VERSION "BodyCANhs"

NS_ :

BS_:

BU_: CCM CEM DDM ETC PAM PDM POT PSMD PSMP TRM VCM Y20CCMV526M1 Vector_XXX

BO_ 1456 CcmBodyDevFr01: 8 CCM
 SG_ EndOfLineSigEquipInp : 7|32@0+ (1,0) [0|4294967295] ""  ETC
 SG_ EndOfLineSigEquipInp1 : 39|32@0+ (1,0) [0|4294967295] ""  ETC

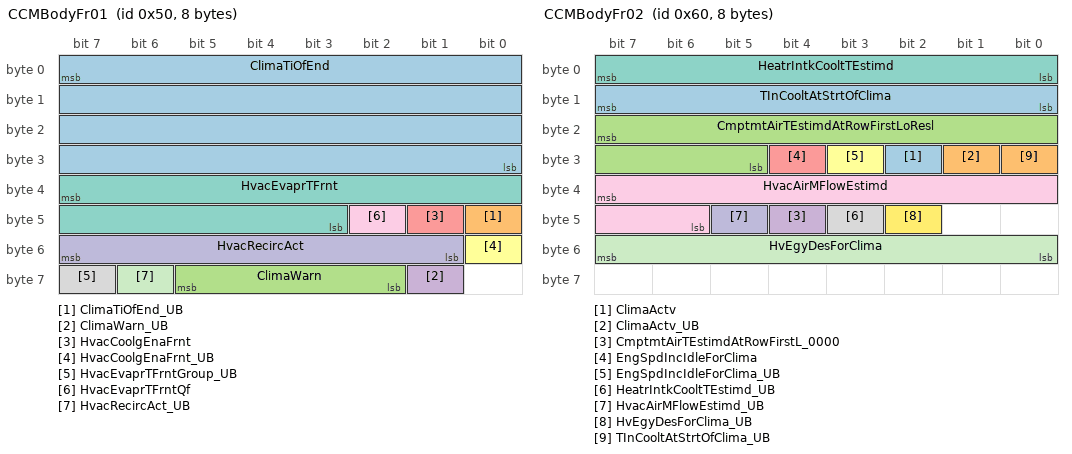
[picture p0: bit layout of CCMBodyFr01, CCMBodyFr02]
BO_ 80 CCMBodyFr01: 8 CCM
 SG_ ClimaTiOfEnd : 7|32@0+ (0.1,0) [0|429496729.5] "s"  CEM
 SG_ ClimaTiOfEnd_UB : 40|1@0+ (1,0) [0|1] ""  CEM
 SG_ ClimaWarn : 61|4@0+ (1,0) [0|15] ""  CEM,VCM
 SG_ ClimaWarn_UB : 57|1@0+ (1,0) [0|1] ""  CEM,VCM
 SG_ HvacCoolgEnaFrnt : 41|1@0+ (1,0) [0|1] ""  CEM
 SG_ HvacCoolgEnaFrnt_UB : 48|1@0+ (1,0) [0|1] ""  CEM
 SG_ HvacEvaprTFrnt : 39|13@0- (0.1,0) [-256|255.9] "degC"  CEM
 SG_ HvacEvaprTFrntGroup_UB : 63|1@0+ (1,0) [0|1] ""  CEM
 SG_ HvacEvaprTFrntQf : 42|1@0+ (1,0) [0|1] ""  CEM
 SG_ HvacRecircAct : 55|7@0+ (1,0) [0|100] "%"  CEM
 SG_ HvacRecircAct_UB : 62|1@0+ (1,0) [0|1] ""  CEM

BO_ 96 CCMBodyFr02: 8 CCM
 SG_ ClimaActv : 26|1@0+ (1,0) [0|1] ""  CEM,VCM
 SG_ ClimaActv_UB : 25|1@0+ (1,0) [0|1] ""  CEM,VCM
 SG_ CmptmtAirTEstimdAtRowFirstLoResl : 23|11@0+ (0.1,-60) [-60|125] "degC"  CEM
 SG_ CmptmtAirTEstimdAtRowFirstL_0000 : 44|1@0+ (1,0) [0|1] ""  CEM
 SG_ EngSpdIncIdleForClima : 28|1@0+ (1,0) [0|1] ""  CEM
 SG_ EngSpdIncIdleForClima_UB : 27|1@0+ (1,0) [0|1] ""  CEM
 SG_ HeatrIntkCooltTEstimd : 7|8@0+ (1,-40) [-40|215] "degC"  CEM
 SG_ HeatrIntkCooltTEstimd_UB : 43|1@0+ (1,0) [0|1] ""  CEM
 SG_ HvacAirMFlowEstimd : 39|10@0+ (1,0) [0|1000] "Kg / h"  CEM
 SG_ HvacAirMFlowEstimd_UB : 45|1@0+ (1,0) [0|1] ""  CEM
 SG_ HvEgyDesForClima : 55|8@0+ (50,0) [0|12750] "Wh"  CEM
 SG_ HvEgyDesForClima_UB : 42|1@0+ (1,0) [0|1] ""  CEM
 SG_ TInCooltAtStrtOfClima : 15|8@0+ (1,-40) [-40|215] "degC"  CEM
 SG_ TInCooltAtStrtOfClima_UB : 24|1@0+ (1,0) [0|1] ""  CEM

BO_ 336 CCMBodyFr03: 8 CCM
 SG_ AmbTEstimd_UB : 11|1@0+ (1,0) [0|1] ""  CEM
 SG_ AmbTEstimdAmbTEstimd : 7|11@0+ (0.1,-70) [-70|134.7] "degC"  CEM
 SG_ AmbTEstimdAmbTEstimdQf : 12|1@0+ (1,0) [0|1] ""  CEM
 SG_ ClimaSts : 31|1@0+ (1,0) [0|1] ""  CEM
 SG_ ClimaSts_UB : 30|1@0+ (1,0) [0|1] ""  CEM
 SG_ DefrstReq_UB : 10|1@0+ (1,0) [0|1] ""  CEM
 SG_ FuHeatrFuCns1 : 23|8@0+ (200,0) [0|51000] "MicroL"  CEM
 SG_ FuHeatrFuCns1_UB : 9|1@0+ (1,0) [0|1] ""  CEM
 SG_ HvHeatgPwrCritDes : 55|10@0+ (20,0) [0|20460] "W"  CEM
 SG_ HvHeatgPwrCritDes_UB : 61|1@0+ (1,0) [0|1] ""  CEM
 SG_ MirrDefrstReq : 26|1@0+ (1,0) [0|1] ""  CEM
 SG_ PwrEstimdAtStbForClima : 34|11@0+ (1,0) [0|2047] "W"  CEM
 SG_ PwrEstimdAtStbForClima_UB : 35|1@0+ (1,0) [0|1] ""  CEM
 SG_ WinDefrstFrntReq : 25|1@0+ (1,0) [0|1] ""  CEM
 SG_ WinDefrstReReq : 24|1@0+ (1,0) [0|1] ""  CEM
 SG_ WindIceDetdFrnt : 29|1@0+ (1,0) [0|1] ""  CEM
 SG_ WindIceDetdFrnt_UB : 28|1@0+ (1,0) [0|1] ""  CEM
 SG_ WindIceDetdRe : 27|1@0+ (1,0) [0|1] ""  CEM
 SG_ WindIceDetdRe_UB : 8|1@0+ (1,0) [0|1] ""  CEM

BO_ 368 CCMBodyFr04: 8 CCM
 SG_ CooltFlowFromWtrPmpAux : 13|6@0+ (0.5,0) [0|20] "L / min"  CEM
 SG_ CooltFlowFromWtrPmpAux_UB : 63|1@0+ (1,0) [0|1] ""  CEM
 SG_ HeatrCooltT : 47|8@0+ (1,-40) [-40|215] "degC"  CEM
 SG_ HeatrCooltT_UB : 62|1@0+ (1,0) [0|1] ""  CEM
 SG_ HvacEvaprTSpFrnt : 55|8@0+ (0.1,-5) [-5|20] ""  CEM
 SG_ HvacEvaprTSpFrnt_UB : 61|1@0+ (1,0) [0|1] ""  CEM
 SG_ HvHeatgPwrCns : 7|10@0+ (20,0) [0|20460] "W"  CEM
 SG_ HvHeatgPwrCns_UB : 60|1@0+ (1,0) [0|1] ""  CEM
 SG_ HvHeatgPwrNormDes : 23|10@0+ (20,0) [0|20460] "W"  CEM
 SG_ HvHeatgPwrNormDes_UB : 59|1@0+ (1,0) [0|1] ""  CEM
 SG_ RlyCmftForClimaReq : 28|1@0+ (1,0) [0|1] ""  CEM
 SG_ RlyCmftForClimaReq_UB : 58|1@0+ (1,0) [0|1] ""  CEM
 SG_ UBoostReqByClima : 29|1@0+ (1,0) [0|1] ""  CEM
 SG_ UBoostReqByClima_UB : 57|1@0+ (1,0) [0|1] ""  CEM
 SG_ WindDewTUppr_UB : 56|1@0+ (1,0) [0|1] ""  CEM
 SG_ WindDewTUpprDewT : 26|11@0+ (0.1,-70) [-70|134.7] "degC"  CEM
 SG_ WindDewTUpprDewTQf : 27|1@0+ (1,0) [0|1] ""  CEM

BO_ 448 CCMBodyFr05: 8 CCM
 SG_ EngHeatgReq : 47|1@0+ (1,0) [0|1] ""  CEM
 SG_ EngHeatgReq_UB : 46|1@0+ (1,0) [0|1] ""  CEM
 SG_ EvaprVlvReSts : 11|3@0+ (1,0) [0|7] ""  CEM
 SG_ EvaprVlvReSts_UB : 8|1@0+ (1,0) [0|1] ""  CEM
 SG_ EvaprVlvReStsExtd_UB : 43|1@0+ (1,0) [0|1] ""  CEM
 SG_ EvaprVlvReStsExtdDiagcStsForCirc : 61|2@0+ (1,0) [0|3] ""  CEM
 SG_ EvaprVlvReStsExtdDiagcStsForShoT : 59|2@0+ (1,0) [0|3] ""  CEM
 SG_ EvaprVlvReStsExtdDiagcStsFo_0000 : 57|2@0+ (1,0) [0|3] ""  CEM
 SG_ FuTankPRelsForFuHeatrReq : 45|1@0+ (1,0) [0|1] ""  CEM
 SG_ FuTankPRelsForFuHeatrReq_UB : 44|1@0+ (1,0) [0|1] ""  CEM
 SG_ HvacAirMFlowReEstimd : 41|10@0+ (1,0) [0|1000] "Kg / h"  CEM
 SG_ HvacAirMFlowReEstimd_UB : 42|1@0+ (1,0) [0|1] ""  CEM
 SG_ HvacCooltFlowReq : 25|10@0+ (0.05,0) [0|51.15] "L / min"  CEM
 SG_ HvacCooltFlowReq_UB : 26|1@0+ (1,0) [0|1] ""  CEM
 SG_ HvacCooltVlvReqExt : 62|1@0+ (1,0) [0|1] ""  CEM
 SG_ HvacCooltVlvReqExt_UB : 63|1@0+ (1,0) [0|1] ""  CEM
 SG_ HvacCooltVlvSts : 29|3@0+ (1,0) [0|7] ""  CEM
 SG_ HvacCooltVlvSts_UB : 30|1@0+ (1,0) [0|1] ""  CEM
 SG_ HvacHeatrPwrCns : 23|7@0+ (100,0) [0|10000] "W"  CEM
 SG_ HvacHeatrPwrCns_UB : 16|1@0+ (1,0) [0|1] ""  CEM
 SG_ WindTGroup_UB : 31|1@0+ (1,0) [0|1] ""  CEM
 SG_ WindTWindT : 7|11@0+ (0.1,-70) [-70|134.7] "degC"  CEM
 SG_ WindTWindTQf : 12|1@0+ (1,0) [0|1] ""  CEM

BO_ 272 CCMBodyFr06: 8 CCM
 SG_ ClimaPwrCns : 39|11@0+ (1,0) [0|2047] "W"  CEM
 SG_ ClimaPwrCns_UB : 44|1@0+ (1,0) [0|1] ""  CEM
 SG_ ClimaPwrCritDes : 18|11@0+ (1,0) [0|2047] "W"  CEM
 SG_ ClimaPwrCritDes_UB : 5|1@0+ (1,0) [0|1] ""  CEM
 SG_ ClimaPwrNormDes : 42|11@0+ (1,0) [0|2047] "W"  CEM
 SG_ ClimaPwrNormDes_UB : 43|1@0+ (1,0) [0|1] ""  CEM
 SG_ EngRunngReqByClima : 57|2@0+ (1,0) [0|3] ""  CEM
 SG_ EngRunngReqByClima_UB : 58|1@0+ (1,0) [0|1] ""  CEM
 SG_ HvacCoolgEnaRe : 7|1@0+ (1,0) [0|1] ""  CEM
 SG_ HvacCoolgEnaRe_UB : 6|1@0+ (1,0) [0|1] ""  CEM
 SG_ LvlOfClimaCmft : 3|3@0+ (1,0) [0|7] ""  CEM
 SG_ LvlOfClimaCmft_UB : 0|1@0+ (1,0) [0|1] ""  CEM
 SG_ PwrChrgDetdForPrkgHeatrElec : 62|1@0+ (1,0) [0|1] ""  CEM
 SG_ PwrChrgDetdForPrkgHeatrElec_UB : 61|1@0+ (1,0) [0|1] ""  CEM
 SG_ SeatHeatgAutCdn : 60|1@0+ (1,0) [0|1] ""  CEM
 SG_ SeatHeatgAutCdn_UB : 59|1@0+ (1,0) [0|1] ""  CEM
 SG_ SteerWhlHeatgAllwd : 23|5@0+ (20,0) [0|500] "W"  CEM
 SG_ SteerWhlHeatgAllwd_UB : 4|1@0+ (1,0) [0|1] ""  CEM

BO_ 576 CCMBodyFr07: 8 CCM
 SG_ ClimaStrtTi : 39|32@0+ (0.1,0) [0|429496729.5] "s"  CEM
 SG_ ClimaStrtTi_UB : 24|1@0+ (1,0) [0|1] ""  CEM
 SG_ ClimaTmrSts : 15|1@0+ (1,0) [0|1] ""  CEM
 SG_ ClimaTmrSts_UB : 14|1@0+ (1,0) [0|1] ""  CEM
 SG_ CoolgStsForDisp : 2|2@0+ (1,0) [0|3] ""  CEM
 SG_ CoolgStsForDisp_UB : 0|1@0+ (1,0) [0|1] ""  CEM
 SG_ CustClimaOvrdNotifForHmiCpt : 13|1@0+ (1,0) [0|1] ""  CEM
 SG_ CustClimaOvrdNotifForHmiCpt_UB : 12|1@0+ (1,0) [0|1] ""  CEM
 SG_ EgyDesForClima : 22|7@0+ (1,0) [0|127] "Wh"  CEM
 SG_ EgyDesForClima_UB : 23|1@0+ (1,0) [0|1] ""  CEM
 SG_ FuHeatrActv : 11|1@0+ (1,0) [0|1] ""  CEM
 SG_ FuHeatrActv_UB : 10|1@0+ (1,0) [0|1] ""  CEM
 SG_ FuHeatrFuCnsDurgCyc1 : 31|7@0+ (0.01,0) [0|1.27] "Litre"  CEM
 SG_ FuHeatrFuCnsDurgCyc1_UB : 7|1@0+ (1,0) [0|1] ""  CEM
 SG_ PostDrvgClimaAvl : 6|1@0+ (1,0) [0|1] ""  CEM
 SG_ PostDrvgClimaAvl_UB : 5|1@0+ (1,0) [0|1] ""  CEM
 SG_ RlyCrashForClimaReq : 4|1@0+ (1,0) [0|1] ""  CEM
 SG_ RlyCrashForClimaReq_UB : 3|1@0+ (1,0) [0|1] ""  CEM
 SG_ SteerWhlHeatgDurgClima : 9|1@0+ (1,0) [0|1] ""  CEM
 SG_ SteerWhlHeatgDurgClima_UB : 8|1@0+ (1,0) [0|1] ""  CEM

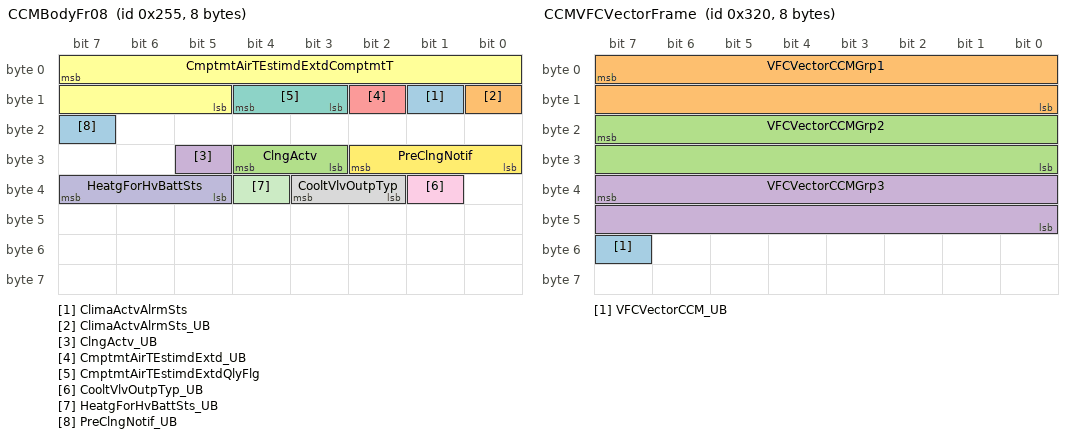
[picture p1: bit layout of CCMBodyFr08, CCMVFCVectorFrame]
BO_ 597 CCMBodyFr08: 8 CCM
 SG_ ClimaActvAlrmSts : 9|1@0+ (1,0) [0|1] ""  CEM
 SG_ ClimaActvAlrmSts_UB : 8|1@0+ (1,0) [0|1] ""  CEM
 SG_ ClngActv : 28|2@0+ (1,0) [0|3] ""  CEM,VCM
 SG_ ClngActv_UB : 29|1@0+ (1,0) [0|1] ""  CEM,VCM
 SG_ CmptmtAirTEstimdExtd_UB : 10|1@0+ (1,0) [0|1] ""  CEM
 SG_ CmptmtAirTEstimdExtdComptmtT : 7|11@0+ (0.1,-60) [-60|125] "degC"  CEM
 SG_ CmptmtAirTEstimdExtdQlyFlg : 12|2@0+ (1,0) [0|3] ""  CEM
 SG_ CooltVlvOutpTyp : 35|2@0+ (1,0) [0|3] ""  CEM
 SG_ CooltVlvOutpTyp_UB : 33|1@0+ (1,0) [0|1] ""  CEM
 SG_ HeatgForHvBattSts : 39|3@0+ (1,0) [0|7] ""  CEM
 SG_ HeatgForHvBattSts_UB : 36|1@0+ (1,0) [0|1] ""  CEM
 SG_ PreClngNotif : 26|3@0+ (1,0) [0|7] ""  CEM,VCM
 SG_ PreClngNotif_UB : 23|1@0+ (1,0) [0|1] ""  CEM,VCM

BO_ 1282 CcmBodyNMFr: 8 CCM
 SG_ PNC23_Spare1_CCM : 39|1@0+ (1,0) [0|0] ""  ETC
 SG_ PNC22_Spare2_CCM : 38|1@0+ (1,0) [0|0] ""  ETC
 SG_ PNC21_Spare3_CCM : 37|1@0+ (1,0) [0|0] ""  ETC
 SG_ PNC20_Spare4_CCM : 36|1@0+ (1,0) [0|0] ""  ETC
 SG_ PNC19_Spare5_CCM : 35|1@0+ (1,0) [0|0] ""  ETC
 SG_ PNC18_Spare6_CCM : 34|1@0+ (1,0) [0|0] ""  ETC
 SG_ PNC17_Spare7_CCM : 33|1@0+ (1,0) [0|0] ""  ETC
 SG_ PNC16_Diesel_CCM : 32|1@0+ (1,0) [0|0] ""  ETC
 SG_ PNC15_DriverInfoPoll_CCM : 31|1@0+ (1,0) [0|0] ""  ETC
 SG_ PNC14_GSD_CCM : 30|1@0+ (1,0) [0|0] ""  ETC
 SG_ PNC13_Global_CCM : 29|1@0+ (1,0) [0|0] ""  ETC
 SG_ PNC12_TrailerCaravan_CCM : 28|1@0+ (1,0) [0|0] ""  ETC
 SG_ PNC11_Driving_CCM : 27|1@0+ (1,0) [0|0] ""  ETC
 SG_ PNC10_PreClimatization_CCM : 26|1@0+ (1,0) [0|0] ""  ETC
 SG_ PNC9_Charging_CCM : 25|1@0+ (1,0) [0|0] ""  ETC
 SG_ PNC8_Start_CCM : 24|1@0+ (1,0) [0|0] ""  ETC
 SG_ PNC7_Entrance_CCM : 23|1@0+ (1,0) [0|0] ""  ETC
 SG_ PNC6_InfotainmentHMI_CCM : 22|1@0+ (1,0) [0|0] ""  ETC
 SG_ PNC5_Body_CCM : 21|1@0+ (1,0) [0|0] ""  ETC
 SG_ PNC4_Visibility_CCM : 20|1@0+ (1,0) [0|0] ""  ETC
 SG_ PNC3_WarningSounds_CCM : 19|1@0+ (1,0) [0|0] ""  ETC
 SG_ PNC2_Hazard_CCM : 18|1@0+ (1,0) [0|0] ""  ETC
 SG_ PNC1_Locking_CCM : 17|1@0+ (1,0) [0|0] ""  ETC
 SG_ PNC0_DriverInfo_CCM : 16|1@0+ (1,0) [0|0] ""  ETC
 SG_ NM_AW_CCM : 12|1@0+ (1,0) [0|0] ""  ETC
 SG_ NM_CS_CCM : 11|1@0+ (1,0) [0|0] ""  ETC
 SG_ NM_RMR_CCM : 8|1@0+ (1,0) [0|0] ""  ETC
 SG_ NM_PNI_CCM : 14|1@0+ (1,0) [0|0] ""  ETC
 SG_ NM_NodeID_CCM : 7|8@0+ (1,0) [0|0] ""  ETC

BO_ 1553 CcmToCemBodyDiagResFrame: 8 CCM

BO_ 1409 CCMtoETCXCPFr01: 8 CCM

BO_ 1410 CCMtoETCXCPFr02: 8 CCM

BO_ 1411 CCMtoETCXCPFr03: 8 CCM

BO_ 1412 CCMtoETCXCPFr04: 8 CCM

BO_ 800 CCMVFCVectorFrame: 8 CCM
 SG_ VFCVectorCCM_UB : 55|1@0+ (1,0) [0|1] ""  CEM
 SG_ VFCVectorCCMGrp1 : 7|16@0+ (1,0) [0|65535] ""  CEM
 SG_ VFCVectorCCMGrp2 : 23|16@0+ (1,0) [0|65535] ""  CEM
 SG_ VFCVectorCCMGrp3 : 39|16@0+ (1,0) [0|65535] ""  CEM

BO_ 1122 CCMY20BodyFr01: 8 Y20CCMV526M1
 SG_ HmiCmptmtAirDistbnFrntM1 : 47|3@0+ (1,0) [0|7] ""  Vector_XXX
 SG_ HmiCmptmtAirDistbnFrntM1_UB : 24|1@0+ (1,0) [0|1] ""  Vector_XXX
 SG_ HmiCmptmtCoolgReqM1 : 44|1@0+ (1,0) [0|1] ""  Vector_XXX
 SG_ HmiCmptmtCoolgReqM1_UB : 43|1@0+ (1,0) [0|1] ""  Vector_XXX
 SG_ HmiCmptmtTSpForRowFirstLeM1 : 7|5@0+ (0.5,15) [15|30.5] "Deg"  Vector_XXX
 SG_ HmiCmptmtTSpForRowFirstRiM1 : 15|5@0+ (0.5,15) [15|30.5] "Deg"  Vector_XXX
 SG_ HmiCmptmtTSpForRowSecLeM1 : 23|5@0+ (0.5,15) [15|30.5] "Deg"  Vector_XXX
 SG_ HmiCmptmtTSpForRowSecRiM1 : 31|5@0+ (0.5,15) [15|30.5] "Deg"  Vector_XXX
 SG_ HmiCmptmtTSpM1_UB : 42|1@0+ (1,0) [0|1] ""  Vector_XXX
 SG_ HmiCmptmtTSpSpclForRowFirstLeM1 : 2|2@0+ (1,0) [0|3] ""  Vector_XXX
 SG_ HmiCmptmtTSpSpclForRowFirstRiM1 : 10|2@0+ (1,0) [0|3] ""  Vector_XXX
 SG_ HmiCmptmtTSpSpclForRowSecLeM1 : 18|2@0+ (1,0) [0|3] ""  Vector_XXX
 SG_ HmiCmptmtTSpSpclForRowSecRiM1 : 26|2@0+ (1,0) [0|3] ""  Vector_XXX
 SG_ HmiDefrstMaxReqM1 : 33|2@0+ (1,0) [0|3] ""  Vector_XXX
 SG_ HmiDefrstMaxReqM1_UB : 41|1@0+ (1,0) [0|1] ""  Vector_XXX
 SG_ HmiHvacFanLvlFrntM1 : 39|4@0+ (1,0) [0|15] ""  Vector_XXX
 SG_ HmiHvacFanLvlFrntM1_UB : 40|1@0+ (1,0) [0|1] ""  Vector_XXX
 SG_ HmiHvacRecircCmdM1 : 35|2@0+ (1,0) [0|3] ""  Vector_XXX
 SG_ HmiHvacRecircCmdM1_UB : 55|1@0+ (1,0) [0|1] ""  Vector_XXX

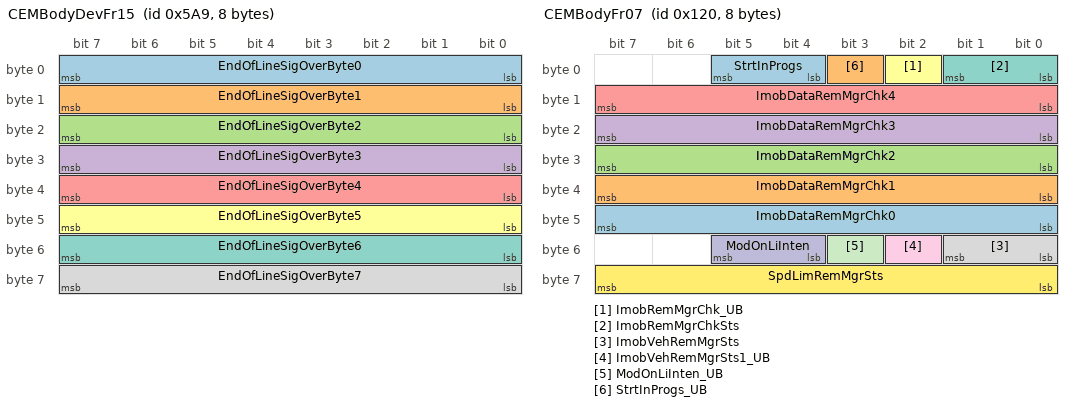
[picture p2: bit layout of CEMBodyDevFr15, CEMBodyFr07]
BO_ 1449 CEMBodyDevFr15: 8 CEM
 SG_ EndOfLineSigOverByte0 : 7|8@0+ (1,0) [0|255] ""  ETC
 SG_ EndOfLineSigOverByte1 : 15|8@0+ (1,0) [0|255] ""  ETC
 SG_ EndOfLineSigOverByte2 : 23|8@0+ (1,0) [0|255] ""  ETC
 SG_ EndOfLineSigOverByte3 : 31|8@0+ (1,0) [0|255] ""  ETC
 SG_ EndOfLineSigOverByte4 : 39|8@0+ (1,0) [0|255] ""  ETC
 SG_ EndOfLineSigOverByte5 : 47|8@0+ (1,0) [0|255] ""  ETC
 SG_ EndOfLineSigOverByte6 : 55|8@0+ (1,0) [0|255] ""  ETC
 SG_ EndOfLineSigOverByte7 : 63|8@0+ (1,0) [0|255] ""  ETC

BO_ 32 CEMBodyFr01: 8 CEM
 SG_ ActvnOfHndlDoorLi_UB : 47|1@0+ (1,0) [0|1] ""  DDM,PDM
 SG_ ActvnOfTrlrBrkLi : 60|1@0+ (1,0) [0|1] ""  TRM
 SG_ ActvnOfTrlrBrkLi_UB : 59|1@0+ (1,0) [0|1] ""  TRM
 SG_ DoorDrvrIntrSwtLedLockgReCmd : 14|1@0+ (1,0) [0|1] ""  DDM
 SG_ DoorDrvrIntrSwtLedLockgReCmd_UB : 13|1@0+ (1,0) [0|1] ""  DDM
 SG_ DoorDrvrLockCmd : 7|4@0+ (1,0) [0|15] ""  DDM
 SG_ DoorDrvrLockCmd_UB : 3|1@0+ (1,0) [0|1] ""  DDM
 SG_ DoorDrvrLockReCmd : 11|4@0+ (1,0) [0|15] ""  DDM
 SG_ DoorDrvrLockReCmd_UB : 12|1@0+ (1,0) [0|1] ""  DDM
 SG_ DoorPassIntrSwtLedLockgReCmd : 37|1@0+ (1,0) [0|1] ""  PDM
 SG_ DoorPassIntrSwtLedLockgReCmd_UB : 36|1@0+ (1,0) [0|1] ""  PDM
 SG_ DoorPassLockCmd : 23|4@0+ (1,0) [0|15] ""  PDM
 SG_ DoorPassLockCmd_UB : 19|1@0+ (1,0) [0|1] ""  PDM
 SG_ DoorPassLockReCmd : 31|4@0+ (1,0) [0|15] ""  PDM
 SG_ DoorPassLockReCmd_UB : 16|1@0+ (1,0) [0|1] ""  PDM
 SG_ EveMemPosn : 51|3@0+ (1,0) [0|7] ""  DDM,PDM,PSMD
 SG_ HndlDoorLiDrvr : 35|1@0+ (1,0) [0|1] ""  DDM,PDM
 SG_ HndlDoorLiDrvrRe : 34|1@0+ (1,0) [0|1] ""  DDM,PDM
 SG_ HndlDoorLiPass : 33|1@0+ (1,0) [0|1] ""  DDM,PDM
 SG_ HndlDoorLiPassRe : 32|1@0+ (1,0) [0|1] ""  DDM,PDM
 SG_ HvCooltHeatrEnad : 39|1@0+ (1,0) [0|1] ""  CCM
 SG_ HvCooltHeatrEnad_UB : 38|1@0+ (1,0) [0|1] ""  CCM
 SG_ IndcrTurnCmd1WdCmd_UB : 15|1@0+ (1,0) [0|1] ""  DDM,PDM,TRM
 SG_ IndcrTurnCmd1WdHzrdTelltl : 0|1@0+ (1,0) [0|1] ""  DDM,PDM,TRM
 SG_ IndcrTurnCmd1WdIndcrTrig : 2|2@0+ (1,0) [0|3] ""  DDM,PDM,TRM
 SG_ IndcrTurnSts1WdSts : 58|2@0+ (1,0) [0|3] ""  DDM,PDM,TRM
 SG_ IndcrTurnSts1WdSts_UB : 56|1@0+ (1,0) [0|1] ""  DDM,PDM,TRM
 SG_ IntrLiActvn1 : 26|1@0+ (1,0) [0|1] ""  DDM,PDM
 SG_ IntrLiCmdGroup_UB : 27|1@0+ (1,0) [0|1] ""  DDM,PDM
 SG_ IntrLiDmdOff : 18|1@0+ (1,0) [0|1] ""  DDM,PDM
 SG_ IntrLiDmdOff_UB : 17|1@0+ (1,0) [0|1] ""  DDM,PDM
 SG_ IntrLiRoofDim : 25|1@0+ (1,0) [0|1] ""  DDM,PDM
 SG_ IntrLiRoofDmdOff : 24|1@0+ (1,0) [0|1] ""  DDM,PDM
 SG_ LoadAndStoreReq_UB : 61|1@0+ (1,0) [0|1] ""  DDM,PDM,PSMD
 SG_ LoadAndStoreReqIdPen : 55|4@0+ (1,0) [0|15] ""  DDM,PDM,PSMD
 SG_ LoadAndStoreReqInOutEasy : 48|1@0+ (1,0) [0|1] ""  DDM,PDM,PSMD
 SG_ MemPosn : 63|2@0+ (1,0) [0|3] ""  DDM,PDM,PSMD

BO_ 64 CEMBodyFr02: 8 CEM
 SG_ ClimaRqrd : 47|2@0+ (1,0) [0|3] ""  CCM
 SG_ ClimaRqrd_UB : 45|1@0+ (1,0) [0|1] ""  CCM
 SG_ CllsnWarnIndcnLe : 60|2@0+ (1,0) [0|3] ""  DDM,PDM
 SG_ CllsnWarnIndcnLe_UB : 61|1@0+ (1,0) [0|1] ""  DDM,PDM
 SG_ CllsnWarnIndcnRi : 57|2@0+ (1,0) [0|3] ""  DDM,PDM
 SG_ CllsnWarnIndcnRi_UB : 58|1@0+ (1,0) [0|1] ""  DDM,PDM
 SG_ DoorDrvrIntrSwtLedLockgCmd : 31|1@0+ (1,0) [0|1] ""  DDM
 SG_ DoorDrvrIntrSwtLedLockgCmd_UB : 30|1@0+ (1,0) [0|1] ""  DDM
 SG_ DoorDrvrReSts : 43|2@0+ (1,0) [0|3] ""  CCM,DDM,PSMD,TRM,VCM
 SG_ DoorDrvrReSts_UB : 44|1@0+ (1,0) [0|1] ""  CCM,DDM,PSMD,TRM,VCM
 SG_ DoorDrvrSts : 55|2@0+ (1,0) [0|3] ""  CCM,DDM,PDM,PSMD,TRM
 SG_ DoorDrvrSts_UB : 53|1@0+ (1,0) [0|1] ""  CCM,DDM,PDM,PSMD,TRM
 SG_ DoorPassIntrSwtLedLockgCmd : 39|1@0+ (1,0) [0|1] ""  PDM
 SG_ DoorPassIntrSwtLedLockgCmd_UB : 38|1@0+ (1,0) [0|1] ""  PDM
 SG_ GlbWinCmd : 34|3@0+ (1,0) [0|7] ""  CCM,DDM,PDM
 SG_ GlbWinCmd_UB : 35|1@0+ (1,0) [0|1] ""  CCM,DDM,PDM
 SG_ LcmaIndcnLe : 51|2@0+ (1,0) [0|3] ""  DDM,PDM
 SG_ LcmaIndcnLe_UB : 52|1@0+ (1,0) [0|1] ""  DDM,PDM
 SG_ LcmaIndcnRi : 63|2@0+ (1,0) [0|3] ""  DDM,PDM
 SG_ LcmaIndcnRi_UB : 36|1@0+ (1,0) [0|1] ""  DDM,PDM
 SG_ PassLoadAndStoreReq_UB : 29|1@0+ (1,0) [0|1] ""  PSMP
 SG_ PassLoadAndStoreReqErgoPosn : 28|2@0+ (1,0) [0|3] ""  PSMP
 SG_ PassLoadAndStoreReqErgoSetgEve : 26|3@0+ (1,0) [0|7] ""  PSMP
 SG_ SaveSetgToMemPrmnt : 49|2@0+ (1,0) [0|3] ""  DDM,PDM,PSMD
 SG_ SaveSetgToMemPrmnt_UB : 37|1@0+ (1,0) [0|1] ""  DDM,PDM,PSMD
 SG_ TrNoKeyPrsntAcoustReq : 41|1@0+ (1,0) [0|1] ""  POT
 SG_ TrNoKeyPrsntAcoustReq_UB : 40|1@0+ (1,0) [0|1] ""  POT
 SG_ TrOpenerReq_UB : 21|1@0+ (1,0) [0|1] ""  POT
 SG_ TrOpenerReqTrOpenerReq : 20|2@0+ (1,0) [0|3] ""  POT
 SG_ TrOpenerReqTrOpenerTrigSrc : 18|3@0+ (1,0) [0|7] ""  POT
 SG_ TwliBriSts : 23|1@0+ (1,0) [0|1] ""  DDM,PDM,TRM,VCM
 SG_ TwliBriSts_UB : 22|1@0+ (1,0) [0|1] ""  DDM,PDM,TRM,VCM
 SG_ VehMtnStChks : 15|8@0+ (1,0) [0|255] ""  POT,TRM
 SG_ VehMtnStCntr : 6|4@0+ (1,0) [0|15] ""  POT,TRM
 SG_ VehMtnStSafe : 2|3@0+ (1,0) [0|7] ""  POT,TRM
 SG_ VehMtnStSafeGroup_UB : 7|1@0+ (1,0) [0|1] ""  POT,TRM

BO_ 243 CEMBodyFr03: 4 CEM
 SG_ CrashSts2 : 1|2@0+ (1,0) [0|3] ""  VCM
 SG_ CrashSts2_UB : 2|1@0+ (1,0) [0|1] ""  VCM

BO_ 245 CEMBodyFr04: 8 CEM
 SG_ RecOfImpctSafeChks : 7|8@0+ (1,0) [0|255] ""  VCM
 SG_ RecOfImpctSafeCntr : 15|4@0+ (1,0) [0|15] ""  VCM
 SG_ RecOfImpctSafeCrashFrnt : 11|2@0+ (1,0) [0|3] ""  VCM
 SG_ RecOfImpctSafeCrashLargeAnimal : 9|2@0+ (1,0) [0|3] ""  VCM
 SG_ RecOfImpctSafeCrashOffroadA : 23|2@0+ (1,0) [0|3] ""  VCM
 SG_ RecOfImpctSafeCrashOffroadD : 21|2@0+ (1,0) [0|3] ""  VCM
 SG_ RecOfImpctSafeCrashOffroadRT : 19|2@0+ (1,0) [0|3] ""  VCM
 SG_ RecOfImpctSafeCrashOffroadRTseve : 17|2@0+ (1,0) [0|3] ""  VCM
 SG_ RecOfImpctSafeCrashOz : 31|2@0+ (1,0) [0|3] ""  VCM
 SG_ RecOfImpctSafeCrashPed : 29|2@0+ (1,0) [0|3] ""  VCM
 SG_ RecOfImpctSafeCrashRe : 27|2@0+ (1,0) [0|3] ""  VCM
 SG_ RecOfImpctSafeCrashRollovr : 25|2@0+ (1,0) [0|3] ""  VCM
 SG_ RecOfImpctSafeCrashSideLe : 39|2@0+ (1,0) [0|3] ""  VCM
 SG_ RecOfImpctSafeCrashSideRi : 37|2@0+ (1,0) [0|3] ""  VCM
 SG_ RecOfImpctSafeCrashState : 35|2@0+ (1,0) [0|3] ""  VCM
 SG_ RecOfImpctSafeImpctDvx : 55|8@0+ (1,0) [0|255] ""  VCM
 SG_ RecOfImpctSafeImpctDvy : 63|8@0+ (1,0) [0|255] ""  VCM
 SG_ RecOfImpctSafeImpctRollAg : 33|7@0+ (15,0) [0|1905] ""  VCM
 SG_ RecOfImpctSafeVehOri : 42|3@0+ (1,0) [0|7] ""  VCM

BO_ 176 CEMBodyFr05: 8 CEM
 SG_ BltLockStAtDrvr_UB : 58|1@0+ (1,0) [0|1] ""  CCM,VCM
 SG_ BltLockStAtDrvrForBltLockSt1 : 57|1@0+ (1,0) [0|1] ""  CCM,VCM
 SG_ BltLockStAtDrvrForDevErrSts2 : 56|1@0+ (1,0) [0|1] ""  CCM,VCM
 SG_ BltLockStAtPass_UB : 42|1@0+ (1,0) [0|1] ""  CCM,VCM
 SG_ BltLockStAtPassForBltLockSt1 : 41|1@0+ (1,0) [0|1] ""  CCM,VCM
 SG_ BltLockStAtPassForBltLockSts : 40|1@0+ (1,0) [0|1] ""  CCM,VCM
 SG_ BltLockStAtRowSecLe_UB : 47|1@0+ (1,0) [0|1] ""  CCM,VCM
 SG_ BltLockStAtRowSecLeForBltLockEqu : 46|1@0+ (1,0) [0|1] ""  CCM,VCM
 SG_ BltLockStAtRowSecLeForBltLockSt1 : 45|1@0+ (1,0) [0|1] ""  CCM,VCM
 SG_ BltLockStAtRowSecLeForBltLockSts : 44|1@0+ (1,0) [0|1] ""  CCM,VCM
 SG_ BltLockStAtRowSecMid_UB : 39|1@0+ (1,0) [0|1] ""  CCM,VCM
 SG_ BltLockStAtRowSecMidForBltLockEq : 38|1@0+ (1,0) [0|1] ""  CCM,VCM
 SG_ BltLockStAtRowSecMidForBltLockSt : 37|1@0+ (1,0) [0|1] ""  CCM,VCM
 SG_ BltLockStAtRowSecMidForBltL_0000 : 36|1@0+ (1,0) [0|1] ""  CCM,VCM
 SG_ BltLockStAtRowSecRi_UB : 35|1@0+ (1,0) [0|1] ""  CCM,VCM
 SG_ BltLockStAtRowSecRiForBltLockEqu : 34|1@0+ (1,0) [0|1] ""  CCM,VCM
 SG_ BltLockStAtRowSecRiForBltLockSt1 : 33|1@0+ (1,0) [0|1] ""  CCM,VCM
 SG_ BltLockStAtRowSecRiForBltLockSts : 32|1@0+ (1,0) [0|1] ""  CCM,VCM
 SG_ BltLockStAtRowThrdLe_UB : 43|1@0+ (1,0) [0|1] ""  CCM,PSMD,VCM
 SG_ BltLockStAtRowThrdLeForBltLockEq : 50|1@0+ (1,0) [0|1] ""  CCM,PSMD,VCM
 SG_ BltLockStAtRowThrdLeForBltLockSt : 49|1@0+ (1,0) [0|1] ""  CCM,PSMD,VCM
 SG_ BltLockStAtRowThrdLeForBltL_0000 : 48|1@0+ (1,0) [0|1] ""  CCM,PSMD,VCM
 SG_ BltLockStAtRowThrdRi_UB : 27|1@0+ (1,0) [0|1] ""  CCM,PSMD,VCM
 SG_ BltLockStAtRowThrdRiForBltLockEq : 26|1@0+ (1,0) [0|1] ""  CCM,PSMD,VCM
 SG_ BltLockStAtRowThrdRiForBltLockSt : 25|1@0+ (1,0) [0|1] ""  CCM,PSMD,VCM
 SG_ BltLockStAtRowThrdRiForBltL_0000 : 24|1@0+ (1,0) [0|1] ""  CCM,PSMD,VCM
 SG_ BrkFldLvl : 29|1@0+ (1,0) [0|1] ""  VCM
 SG_ BrkFldLvl_UB : 28|1@0+ (1,0) [0|1] ""  VCM
 SG_ ChrgnTyp : 15|8@0+ (1,0) [0|255] ""  VCM
 SG_ ChrgnTyp_UB : 51|1@0+ (1,0) [0|1] ""  VCM
 SG_ EngCooltLvl : 31|1@0+ (1,0) [0|1] ""  Vector_XXX
 SG_ EngCooltLvl_UB : 30|1@0+ (1,0) [0|1] ""  Vector_XXX
 SG_ ErsStrtApplSts : 55|2@0+ (1,0) [0|3] ""  VCM
 SG_ ErsStrtApplSts_UB : 53|1@0+ (1,0) [0|1] ""  VCM
 SG_ HvEgyCnsAllwdForClima : 7|8@0+ (50,0) [0|12750] "Wh"  CCM
 SG_ HvEgyCnsAllwdForClima_UB : 52|1@0+ (1,0) [0|1] ""  CCM

BO_ 288 CEMBodyFr07: 8 CEM
 SG_ ImobDataRemMgrChk0 : 47|8@0+ (1,0) [0|255] ""  VCM
 SG_ ImobDataRemMgrChk1 : 39|8@0+ (1,0) [0|255] ""  VCM
 SG_ ImobDataRemMgrChk2 : 31|8@0+ (1,0) [0|255] ""  VCM
 SG_ ImobDataRemMgrChk3 : 23|8@0+ (1,0) [0|255] ""  VCM
 SG_ ImobDataRemMgrChk4 : 15|8@0+ (1,0) [0|255] ""  VCM
 SG_ ImobRemMgrChk_UB : 2|1@0+ (1,0) [0|1] ""  VCM
 SG_ ImobRemMgrChkSts : 1|2@0+ (1,0) [0|3] ""  VCM
 SG_ ImobVehRemMgrSts : 49|2@0+ (1,0) [0|3] ""  VCM
 SG_ ImobVehRemMgrSts1_UB : 50|1@0+ (1,0) [0|1] ""  VCM
 SG_ ModOnLiInten : 53|2@0+ (1,0) [0|3] ""  DDM,PDM
 SG_ ModOnLiInten_UB : 51|1@0+ (1,0) [0|1] ""  DDM,PDM
 SG_ SpdLimRemMgrSts : 63|8@0+ (1,0) [0|255] ""  VCM
 SG_ StrtInProgs : 5|2@0+ (1,0) [0|3] ""  CCM
 SG_ StrtInProgs_UB : 3|1@0+ (1,0) [0|1] ""  CCM

BO_ 224 CEMBodyFr11: 8 CEM
 SG_ ActvnOfTrlrFogLiCmd : 59|1@0+ (1,0) [0|1] ""  TRM
 SG_ ActvnOfTrlrFogLiCmd_UB : 60|1@0+ (1,0) [0|1] ""  TRM
 SG_ CmptmtClngPreStrtReq : 11|2@0+ (1,0) [0|3] ""  CCM
 SG_ CmptmtClngPreStrtReq_UB : 9|1@0+ (1,0) [0|1] ""  CCM
 SG_ DoorPassReSts : 13|2@0+ (1,0) [0|3] ""  CCM,PDM,PSMD,TRM,VCM
 SG_ DoorPassReSts_UB : 14|1@0+ (1,0) [0|1] ""  CCM,PDM,PSMD,TRM,VCM
 SG_ DoorPassSts : 31|2@0+ (1,0) [0|3] ""  CCM,DDM,PDM,PSMD,TRM,VCM
 SG_ DoorPassSts_UB : 29|1@0+ (1,0) [0|1] ""  CCM,DDM,PDM,PSMD,TRM,VCM
 SG_ DrvrSeatDispMassgFct_UB : 15|1@0+ (1,0) [0|1] ""  PSMD
 SG_ DrvrSeatDispMassgFctMassgInten : 1|2@0+ (1,0) [0|3] ""  PSMD
 SG_ DrvrSeatDispMassgFctMassgProg : 4|3@0+ (1,0) [0|7] ""  PSMD
 SG_ DrvrSeatDispMassgFctMassgSpdLvl : 6|2@0+ (1,0) [0|3] ""  PSMD
 SG_ DrvrSeatDispMassgFctOnOff : 7|1@0+ (1,0) [0|1] ""  PSMD
 SG_ HvPwrAvlForClimaEstimd : 25|10@0+ (20,0) [0|20460] "W"  CCM
 SG_ HvPwrAvlForClimaEstimd_UB : 26|1@0+ (1,0) [0|1] ""  CCM
 SG_ IntrBriSts : 43|4@0+ (1,0) [0|15] ""  DDM,PDM,VCM
 SG_ IntrBriSts_UB : 44|1@0+ (1,0) [0|1] ""  DDM,PDM,VCM
 SG_ MirrTintgCmd : 54|7@0+ (1,0) [0|100] "%"  DDM,PDM
 SG_ MirrTintgCmd_UB : 55|1@0+ (1,0) [0|1] ""  DDM,PDM
 SG_ PassSeatDispMassgFct_UB : 8|1@0+ (1,0) [0|1] ""  PSMP
 SG_ PassSeatDispMassgFctMassgInten : 23|2@0+ (1,0) [0|3] ""  PSMP
 SG_ PassSeatDispMassgFctMassgProg : 19|3@0+ (1,0) [0|7] ""  PSMP
 SG_ PassSeatDispMassgFctMassgSpdLvl : 21|2@0+ (1,0) [0|3] ""  PSMP
 SG_ PassSeatDispMassgFctOnOff : 16|1@0+ (1,0) [0|1] ""  PSMP
 SG_ TrlrLampChkReq : 63|2@0+ (1,0) [0|3] ""  TRM
 SG_ TrlrLampChkReq_UB : 61|1@0+ (1,0) [0|1] ""  TRM
 SG_ TrPosnUpprProgmReq : 28|1@0+ (1,0) [0|1] ""  POT
 SG_ TrPosnUpprProgmReq_UB : 27|1@0+ (1,0) [0|1] ""  POT
 SG_ TrSts : 47|2@0+ (1,0) [0|3] ""  CCM,PSMD,TRM,VCM
 SG_ TrSts_UB : 45|1@0+ (1,0) [0|1] ""  CCM,PSMD,TRM,VCM

BO_ 240 CEMBodyFr12: 8 CEM
 SG_ ActvnOfPosnReCmd : 45|2@0+ (1,0) [0|3] ""  TRM
 SG_ ActvnOfPosnReCmd_UB : 46|1@0+ (1,0) [0|1] ""  TRM
 SG_ ActvnOfWshrFrntSafe : 43|2@0+ (1,0) [0|3] ""  CCM
 SG_ ActvnOfWshrFrntSafe_UB : 47|1@0+ (1,0) [0|1] ""  CCM
 SG_ AsyFanSts : 62|1@0+ (1,0) [0|1] ""  CCM
 SG_ AsyFanSts_UB : 63|1@0+ (1,0) [0|1] ""  CCM
 SG_ CarModSts1 : 2|3@0+ (1,0) [0|7] ""  CCM,DDM,PDM,POT,PSMD,PSMP,TRM
 SG_ CarModSubtypWdCarModSubtyp : 5|3@0+ (1,0) [0|7] ""  CCM,DDM,PDM,POT,PSMD,PSMP,TRM
 SG_ DrvrCtrlOfPassSeatFrntReqd : 60|1@0+ (1,0) [0|1] ""  PSMD
 SG_ DrvrCtrlOfPassSeatFrntReqd_UB : 61|1@0+ (1,0) [0|1] ""  PSMD
 SG_ DrvrDesDir : 58|3@0+ (1,0) [0|7] ""  DDM
 SG_ DrvrDesDir_UB : 59|1@0+ (1,0) [0|1] ""  DDM
 SG_ EgyLvlElecMai : 27|4@0+ (1,0) [0|15] ""  CCM,DDM,PDM,POT,PSMD,PSMP,TRM
 SG_ EgyLvlElecSubtyp : 31|4@0+ (1,0) [0|15] ""  CCM,DDM,PDM,POT,PSMD,PSMP,TRM
 SG_ FltEgyCnsWdSts : 6|1@0+ (1,0) [0|1] ""  CCM,DDM,PDM,POT,PSMD,PSMP,TRM
 SG_ NetCtrlrActvt_UB : 41|1@0+ (1,0) [0|1] ""  Vector_XXX
 SG_ NetCtrlrActvtPrio : 40|1@0+ (1,0) [0|1] ""  Vector_XXX
 SG_ NetCtrlrActvtResourceGroup : 55|8@0+ (1,0) [0|255] ""  Vector_XXX
 SG_ PwrLvlElecMai : 19|4@0+ (1,0) [0|15] ""  CCM,DDM,PDM,POT,PSMD,PSMP,TRM
 SG_ PwrLvlElecSubtyp : 23|4@0+ (1,0) [0|15] ""  CCM,DDM,PDM,POT,PSMD,PSMP,TRM
 SG_ UsgModSts : 11|4@0+ (1,0) [0|15] ""  CCM,DDM,PDM,POT,PSMD,PSMP,TRM
 SG_ VehModMngtGlbSafe1_UB : 7|1@0+ (1,0) [0|1] ""  CCM,DDM,PDM,POT,PSMD,PSMP,TRM
 SG_ VehModMngtGlbSafe1Chks : 39|8@0+ (1,0) [0|255] ""  CCM,DDM,PDM,POT,PSMD,PSMP,TRM
 SG_ VehModMngtGlbSafe1Cntr : 15|4@0+ (1,0) [0|15] ""  CCM,DDM,PDM,POT,PSMD,PSMP,TRM

BO_ 256 CEMBodyFr13: 8 CEM
 SG_ CamHeatrActv : 6|1@0+ (1,0) [0|1] ""  CCM
 SG_ CamHeatrActv_UB : 7|1@0+ (1,0) [0|1] ""  CCM
 SG_ DefrstSts_UB : 30|1@0+ (1,0) [0|1] ""  CCM
 SG_ EngPAmbAir1 : 47|8@0+ (5,0) [0|1275] "hPa"  CCM,PSMD,PSMP
 SG_ EngPAmbAir1_UB : 36|1@0+ (1,0) [0|1] ""  CCM,PSMD,PSMP
 SG_ ExtrMirrFoldSetg_UB : 5|1@0+ (1,0) [0|1] ""  DDM
 SG_ ExtrMirrFoldSetgPen : 3|4@0+ (1,0) [0|15] ""  DDM
 SG_ ExtrMirrFoldSetgSts : 4|1@0+ (1,0) [0|1] ""  DDM
 SG_ ExtrMirrTiltSetg2_UB : 22|1@0+ (1,0) [0|1] ""  DDM
 SG_ ExtrMirrTiltSetg2IdPen : 19|4@0+ (1,0) [0|15] ""  DDM
 SG_ ExtrMirrTiltSetg2MirrDrvr : 20|1@0+ (1,0) [0|1] ""  DDM
 SG_ ExtrMirrTiltSetg2MirrPass : 21|1@0+ (1,0) [0|1] ""  DDM
 SG_ HoodSts : 49|2@0+ (1,0) [0|3] ""  VCM
 SG_ HoodSts_UB : 50|1@0+ (1,0) [0|1] ""  VCM
 SG_ LockgCenSts_UB : 8|1@0+ (1,0) [0|1] ""  CCM,DDM
 SG_ LockgCenStsForUsrFb : 34|3@0+ (1,0) [0|7] ""  VCM
 SG_ LockgCenStsForUsrFb_UB : 35|1@0+ (1,0) [0|1] ""  VCM
 SG_ LockgCenStsLockSt : 11|2@0+ (1,0) [0|3] ""  CCM,DDM
 SG_ LockgCenStsUpdEve : 9|1@0+ (1,0) [0|1] ""  CCM,DDM
 SG_ LockgCenTrigSrc : 15|4@0+ (1,0) [0|15] ""  CCM,DDM
 SG_ MirrDefrstSts : 29|3@0+ (1,0) [0|7] ""  CCM
 SG_ SteerWhlHeatgPwrAct : 63|5@0+ (20,0) [0|500] "W"  CCM
 SG_ SteerWhlHeatgPwrAct_UB : 58|1@0+ (1,0) [0|1] ""  CCM
 SG_ WindDefrstFrntSts : 26|3@0+ (1,0) [0|7] ""  CCM
 SG_ WinDefrstReSts : 39|3@0+ (1,0) [0|7] ""  CCM

BO_ 320 CEMBodyFr14: 8 CEM
 SG_ DispBattEgyIn : 15|8@0+ (0.5,0) [0|127.5] "Wh"  VCM
 SG_ DispBattEgyIn_UB : 0|1@0+ (1,0) [0|1] ""  VCM
 SG_ DispBattEgyOut : 23|8@0+ (0.5,0) [0|127.5] "Wh"  VCM
 SG_ DispBattEgyOut_UB : 1|1@0+ (1,0) [0|1] ""  VCM
 SG_ HmiCmptmtAirDistbnFrnt : 58|3@0+ (1,0) [0|7] ""  CCM
 SG_ HmiCmptmtAirDistbnFrnt_UB : 59|1@0+ (1,0) [0|1] ""  CCM
 SG_ HmiDefrstMaxReq : 47|2@0+ (1,0) [0|3] ""  CCM
 SG_ HmiDefrstMaxReq_UB : 45|1@0+ (1,0) [0|1] ""  CCM
 SG_ HmiHvacFanLvlFrnt : 7|4@0+ (1,0) [0|15] ""  CCM
 SG_ HmiHvacFanLvlFrnt_UB : 3|1@0+ (1,0) [0|1] ""  CCM
 SG_ HmiHvacFanLvlRe : 51|4@0+ (1,0) [0|15] ""  CCM
 SG_ HmiHvacFanLvlRe_UB : 55|1@0+ (1,0) [0|1] ""  CCM
 SG_ HmiHvacRecircCmd : 53|2@0+ (1,0) [0|3] ""  CCM
 SG_ HmiHvacRecircCmd_UB : 54|1@0+ (1,0) [0|1] ""  CCM
 SG_ HmiHvacReCtrl : 63|2@0+ (1,0) [0|3] ""  CCM
 SG_ HmiHvacReCtrl_UB : 61|1@0+ (1,0) [0|1] ""  CCM
 SG_ ModOnLiCmd : 29|1@0+ (1,0) [0|1] ""  DDM,PDM
 SG_ ModOnLiCmd_UB : 30|1@0+ (1,0) [0|1] ""  DDM,PDM
 SG_ ModOnLiTCmd : 28|5@0+ (1,0) [0|22] ""  DDM,PDM
 SG_ ModOnLiTCmd_UB : 60|1@0+ (1,0) [0|1] ""  DDM,PDM
 SG_ ModOnLiTintgCmd : 35|4@0+ (1,0) [0|15] ""  DDM,PDM
 SG_ ModOnLiTintgCmd_UB : 31|1@0+ (1,0) [0|1] ""  DDM,PDM

BO_ 384 CEMBodyFr15: 8 CEM
 SG_ ActvnOfTrlrLiRvsg : 56|1@0+ (1,0) [0|1] ""  TRM
 SG_ ActvnOfTrlrLiRvsg_UB : 57|1@0+ (1,0) [0|1] ""  TRM
 SG_ ClimaEcoModRqrd : 38|1@0+ (1,0) [0|1] ""  CCM
 SG_ ClimaEcoModRqrd_UB : 39|1@0+ (1,0) [0|1] ""  CCM
 SG_ HeatrDurgDrvgReqd : 37|2@0+ (1,0) [0|3] ""  CCM
 SG_ HeatrDurgDrvgReqd_UB : 35|1@0+ (1,0) [0|1] ""  CCM
 SG_ HmiCmptmtCoolgReq : 51|1@0+ (1,0) [0|1] ""  CCM
 SG_ HmiCmptmtCoolgReq_UB : 52|1@0+ (1,0) [0|1] ""  CCM
 SG_ HmiCmptmtTSp_UB : 7|1@0+ (1,0) [0|1] ""  CCM
 SG_ HmiCmptmtTSpForRowFirstLe : 4|5@0+ (0.5,15) [15|30.5] "Deg"  CCM
 SG_ HmiCmptmtTSpForRowFirstRi : 12|5@0+ (0.5,15) [15|30.5] "Deg"  CCM
 SG_ HmiCmptmtTSpForRowSecLe : 20|5@0+ (0.5,15) [15|30.5] "Deg"  CCM
 SG_ HmiCmptmtTSpForRowSecRi : 28|5@0+ (0.5,15) [15|30.5] "Deg"  CCM
 SG_ HmiCmptmtTSpSpclForRowFirstLe : 6|2@0+ (1,0) [0|3] ""  CCM
 SG_ HmiCmptmtTSpSpclForRowFirstRi : 14|2@0+ (1,0) [0|3] ""  CCM
 SG_ HmiCmptmtTSpSpclForRowSecLe : 22|2@0+ (1,0) [0|3] ""  CCM
 SG_ HmiCmptmtTSpSpclForRowSecRi : 30|2@0+ (1,0) [0|3] ""  CCM
 SG_ HvacCooltFlowAct : 33|10@0+ (0.05,0) [0|51.15] "L / min"  CCM
 SG_ HvacCooltFlowAct_UB : 34|1@0+ (1,0) [0|1] ""  CCM
 SG_ SeatSwtLeSigThrd : 49|2@0+ (1,0) [0|3] ""  PSMD
 SG_ SeatSwtLeSigThrd_UB : 50|1@0+ (1,0) [0|1] ""  PSMD
 SG_ SeatSwtRiSigThrd : 54|2@0+ (1,0) [0|3] ""  PSMD
 SG_ SeatSwtRiSigThrd_UB : 55|1@0+ (1,0) [0|1] ""  PSMD

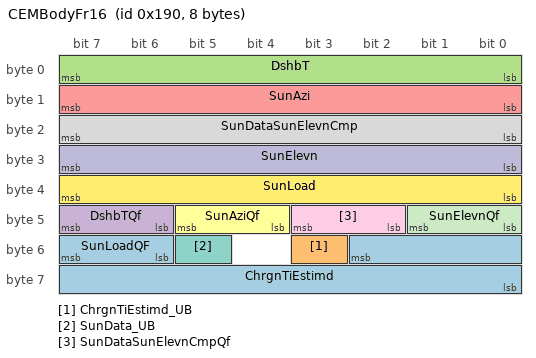
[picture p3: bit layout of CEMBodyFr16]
BO_ 400 CEMBodyFr16: 8 CEM
 SG_ ChrgnTiEstimd : 50|11@0+ (1,0) [0|2047] "Mins"  VCM
 SG_ ChrgnTiEstimd_UB : 51|1@0+ (1,0) [0|1] ""  VCM
 SG_ DshbT : 7|8@0+ (1,-40) [-40|125] "Deg"  CCM
 SG_ DshbTQf : 47|2@0+ (1,0) [0|3] ""  CCM
 SG_ SunAzi : 15|8@0+ (1.5,0) [0|358.5] "Deg"  CCM
 SG_ SunAziQf : 45|2@0+ (1,0) [0|3] ""  CCM
 SG_ SunData_UB : 53|1@0+ (1,0) [0|1] ""  CCM
 SG_ SunDataSunElevnCmp : 23|8@0+ (0.375,0) [0|90] "Deg"  CCM
 SG_ SunDataSunElevnCmpQf : 43|2@0+ (1,0) [0|3] ""  CCM
 SG_ SunElevn : 31|8@0+ (0.375,0) [0|90] "Deg"  CCM
 SG_ SunElevnQf : 41|2@0+ (1,0) [0|3] ""  CCM
 SG_ SunLoad : 39|8@0+ (3,0) [0|720] "W/m2"  CCM
 SG_ SunLoadQF : 55|2@0+ (1,0) [0|3] ""  CCM

BO_ 432 CEMBodyFr17: 8 CEM
 SG_ CnclHldChrgReq : 38|1@0+ (1,0) [0|1] ""  VCM
 SG_ CnclHldChrgReq_UB : 39|1@0+ (1,0) [0|1] ""  VCM
 SG_ CoolgLimd : 63|1@0+ (1,0) [0|1] ""  CCM
 SG_ CoolgLoad : 62|7@0+ (1,0) [0|100] "%"  CCM
 SG_ CoolgLoadGroup_UB : 55|1@0+ (1,0) [0|1] ""  CCM
 SG_ DiagcHvacCooltVlvErr : 47|1@0+ (1,0) [0|1] ""  CCM
 SG_ DiagcHvacCooltVlvErr_UB : 54|1@0+ (1,0) [0|1] ""  CCM
 SG_ EngCooltLoFlowReq : 45|6@0+ (0.5,0) [0|20] "L / min"  CCM
 SG_ EngCooltLoFlowReq_UB : 46|1@0+ (1,0) [0|1] ""  CCM
 SG_ ErsStrtRes : 36|5@0+ (1,0) [0|31] ""  VCM
 SG_ ErsStrtRes_UB : 37|1@0+ (1,0) [0|1] ""  VCM
 SG_ EvaprVlvReqRe : 48|1@0+ (1,0) [0|1] ""  CCM
 SG_ EvaprVlvReqRe_UB : 49|1@0+ (1,0) [0|1] ""  CCM
 SG_ FuTankPOkForFuHeatr : 25|1@0+ (1,0) [0|1] ""  CCM
 SG_ FuTankPOkForFuHeatr_UB : 24|1@0+ (1,0) [0|1] ""  CCM
 SG_ MirrDefrstAtDrvrCmd : 50|1@0+ (1,0) [0|1] ""  DDM
 SG_ MirrDefrstAtDrvrCmd_UB : 51|1@0+ (1,0) [0|1] ""  DDM
 SG_ MirrDefrstAtPassCmd : 52|1@0+ (1,0) [0|1] ""  PDM
 SG_ MirrDefrstAtPassCmd_UB : 53|1@0+ (1,0) [0|1] ""  PDM
 SG_ VehSpdLgtSafe : 6|15@0+ (0.00391,0) [0|125.0027] "m/s"  CCM,DDM,PDM,PSMD
 SG_ VehSpdLgtSafeChks : 23|8@0+ (1,0) [0|255] ""  CCM,DDM,PDM,PSMD
 SG_ VehSpdLgtSafeCntr : 31|4@0+ (1,0) [0|15] ""  CCM,DDM,PDM,PSMD
 SG_ VehSpdLgtSafeGroup_UB : 7|1@0+ (1,0) [0|1] ""  CCM,DDM,PDM,PSMD
 SG_ VehSpdLgtSafeQf : 27|2@0+ (1,0) [0|3] ""  CCM,DDM,PDM,PSMD

BO_ 496 CEMBodyFr18: 8 CEM
 SG_ CmptmtCoolgSts : 27|4@0+ (1,0) [0|15] ""  CCM
 SG_ CmptmtCoolgSts_UB : 22|1@0+ (1,0) [0|1] ""  CCM
 SG_ EngOilLvlSts : 18|3@0+ (1,0) [0|7] ""  VCM
 SG_ EngOilLvlSts_UB : 19|1@0+ (1,0) [0|1] ""  VCM
 SG_ HmiSeatClima_UB : 20|1@0+ (1,0) [0|1] ""  CCM
 SG_ HmiSeatHeatgForRowFirstLe : 51|2@0+ (1,0) [0|3] ""  CCM
 SG_ HmiSeatHeatgForRowFirstRi : 49|2@0+ (1,0) [0|3] ""  CCM
 SG_ HmiSeatHeatgForRowSecLe : 63|2@0+ (1,0) [0|3] ""  CCM
 SG_ HmiSeatHeatgForRowSecRi : 61|2@0+ (1,0) [0|3] ""  CCM
 SG_ HmiSeatVentnForRowFirstLe : 59|2@0+ (1,0) [0|3] ""  CCM
 SG_ HmiSeatVentnForRowFirstRi : 57|2@0+ (1,0) [0|3] ""  CCM
 SG_ HvClimaCmd : 53|2@0+ (1,0) [0|3] ""  CCM
 SG_ HvClimaCmd_UB : 54|1@0+ (1,0) [0|1] ""  CCM
 SG_ HvHeatgPwrAllwd : 33|10@0+ (20,0) [0|20460] "W"  CCM
 SG_ HvHeatgPwrAllwd_UB : 21|1@0+ (1,0) [0|1] ""  CCM
 SG_ SunCurtPosnSts : 38|5@0+ (1,0) [0|31] ""  CCM
 SG_ SunCurtPosnSts_UB : 39|1@0+ (1,0) [0|1] ""  CCM

CM_ SG_ 80 ClimaTiOfEnd "Informs of when the last pre-conditioning was ended.";
CM_ SG_ 80 ClimaTiOfEnd_UB "Update bit for signal ClimaTiOfEnd";
CM_ SG_ 80 ClimaWarn "Informs if anything has gone wrong with the parking climatisation.";
CM_ SG_ 80 ClimaWarn_UB "Update bit for signal ClimaWarn";
CM_ SG_ 80 HvacCoolgEnaFrnt "Request cooling for front HVAC. ";
CM_ SG_ 80 HvacCoolgEnaFrnt_UB "Update bit for signal HvacCoolgEnaFrnt";
CM_ SG_ 80 HvacEvaprTFrnt "Air temperature measured in HVAC after evaporator Evaporator temperature";
CM_ SG_ 80 HvacEvaprTFrntGroup_UB "Update bit for signal group HvacEvaprTFrntGroup; HvacEvaprTFrnt HvacEvaprTFrntQf ";
CM_ SG_ 80 HvacEvaprTFrntQf "Air temperature measured in HVAC after evaporator Quality factor evaporator temperature";
CM_ SG_ 80 HvacRecircAct "Amount of recirculated air in front HVAC. ";
CM_ SG_ 80 HvacRecircAct_UB "Update bit for signal HvacRecircAct";
CM_ SG_ 96 ClimaActv "Informs if a parking climatisation is active (either pre- or post conditioning).";
CM_ SG_ 96 ClimaActv_UB "Update bit for signal ClimaActv";
CM_ SG_ 96 CmptmtAirTEstimdAtRowFirstLoResl "Estimated compartment temperature at head level, first row";
CM_ SG_ 96 CmptmtAirTEstimdAtRowFirstL_0000 "Update bit for signal CmptmtAirTEstimdAtRowFirstLoResl";
CM_ SG_ 96 EngSpdIncIdleForClima "Request to increase idle speed. Used when current engine speed is insufficient for climate comfort";
CM_ SG_ 96 EngSpdIncIdleForClima_UB "Update bit for signal EngSpdIncIdleForClima";
CM_ SG_ 96 HeatrIntkCooltTEstimd "Coolant temperature in heater intake.";
CM_ SG_ 96 HeatrIntkCooltTEstimd_UB "Update bit for signal HeatrIntkCooltTEstimd";
CM_ SG_ 96 HvacAirMFlowEstimd "Estimated total mass air flow in front HVAC. ";
CM_ SG_ 96 HvacAirMFlowEstimd_UB "Update bit for signal HvacAirMFlowEstimd";
CM_ SG_ 96 HvEgyDesForClima "Desired energy from high voltage system to use for climatisation";
CM_ SG_ 96 HvEgyDesForClima_UB "Update bit for signal HvEgyDesForClima";
CM_ SG_ 96 TInCooltAtStrtOfClima "Temperature measured by the heater in the coolant at the start of the latest pre-conditioning.";
CM_ SG_ 96 TInCooltAtStrtOfClima_UB "Update bit for signal TInCooltAtStrtOfClima";
CM_ SG_ 336 AmbTEstimd_UB "Update bit for signal group AmbTEstimd; AmbTEstimdAmbTEstimd AmbTEstimdAmbTEstimdQf ";
CM_ SG_ 336 AmbTEstimdAmbTEstimd "Estimated/filtered/modelled amibient temperature based on information from ambient temp sensor and all other available temperature sensors and vehicle information.  Estimated ambient temperature";
CM_ SG_ 336 AmbTEstimdAmbTEstimdQf "Estimated/filtered/modelled amibient temperature based on information from ambient temp sensor and all other available temperature sensors and vehicle information.  Quality factor for estimated signal";
CM_ SG_ 336 ClimaSts "Climatisation status";
CM_ SG_ 336 ClimaSts_UB "Update bit for signal ClimaSts";
CM_ SG_ 336 DefrstReq_UB "Update bit for signal group DefrstReq; MirrDefrstReq WinDefrstFrntReq WinDefrstReReq ";
CM_ SG_ 336 FuHeatrFuCns1 "Informs of how much fuel the heater has consumed since entering Usage mod driving. Signal is modulus.";
CM_ SG_ 336 FuHeatrFuCns1_UB "Update bit for signal FuHeatrFuCns1";
CM_ SG_ 336 HvHeatgPwrCritDes "Critical high voltage power need for heating subsystem.";
CM_ SG_ 336 HvHeatgPwrCritDes_UB "Update bit for signal HvHeatgPwrCritDes";
CM_ SG_ 336 MirrDefrstReq "Request to activate electric defrosters.  Mirror defroster request";
CM_ SG_ 336 PwrEstimdAtStbForClima "Estimated power reduction in standby";
CM_ SG_ 336 PwrEstimdAtStbForClima_UB "Update bit for signal PwrEstimdAtStbForClima";
CM_ SG_ 336 WinDefrstFrntReq "Request to activate electric defrosters.  Windscreen defroster request";
CM_ SG_ 336 WinDefrstReReq "Request to activate electric defrosters.  Rear window defroster request";
CM_ SG_ 336 WindIceDetdFrnt "Ice on the front windscreen is detected according to algorithm in CCM.";
CM_ SG_ 336 WindIceDetdFrnt_UB "Update bit for signal WindIceDetdFrnt";
CM_ SG_ 336 WindIceDetdRe "Ice on the rear window and/or exterior rear view mirrors is detected according to algorithm in CCM.";
CM_ SG_ 336 WindIceDetdRe_UB "Update bit for signal WindIceDetdRe";
CM_ SG_ 368 CooltFlowFromWtrPmpAux "Informs of how much flow that is provided by the auxiliary water pump to the engine coolant circuit.";
CM_ SG_ 368 CooltFlowFromWtrPmpAux_UB "Update bit for signal CooltFlowFromWtrPmpAux";
CM_ SG_ 368 HeatrCooltT "The coolant temperature measured in the coolant heater.";
CM_ SG_ 368 HeatrCooltT_UB "Update bit for signal HeatrCooltT";
CM_ SG_ 368 HvacEvaprTSpFrnt "Set value for air temperature after evaporator in front HVAC";
CM_ SG_ 368 HvacEvaprTSpFrnt_UB "Update bit for signal HvacEvaprTSpFrnt";
CM_ SG_ 368 HvHeatgPwrCns "High voltage power consumption for the heating subsystem.";
CM_ SG_ 368 HvHeatgPwrCns_UB "Update bit for signal HvHeatgPwrCns";
CM_ SG_ 368 HvHeatgPwrNormDes "Actual power desire from heating subsystem.";
CM_ SG_ 368 HvHeatgPwrNormDes_UB "Update bit for signal HvHeatgPwrNormDes";
CM_ SG_ 368 RlyCmftForClimaReq "Request to close comfort relay, used by ClimateControl to ensure all wanted sensors and actuators are power supplied.";
CM_ SG_ 368 RlyCmftForClimaReq_UB "Update bit for signal RlyCmftForClimaReq";
CM_ SG_ 368 UBoostReqByClima "Request of extra voltage to boost HVAC fan speed level";
CM_ SG_ 368 UBoostReqByClima_UB "Update bit for signal UBoostReqByClima";
CM_ SG_ 368 WindDewTUppr_UB "Update bit for signal group WindDewTUppr; WindDewTUpprDewT WindDewTUpprDewTQf ";
CM_ SG_ 368 WindDewTUpprDewT "Dew point temperature at upper windscreen. Dew point at windscreen";
CM_ SG_ 368 WindDewTUpprDewTQf "Dew point temperature at upper windscreen. Quality factor";
CM_ SG_ 448 EngHeatgReq "Heat request from engine to Heating Manager. When signal is ON, heat must be provided. ";
CM_ SG_ 448 EngHeatgReq_UB "Update bit for signal EngHeatgReq";
CM_ SG_ 448 EvaprVlvReSts "Status of shut off valve for AC in rear HVAC.";
CM_ SG_ 448 EvaprVlvReSts_UB "Update bit for signal EvaprVlvReSts";
CM_ SG_ 448 EvaprVlvReStsExtd_UB "Update bit for signal group EvaprVlvReStsExtd; EvaprVlvReStsExtdDiagcStsForCircOpen EvaprVlvReStsExtdDiagcStsForShoToBatt EvaprVlvReStsExtdDiagcStsForShoToGnd ";
CM_ SG_ 448 EvaprVlvReStsExtdDiagcStsForCirc "Status for rear evaporator valve diagnostics Status for open circuit diagnostics";
CM_ SG_ 448 EvaprVlvReStsExtdDiagcStsForShoT "Status for rear evaporator valve diagnostics Status for short to battery diagnostics";
CM_ SG_ 448 EvaprVlvReStsExtdDiagcStsFo_0000 "Status for rear evaporator valve diagnostics Status for for short to ground diagnostics";
CM_ SG_ 448 FuTankPRelsForFuHeatrReq "Before use of FOH in hybrid cars, signaling to reduce/check tank pressure.";
CM_ SG_ 448 FuTankPRelsForFuHeatrReq_UB "Update bit for signal FuTankPRelsForFuHeatrReq";
CM_ SG_ 448 HvacAirMFlowReEstimd_UB "Update bit for signal HvacAirMFlowReEstimd";
CM_ SG_ 448 HvacCooltFlowReq "Coolant flow request to the engine coolant flow system.";
CM_ SG_ 448 HvacCooltFlowReq_UB "Update bit for signal HvacCooltFlowReq";
CM_ SG_ 448 HvacCooltVlvReqExt "Request for valve position from CCM";
CM_ SG_ 448 HvacCooltVlvReqExt_UB "Update bit for signal HvacCooltVlvReqExt";
CM_ SG_ 448 HvacCooltVlvSts "Contains coolant valve status.";
CM_ SG_ 448 HvacCooltVlvSts_UB "Update bit for signal HvacCooltVlvSts";
CM_ SG_ 448 HvacHeatrPwrCns "Contains an estimation of amount of heat energy that is taken from coolant by heat exchanger.";
CM_ SG_ 448 HvacHeatrPwrCns_UB "Update bit for signal HvacHeatrPwrCns";
CM_ SG_ 448 WindTGroup_UB "Update bit for signal group WindTGroup; WindTWindT WindTWindTQf ";
CM_ SG_ 448 WindTWindT "Windscreen temperature Windscreen temperature";
CM_ SG_ 448 WindTWindTQf "Windscreen temperature Quality factor";
CM_ SG_ 272 ClimaPwrCns "Actual current consumption of electric climate loads";
CM_ SG_ 272 ClimaPwrCns_UB "Update bit for signal ClimaPwrCns";
CM_ SG_ 272 ClimaPwrCritDes "Critical power level needed for electric climate loads";
CM_ SG_ 272 ClimaPwrCritDes_UB "Update bit for signal ClimaPwrCritDes";
CM_ SG_ 272 ClimaPwrNormDes "Desired power wanted for electric climate loads";
CM_ SG_ 272 ClimaPwrNormDes_UB "Update bit for signal ClimaPwrNormDes";
CM_ SG_ 272 EngRunngReqByClima "Request from climate control to start engine or inhibit stop. Used maintain a desirable comfort level in compartment.";
CM_ SG_ 272 EngRunngReqByClima_UB "Update bit for signal EngRunngReqByClima";
CM_ SG_ 272 HvacCoolgEnaRe "Request cooling for rear HVAC";
CM_ SG_ 272 HvacCoolgEnaRe_UB "Update bit for signal HvacCoolgEnaRe";
CM_ SG_ 272 LvlOfClimaCmft "Current Clean Zone level sent to HMI.";
CM_ SG_ 272 LvlOfClimaCmft_UB "Update bit for signal LvlOfClimaCmft";
CM_ SG_ 272 PwrChrgDetdForPrkgHeatrElec "Sending power connection status to DIM and IHU.
True==Connected
False==Not Connected";
CM_ SG_ 272 PwrChrgDetdForPrkgHeatrElec_UB "Update bit for signal PwrChrgDetdForPrkgHeatrElec";
CM_ SG_ 272 SeatHeatgAutCdn "Signal sent to HMI when conditions for Auto seat heating is true. When signal is true seat heating will be set to auto level from HMI (user selection). Signal will be true until conditions is no longer met, and seat heating will then be deactivated by HMI. Signal is used for auto of both driver and paseenger front seat heating and also for steering wheel heating. ";
CM_ SG_ 272 SeatHeatgAutCdn_UB "Update bit for signal SeatHeatgAutCdn";
CM_ SG_ 272 SteerWhlHeatgAllwd "The amount of power the heated steering wheel function may consume in a given moment";
CM_ SG_ 272 SteerWhlHeatgAllwd_UB "Update bit for signal SteerWhlHeatgAllwd";
CM_ SG_ 576 ClimaStrtTi "Wake up time requested from climate control for pre-climatisation.";
CM_ SG_ 576 ClimaStrtTi_UB "Update bit for signal ClimaStrtTi";
CM_ SG_ 576 ClimaTmrSts "Informs if any timers are set for pre conditioning.";
CM_ SG_ 576 ClimaTmrSts_UB "Update bit for signal ClimaTmrSts";
CM_ SG_ 576 CoolgStsForDisp "Status of 'forced cooling' of infotainment components";
CM_ SG_ 576 CoolgStsForDisp_UB "Update bit for signal CoolgStsForDisp";
CM_ SG_ 576 CustClimaOvrdNotifForHmiCpt "Notifies driver when 'forced cooling' overrides user settings in a way that is noticable for the customer. ";
CM_ SG_ 576 CustClimaOvrdNotifForHmiCpt_UB "Update bit for signal CustClimaOvrdNotifForHmiCpt";
CM_ SG_ 576 EgyDesForClima "Desired energy to use for climatisation";
CM_ SG_ 576 EgyDesForClima_UB "Update bit for signal EgyDesForClima";
CM_ SG_ 576 FuHeatrActv "Informs if the fuel operated heater is active, this signal is used for ISO symbol in DIM.";
CM_ SG_ 576 FuHeatrActv_UB "Update bit for signal FuHeatrActv";
CM_ SG_ 576 FuHeatrFuCnsDurgCyc1 "Informs how much that have been used by the fuel operated heater when not in usage mode driving. Will reset to 0 when leaving usage mode driving.";
CM_ SG_ 576 FuHeatrFuCnsDurgCyc1_UB "Update bit for signal FuHeatrFuCnsDurgCyc1";
CM_ SG_ 576 PostDrvgClimaAvl "Informs if post climatisation is available.";
CM_ SG_ 576 PostDrvgClimaAvl_UB "Update bit for signal PostDrvgClimaAvl";
CM_ SG_ 576 RlyCrashForClimaReq "Request to activate crash relay in order to have power supply for coolant heater.";
CM_ SG_ 576 RlyCrashForClimaReq_UB "Update bit for signal RlyCrashForClimaReq";
CM_ SG_ 576 SteerWhlHeatgDurgClima "Requests steering wheel heat during pre climatisation.";
CM_ SG_ 576 SteerWhlHeatgDurgClima_UB "Update bit for signal SteerWhlHeatgDurgClima";
CM_ SG_ 597 ClimaActvAlrmSts "Siignal to inform IMS (Interior Motion Sensor) that some kind of climatisation/heating/cooling/fan running activity is ongoing. ";
CM_ SG_ 597 ClimaActvAlrmSts_UB "Update bit for signal ClimaActvAlrmSts";
CM_ SG_ 597 ClngActv_UB "Update bit for signal ClngActv";
CM_ SG_ 597 CmptmtAirTEstimdExtd_UB "Update bit for signal group CmptmtAirTEstimdExtd; CmptmtAirTEstimdExtdComptmtT CmptmtAirTEstimdExtdQlyFlg ";
CM_ SG_ 597 CmptmtAirTEstimdExtdComptmtT "Estimated compartment temperature with quality flag Estimated compartment Temperature";
CM_ SG_ 597 CmptmtAirTEstimdExtdQlyFlg "Estimated compartment temperature with quality flag Quality flag ";
CM_ SG_ 597 CooltVlvOutpTyp "Define coolant valve type";
CM_ SG_ 597 CooltVlvOutpTyp_UB "Update bit for signal CooltVlvOutpTyp";
CM_ SG_ 597 HeatgForHvBattSts_UB "Update bit for signal HeatgForHvBattSts";
CM_ SG_ 597 PreClngNotif_UB "Update bit for signal PreClngNotif";
CM_ SG_ 1282 NM_AW_CCM "Active Wakeup Bit, 0: Node has not woken up the network (passive wakeup), 1: Node has woken up the network (active Wakeup)";
CM_ SG_ 1282 NM_CS_CCM "NM Coordinator Sleep Bit, 0: Start of synchronized shutdown is not requested by main coordinator, 1: Start of synchronized shutdown is requested by main coordinator";
CM_ SG_ 1282 NM_RMR_CCM "Repeat Message Request Bit, 0: Repeat Message State not requested, 1: Repeat Message State requested";
CM_ SG_ 1282 NM_PNI_CCM "Partial Network Information Bit, 0: NM message contains no Partial Network request information, 1: NM message contains Partial Network request information";
CM_ SG_ 1282 NM_NodeID_CCM "Source Node Identifier";
CM_ SG_ 800 VFCVectorCCM_UB "Update bit for signal group VFCVectorCCM; VFCVectorCCMGrp1 VFCVectorCCMGrp2 VFCVectorCCMGrp3 ";
CM_ SG_ 800 VFCVectorCCMGrp1 " VFC bit vector, VFC {0..15}";
CM_ SG_ 800 VFCVectorCCMGrp2 " VFC bit vector, VFC{16..31}";
CM_ SG_ 800 VFCVectorCCMGrp3 " VFC bit vector, VFC {32..47}";
CM_ SG_ 1122 HmiCmptmtAirDistbnFrntM1 "M1 development only signal.

By user requested air distribution for first and second row";
CM_ SG_ 1122 HmiCmptmtCoolgReqM1 "M1 development only signal.

User request to use AC auto or off";
CM_ SG_ 1122 HmiCmptmtTSpForRowFirstLeM1 "M1 development only signal.

Temp settings for climate zones First row, left side,  climate set point settings from HMI";
CM_ SG_ 1122 HmiCmptmtTSpForRowFirstRiM1 "M1 development only signal.

Temp settings for climate zones First row, right side, climate setpoint temperature from HMI";
CM_ SG_ 1122 HmiCmptmtTSpForRowSecLeM1 "M1 development only signal.

Temp settings for climate zones Second row, left side, climate setpoint temperature from HMI";
CM_ SG_ 1122 HmiCmptmtTSpForRowSecRiM1 "M1 development only signal.

Temp settings for climate zones Second row, right side, climate setpoint temperature from HMI";
CM_ SG_ 1122 HmiCmptmtTSpSpclForRowFirstLeM1 "M1 development only signal.

Temp settings for climate zones HI/LO setting first row left";
CM_ SG_ 1122 HmiCmptmtTSpSpclForRowFirstRiM1 "M1 development only signal.

Temp settings for climate zones HI/LO first row right";
CM_ SG_ 1122 HmiCmptmtTSpSpclForRowSecLeM1 "M1 development only signal.

Temp settings for climate zones HI/LO second row left side";
CM_ SG_ 1122 HmiCmptmtTSpSpclForRowSecRiM1 "M1 development only signal.

Temp settings for climate zones HI/LO second row, right side ";
CM_ SG_ 1122 HmiDefrstMaxReqM1 "M1 development only signal.

Maxdefroster requested by user";
CM_ SG_ 1122 HmiHvacFanLvlFrntM1 "M1 development only signal.

Fan level for first row climate";
CM_ SG_ 1122 HmiHvacRecircCmdM1 "M1 development only signal.

Manual recirculation requested";
CM_ SG_ 1449 EndOfLineSigOverByte0 " Byte0";
CM_ SG_ 1449 EndOfLineSigOverByte1 " Byte1";
CM_ SG_ 1449 EndOfLineSigOverByte2 " Byte2";
CM_ SG_ 1449 EndOfLineSigOverByte3 " Byte3";
CM_ SG_ 1449 EndOfLineSigOverByte4 " Byte4";
CM_ SG_ 1449 EndOfLineSigOverByte5 " Byte5";
CM_ SG_ 1449 EndOfLineSigOverByte6 " Byte6";
CM_ SG_ 1449 EndOfLineSigOverByte7 " Byte7";
CM_ SG_ 32 ActvnOfHndlDoorLi_UB "Update bit for signal group ActvnOfHndlDoorLi; HndlDoorLiDrvr HndlDoorLiDrvrRe HndlDoorLiPass HndlDoorLiPassRe ";
CM_ SG_ 32 ActvnOfTrlrBrkLi_UB "Update bit for signal ActvnOfTrlrBrkLi";
CM_ SG_ 32 DoorDrvrIntrSwtLedLockgReCmd "DoorDrvrIntrSwtLedLockgReCmd - Rear Driver Side Door Interior Lockg Switch LED command.

This is the command signal for the locking LED located in the driver side rear door interior locking switch. 

On - LED shall be on
Off - LED shall be off";
CM_ SG_ 32 DoorDrvrIntrSwtLedLockgReCmd_UB "Update bit for signal DoorDrvrIntrSwtLedLockgReCmd";
CM_ SG_ 32 DoorDrvrLockCmd "DoorDrvrLockCmd - Driver Door Lock Command

Locking Command signal to driver door:

LockActvnOff - Idle Command
LockActvnUnlck - Unlock door
LockActvnLock - Lock door
LockActvnSafe - Double lock door
LockActvnUnlckByCrash - Crash Unlock door
";
CM_ SG_ 32 DoorDrvrLockCmd_UB "Update bit for signal DoorDrvrLockCmd";
CM_ SG_ 32 DoorDrvrLockReCmd "DoorDrvrLockReCmd - Driver Side Rear Door Lock Command

Locking Command signal to driver side rear door:

LockActvnOff - Idle Command
LockActvnUnlck - Unlock door
LockActvnLock - Lock door
LockActvnSafe - Double lock door
LockActvnUnlckByCrash - Crash Unlock door
";
CM_ SG_ 32 DoorDrvrLockReCmd_UB "Update bit for signal DoorDrvrLockReCmd";
CM_ SG_ 32 DoorPassIntrSwtLedLockgReCmd "DoorPassIntrSwtLedLockgReCmd - Passenger Side Rear Door Interior Lockg Switch LED command.

This is the command signal for the locking LED located in the passenger side rear door interior locking switch. 

On - LED shall be on
Off - LED shall be off";
CM_ SG_ 32 DoorPassIntrSwtLedLockgReCmd_UB "Update bit for signal DoorPassIntrSwtLedLockgReCmd";
CM_ SG_ 32 DoorPassLockCmd "DoorPassLockCmd - Passenger Door Lock Command

Locking Command signal to passenger door:

LockActvnOff - Idle Command
LockActvnUnlck - Unlock door
LockActvnLock - Lock door
LockActvnSafe - Double lock door
LockActvnUnlckByCrash - Crash Unlock door
";
CM_ SG_ 32 DoorPassLockCmd_UB "Update bit for signal DoorPassLockCmd";
CM_ SG_ 32 DoorPassLockReCmd "DoorPassLockReCmd - Passenger Side Rear Door Lock Command

Locking Command signal to passenger side rear door:

LockActvnOff - Idle Command
LockActvnUnlck - Unlock door
LockActvnLock - Lock door
LockActvnSafe - Double lock door
LockActvnUnlckByCrash - Crash Unlock door
";
CM_ SG_ 32 DoorPassLockReCmd_UB "Update bit for signal DoorPassLockReCmd";
CM_ SG_ 32 EveMemPosn "Handles memory buttons on driver side and profile position (4th memory) for ergonomic settings connected to personal settings
When to load, automove or store ergonomic settings
It also contains information if easy ingress/ergress is active What ergonomic event to perform";
CM_ SG_ 32 HndlDoorLiDrvr "Controls all door handles exterior lighting on and off. Driver door handle light";
CM_ SG_ 32 HndlDoorLiDrvrRe "Controls all door handles exterior lighting on and off. Rear driver door handle light";
CM_ SG_ 32 HndlDoorLiPass "Controls all door handles exterior lighting on and off. Passenger door handle light";
CM_ SG_ 32 HndlDoorLiPassRe "Controls all door handles exterior lighting on and off. Rear passenger door handle light";
CM_ SG_ 32 HvCooltHeatrEnad "Enable signal for HVCH.";
CM_ SG_ 32 HvCooltHeatrEnad_UB "Update bit for signal HvCooltHeatrEnad";
CM_ SG_ 32 IndcrTurnCmd1WdCmd_UB "Update bit for signal group IndcrTurnCmd1WdCmd; IndcrTurnCmd1WdHzrdTelltl IndcrTurnCmd1WdIndcrTrig ";
CM_ SG_ 32 IndcrTurnCmd1WdHzrdTelltl "Controls the front/rear and side repeaters on and off to create left/right direction indication or Hazard Warning Light.

Signal will be event driven and holds every flank on and off of the lamps. HWL button telltale on/off";
CM_ SG_ 32 IndcrTurnCmd1WdIndcrTrig "Controls the front/rear and side repeaters on and off to create left/right direction indication or Hazard Warning Light.

Signal will be event driven and holds every flank on and off of the lamps. The trigger for the blink functionality (stop, left, right, both)";
CM_ SG_ 32 IndcrTurnSts1WdSts "Provides the state and not the event of HWL/Direction Indicator.";
CM_ SG_ 32 IndcrTurnSts1WdSts_UB "Update bit for signal IndcrTurnSts1WdSts";
CM_ SG_ 32 IntrLiActvn1 "Signalgroup that contains the signals IntrLiActvn, IntrLiRoofDim and IntrLiDmdOff. Which tells the interior lighting when and how to dim (speed) and when to force the illumination to go off. On/off for the roof and door lights";
CM_ SG_ 32 IntrLiCmdGroup_UB "Update bit for signal group IntrLiCmdGroup; IntrLiActvn1 IntrLiRoofDim IntrLiRoofDmdOff ";
CM_ SG_ 32 IntrLiDmdOff "The CEM sends this signal to eliminate illumination is situations where the lights shall be forced off no matter what other conditions are signals says.";
CM_ SG_ 32 IntrLiDmdOff_UB "Update bit for signal IntrLiDmdOff";
CM_ SG_ 32 IntrLiRoofDim "Signalgroup that contains the signals IntrLiActvn, IntrLiRoofDim and IntrLiDmdOff. Which tells the interior lighting when and how to dim (speed) and when to force the illumination to go off. Dim value slow/fast from OHC";
CM_ SG_ 32 IntrLiRoofDmdOff "Signalgroup that contains the signals IntrLiActvn, IntrLiRoofDim and IntrLiDmdOff. Which tells the interior lighting when and how to dim (speed) and when to force the illumination to go off. Force off for the lights from OHC";
CM_ SG_ 32 LoadAndStoreReq_UB "Update bit for signal group LoadAndStoreReq; EveMemPosn LoadAndStoreReqIdPen LoadAndStoreReqInOutEasy MemPosn ";
CM_ SG_ 32 LoadAndStoreReqIdPen "Handles memory buttons on driver side and profile position (4th memory) for ergonomic settings connected to personal settings
When to load, automove or store ergonomic settings
It also contains information if easy ingress/ergress is active Profile ID";
CM_ SG_ 32 LoadAndStoreReqInOutEasy "Handles memory buttons on driver side and profile position (4th memory) for ergonomic settings connected to personal settings
When to load, automove or store ergonomic settings
It also contains information if easy ingress/ergress is active Easy ingress/egress activated";
CM_ SG_ 32 MemPosn "Handles memory buttons on driver side and profile position (4th memory) for ergonomic settings connected to personal settings
When to load, automove or store ergonomic settings
It also contains information if easy ingress/ergress is active Memory position for profile or physical memory buttons";
CM_ SG_ 64 ClimaRqrd "Pre-Climatisation request from HMI.";
CM_ SG_ 64 ClimaRqrd_UB "Update bit for signal ClimaRqrd";
CM_ SG_ 64 CllsnWarnIndcnLe "Request for BLIS indication left from active safety.";
CM_ SG_ 64 CllsnWarnIndcnLe_UB "Update bit for signal CllsnWarnIndcnLe";
CM_ SG_ 64 CllsnWarnIndcnRi "Request for BLIS indication right from active safety.";
CM_ SG_ 64 CllsnWarnIndcnRi_UB "Update bit for signal CllsnWarnIndcnRi";
CM_ SG_ 64 DoorDrvrIntrSwtLedLockgCmd "DoorDrvrIntrSwtLedLockgCmd - Driver Door Interior Lockg Switch LED command.

This is the command signal for the locking LED located in the driver door interior central locking switch. 

On - LED shall be on
Off - LED shall be off";
CM_ SG_ 64 DoorDrvrIntrSwtLedLockgCmd_UB "Update bit for signal DoorDrvrIntrSwtLedLockgCmd";
CM_ SG_ 64 DoorDrvrReSts "DoorDrvrReSts - Driver Side Rear Door Status

Ukwn - Unknown status
Opend - Opened
Clsd - Closed";
CM_ SG_ 64 DoorDrvrReSts_UB "Update bit for signal DoorDrvrReSts";
CM_ SG_ 64 DoorDrvrSts "DoorDrvrSts - Driver Door Status

Ukwn - Unknown status
Opend - Opened
Clsd - Closed";
CM_ SG_ 64 DoorDrvrSts_UB "Update bit for signal DoorDrvrSts";
CM_ SG_ 64 DoorPassIntrSwtLedLockgCmd "DoorPassIntrSwtLedLockgCmd - Passenger Door Interior Lockg Switch LED command.

This is the command signal for the locking LED located in the passenger door interior central locking switch. 

On - LED shall be on
Off - LED shall be off";
CM_ SG_ 64 DoorPassIntrSwtLedLockgCmd_UB "Update bit for signal DoorPassIntrSwtLedLockgCmd";
CM_ SG_ 64 GlbWinCmd "Global open/close command that tells when to perform a global open or close.";
CM_ SG_ 64 GlbWinCmd_UB "Update bit for signal GlbWinCmd";
CM_ SG_ 64 LcmaIndcnLe "Indicates if a left LCMA warning shall be shown to the driver or not.";
CM_ SG_ 64 LcmaIndcnLe_UB "Update bit for signal LcmaIndcnLe";
CM_ SG_ 64 LcmaIndcnRi "Indicates if a left LCMA warning shall be shown to the driver or not.";
CM_ SG_ 64 LcmaIndcnRi_UB "Update bit for signal LcmaIndcnRi";
CM_ SG_ 64 PassLoadAndStoreReq_UB "Update bit for signal group PassLoadAndStoreReq; PassLoadAndStoreReqErgoPosn PassLoadAndStoreReqErgoSetgEve ";
CM_ SG_ 64 PassLoadAndStoreReqErgoPosn "Handles memory buttons on passenger side for passenger seat
When to load, automove or store ergonomic settings Ergonomic position";
CM_ SG_ 64 PassLoadAndStoreReqErgoSetgEve "Handles memory buttons on passenger side for passenger seat
When to load, automove or store ergonomic settings What ergonomic event to perform";
CM_ SG_ 64 SaveSetgToMemPrmnt "Signal for personal settings saving concept

0: Profile locked, no saving to be performed
1: On the event (toggle 0 to 1) settings shall be saved (manually saving)
2: Automatic saving";
CM_ SG_ 64 SaveSetgToMemPrmnt_UB "Update bit for signal SaveSetgToMemPrmnt";
CM_ SG_ 64 TrNoKeyPrsntAcoustReq "TrNoKeyPrsntAcoustReq - Request for audible feedback sound when no valid key is present

When tailgate shutface close/lock button is pressed, and there is no valid key present within the tailgate zone, tailgate will not close and the vehicle will not lock. Instead, there will be an audible alert to the driver via POT ECU sounder. This signal is used to request the audible feedback.

The audible sound shall be given when the signal changes value from off to on.";
CM_ SG_ 64 TrNoKeyPrsntAcoustReq_UB "Update bit for signal TrNoKeyPrsntAcoustReq";
CM_ SG_ 64 TrOpenerReq_UB "Update bit for signal group TrOpenerReq; TrOpenerReqTrOpenerReq TrOpenerReqTrOpenerTrigSrc ";
CM_ SG_ 64 TrOpenerReqTrOpenerReq "TrOpenerReq - Tailgate/Bootlid Opener Request

Request signal to POT ECU. Signal contains type of request and trig source of request:

TrOpenerReq:
TrOpenerIdle - No request
TrOpenerOpen - Request to Open
TrOpenerCls - Request to Close
TrOpenerStop - Request to stop any ongoing tailgate/bootlid movement

TrOpenerTrigSrc:
TrNoTrigSrc - No trig source
TrKeyRem - Remote Key
TrSwtIntr - Interior switch (instrument panel)
TrByFootOper - FMDM (Foot Movement Detection Module)
TrHndlOutd - Outer door handle
TrShutFace - Shutface switch (located at bottom of tailgate/bootlid, facing user when tailgate/bootlid is open)
 Tailgate Opener Request";
CM_ SG_ 64 TrOpenerReqTrOpenerTrigSrc "TrOpenerReq - Tailgate/Bootlid Opener Request

Request signal to POT ECU. Signal contains type of request and trig source of request:

TrOpenerReq:
TrOpenerIdle - No request
TrOpenerOpen - Request to Open
TrOpenerCls - Request to Close
TrOpenerStop - Request to stop any ongoing tailgate/bootlid movement

TrOpenerTrigSrc:
TrNoTrigSrc - No trig source
TrKeyRem - Remote Key
TrSwtIntr - Interior switch (instrument panel)
TrByFootOper - FMDM (Foot Movement Detection Module)
TrHndlOutd - Outer door handle
TrShutFace - Shutface switch (located at bottom of tailgate/bootlid, facing user when tailgate/bootlid is open)
 Trig Source";
CM_ SG_ 64 TwliBriSts "Day/night status signal. Lux value (not this signal) sent from SUS to CEM and CEM sets day or night signal.";
CM_ SG_ 64 TwliBriSts_UB "Update bit for signal TwliBriSts";
CM_ SG_ 64 VehMtnStChks "Vehicle motion state information based on wheel speed sensors. Provides information about vehicle stand still and vehicle rolling direction. Checksum for vehicle motion state";
CM_ SG_ 64 VehMtnStCntr "Vehicle motion state information based on wheel speed sensors. Provides information about vehicle stand still and vehicle rolling direction. Counter for vehicle motion state";
CM_ SG_ 64 VehMtnStSafe "Vehicle motion state information based on wheel speed sensors. Provides information about vehicle stand still and vehicle rolling direction. Vehicle motion state";
CM_ SG_ 64 VehMtnStSafeGroup_UB "Update bit for signal group VehMtnStSafeGroup; VehMtnStChks VehMtnStCntr VehMtnStSafe ";
CM_ SG_ 243 CrashSts2 "Information if a crash has been detected by SRS.";
CM_ SG_ 243 CrashSts2_UB "Update bit for signal CrashSts2";
CM_ SG_ 245 RecOfImpctSafeChks "Crash information signalling Check sum";
CM_ SG_ 245 RecOfImpctSafeCntr "Crash information signalling Counter";
CM_ SG_ 245 RecOfImpctSafeCrashFrnt "Crash information signalling";
CM_ SG_ 245 RecOfImpctSafeCrashLargeAnimal "Crash information signalling";
CM_ SG_ 245 RecOfImpctSafeCrashOffroadA "Crash information signalling";
CM_ SG_ 245 RecOfImpctSafeCrashOffroadD "Crash information signalling";
CM_ SG_ 245 RecOfImpctSafeCrashOffroadRT "Crash information signalling";
CM_ SG_ 245 RecOfImpctSafeCrashOffroadRTseve "Crash information signalling";
CM_ SG_ 245 RecOfImpctSafeCrashOz "Crash information signalling";
CM_ SG_ 245 RecOfImpctSafeCrashPed "Crash information signalling";
CM_ SG_ 245 RecOfImpctSafeCrashRe "Crash information signalling";
CM_ SG_ 245 RecOfImpctSafeCrashRollovr "Crash information signalling";
CM_ SG_ 245 RecOfImpctSafeCrashSideLe "Crash information signalling";
CM_ SG_ 245 RecOfImpctSafeCrashSideRi "Crash information signalling";
CM_ SG_ 245 RecOfImpctSafeCrashState "Crash information signalling State of the crash";
CM_ SG_ 245 RecOfImpctSafeImpctDvx "Crash information signalling Delta-V longitudinal kph";
CM_ SG_ 245 RecOfImpctSafeImpctDvy "Crash information signalling Delta-V lateral kph";
CM_ SG_ 245 RecOfImpctSafeImpctRollAg "Crash information signalling Cumulative roll angle degrees";
CM_ SG_ 245 RecOfImpctSafeVehOri "Crash information signalling Vehicle orientation once crash subsides";
CM_ SG_ 176 BltLockStAtDrvr_UB "Update bit for signal group BltLockStAtDrvr; BltLockStAtDrvrForBltLockSt1 BltLockStAtDrvrForDevErrSts2 ";
CM_ SG_ 176 BltLockStAtDrvrForBltLockSt1 "State of belt lock at driver seating position Belt lock state, locked/unlocked";
CM_ SG_ 176 BltLockStAtDrvrForDevErrSts2 "State of belt lock at driver seating position Belt lock status, OK/NOK";
CM_ SG_ 176 BltLockStAtPass_UB "Update bit for signal group BltLockStAtPass; BltLockStAtPassForBltLockSt1 BltLockStAtPassForBltLockSts ";
CM_ SG_ 176 BltLockStAtPassForBltLockSt1 "State of belt lock at passenger seating position Belt lock state, locked/unlocked";
CM_ SG_ 176 BltLockStAtPassForBltLockSts "State of belt lock at passenger seating position Belt lock status, OK/NOK";
CM_ SG_ 176 BltLockStAtRowSecLe_UB "Update bit for signal group BltLockStAtRowSecLe; BltLockStAtRowSecLeForBltLockEquid BltLockStAtRowSecLeForBltLockSt1 BltLockStAtRowSecLeForBltLockSts ";
CM_ SG_ 176 BltLockStAtRowSecLeForBltLockEqu "State of belt lock at seating position at left of second row If the belt lock is equipped";
CM_ SG_ 176 BltLockStAtRowSecLeForBltLockSt1 "State of belt lock at seating position at left of second row Belt lock state,  locked/unlocked";
CM_ SG_ 176 BltLockStAtRowSecLeForBltLockSts "State of belt lock at seating position at left of second row Belt lock status, OK/NOK";
CM_ SG_ 176 BltLockStAtRowSecMid_UB "Update bit for signal group BltLockStAtRowSecMid; BltLockStAtRowSecMidForBltLockEquid BltLockStAtRowSecMidForBltLockSt1 BltLockStAtRowSecMidForBltLockSts ";
CM_ SG_ 176 BltLockStAtRowSecMidForBltLockEq "State of belt lock at seating position at middle of second row If the belt lock is equipped";
CM_ SG_ 176 BltLockStAtRowSecMidForBltLockSt "State of belt lock at seating position at middle of second row Belt lock state,  locked/unlocked";
CM_ SG_ 176 BltLockStAtRowSecMidForBltL_0000 "State of belt lock at seating position at middle of second row Belt lock status, OK/NOK";
CM_ SG_ 176 BltLockStAtRowSecRi_UB "Update bit for signal group BltLockStAtRowSecRi; BltLockStAtRowSecRiForBltLockEquid BltLockStAtRowSecRiForBltLockSt1 BltLockStAtRowSecRiForBltLockSts ";
CM_ SG_ 176 BltLockStAtRowSecRiForBltLockEqu "State of belt lock at seating position at right of second row If the belt lock is equipped";
CM_ SG_ 176 BltLockStAtRowSecRiForBltLockSt1 "State of belt lock at seating position at right of second row Belt lock state,  locked/unlocked";
CM_ SG_ 176 BltLockStAtRowSecRiForBltLockSts "State of belt lock at seating position at right of second row Belt lock status, OK/NOK";
CM_ SG_ 176 BltLockStAtRowThrdLe_UB "Update bit for signal group BltLockStAtRowThrdLe; BltLockStAtRowThrdLeForBltLockEquid BltLockStAtRowThrdLeForBltLockSt1 BltLockStAtRowThrdLeForBltLockSts ";
CM_ SG_ 176 BltLockStAtRowThrdLeForBltLockEq "State of belt lock at seating position at left of third row If the belt lock is equipped";
CM_ SG_ 176 BltLockStAtRowThrdLeForBltLockSt "State of belt lock at seating position at left of third row Belt lock state,  locked/unlocked";
CM_ SG_ 176 BltLockStAtRowThrdLeForBltL_0000 "State of belt lock at seating position at left of third row Belt lock status, OK/NOK";
CM_ SG_ 176 BltLockStAtRowThrdRi_UB "Update bit for signal group BltLockStAtRowThrdRi; BltLockStAtRowThrdRiForBltLockEquid BltLockStAtRowThrdRiForBltLockSt1 BltLockStAtRowThrdRiForBltLockSts ";
CM_ SG_ 176 BltLockStAtRowThrdRiForBltLockEq "State of belt lock at seating position at right of third row If the belt lock is equipped";
CM_ SG_ 176 BltLockStAtRowThrdRiForBltLockSt "State of belt lock at seating position at right of third row Belt lock state,  locked/unlocked";
CM_ SG_ 176 BltLockStAtRowThrdRiForBltL_0000 "State of belt lock at seating position at right of third row Belt lock status, OK/NOK";
CM_ SG_ 176 BrkFldLvl "Warning request for low brake fluid level.";
CM_ SG_ 176 BrkFldLvl_UB "Update bit for signal BrkFldLvl";
CM_ SG_ 176 ChrgnTyp "The selected charging type";
CM_ SG_ 176 ChrgnTyp_UB "Update bit for signal ChrgnTyp";
CM_ SG_ 176 EngCooltLvl "Engine coolant level. 
0 = High coolant level (normal)
1 = Low coolant level";
CM_ SG_ 176 EngCooltLvl_UB "Update bit for signal EngCooltLvl";
CM_ SG_ 176 ErsStrtApplSts "The primary state of the ERS application";
CM_ SG_ 176 ErsStrtApplSts_UB "Update bit for signal ErsStrtApplSts";
CM_ SG_ 176 HvEgyCnsAllwdForClima "How much available energy is available for compartment climatisation. Estimated available energy from wall socket or Hv battery.";
CM_ SG_ 176 HvEgyCnsAllwdForClima_UB "Update bit for signal HvEgyCnsAllwdForClima";
CM_ SG_ 288 ImobDataRemMgrChk0 "Flag to TEM that RVI challenge is available and 5 bytes challenge Challenge byte 0";
CM_ SG_ 288 ImobDataRemMgrChk1 "Flag to TEM that RVI challenge is available and 5 bytes challenge Challenge Byte 1";
CM_ SG_ 288 ImobDataRemMgrChk2 "Flag to TEM that RVI challenge is available and 5 bytes challenge Challenge byte 2";
CM_ SG_ 288 ImobDataRemMgrChk3 "Flag to TEM that RVI challenge is available and 5 bytes challenge Challenge byte 3";
CM_ SG_ 288 ImobDataRemMgrChk4 "Flag to TEM that RVI challenge is available and 5 bytes challenge Challenge byte 4";
CM_ SG_ 288 ImobRemMgrChk_UB "Update bit for signal group ImobRemMgrChk; ImobDataRemMgrChk0 ImobDataRemMgrChk1 ImobDataRemMgrChk2 ImobDataRemMgrChk3 ImobDataRemMgrChk4 ImobRemMgrChkSts ";
CM_ SG_ 288 ImobRemMgrChkSts "Flag to TEM that RVI challenge is available and 5 bytes challenge Challenge available";
CM_ SG_ 288 ImobVehRemMgrSts "RVI status from CEM to TEM Status för RVI manager";
CM_ SG_ 288 ImobVehRemMgrSts1_UB "Update bit for signal group ImobVehRemMgrSts1; ImobVehRemMgrSts SpdLimRemMgrSts ";
CM_ SG_ 288 ModOnLiInten "Controls the intensity of the Mood Light situated on the OHx.
Set by user setting.";
CM_ SG_ 288 ModOnLiInten_UB "Update bit for signal ModOnLiInten";
CM_ SG_ 288 SpdLimRemMgrSts "RVI status from CEM to TEM Remote vehicle slow down";
CM_ SG_ 288 StrtInProgs "Indicating to HMI that a driver start is initiated ";
CM_ SG_ 288 StrtInProgs_UB "Update bit for signal StrtInProgs";
CM_ SG_ 224 ActvnOfTrlrFogLiCmd "Controls the trailer foglight on and off.";
CM_ SG_ 224 ActvnOfTrlrFogLiCmd_UB "Update bit for signal ActvnOfTrlrFogLiCmd";
CM_ SG_ 224 CmptmtClngPreStrtReq "Activate function clean compartment. ";
CM_ SG_ 224 CmptmtClngPreStrtReq_UB "Update bit for signal CmptmtClngPreStrtReq";
CM_ SG_ 224 DoorPassReSts "DoorPassReSts - Passenger Side Rear Door Status

Ukwn - Unknown status
Opend - Opened
Clsd - Closed";
CM_ SG_ 224 DoorPassReSts_UB "Update bit for signal DoorPassReSts";
CM_ SG_ 224 DoorPassSts "DoorPassSts - Passenger Door Status

Ukwn - Unknown status
Opend - Opened
Clsd - Closed";
CM_ SG_ 224 DoorPassSts_UB "Update bit for signal DoorPassSts";
CM_ SG_ 224 DrvrSeatDispMassgFct_UB "Update bit for signal group DrvrSeatDispMassgFct; DrvrSeatDispMassgFctMassgInten DrvrSeatDispMassgFctMassgProg DrvrSeatDispMassgFctMassgSpdLvl DrvrSeatDispMassgFctOnOff ";
CM_ SG_ 224 DrvrSeatDispMassgFctMassgInten "Distributes massage settings for the driver.
 Massage program Intensity Level";
CM_ SG_ 224 DrvrSeatDispMassgFctMassgProg "Distributes massage settings for the driver.
 Massage Programs Types";
CM_ SG_ 224 DrvrSeatDispMassgFctMassgSpdLvl "Distributes massage settings for the driver.
 Massage program Speed Level";
CM_ SG_ 224 DrvrSeatDispMassgFctOnOff "Distributes massage settings for the driver.
 Turn on or off seat massage";
CM_ SG_ 224 HvPwrAvlForClimaEstimd "An estimation of how much HV-power that is available for climatization.";
CM_ SG_ 224 HvPwrAvlForClimaEstimd_UB "Update bit for signal HvPwrAvlForClimaEstimd";
CM_ SG_ 224 IntrBriSts "Rheostat setting.
Set by user through rheostat wheel situated on MyCar Module.";
CM_ SG_ 224 IntrBriSts_UB "Update bit for signal IntrBriSts";
CM_ SG_ 224 MirrTintgCmd "Dimming level of the outer rear view mirrors. 0-100%.";
CM_ SG_ 224 MirrTintgCmd_UB "Update bit for signal MirrTintgCmd";
CM_ SG_ 224 PassSeatDispMassgFct_UB "Update bit for signal group PassSeatDispMassgFct; PassSeatDispMassgFctMassgInten PassSeatDispMassgFctMassgProg PassSeatDispMassgFctMassgSpdLvl PassSeatDispMassgFctOnOff ";
CM_ SG_ 224 PassSeatDispMassgFctMassgInten "Distributes massage settings for the passenger
 Massage program Intensity Level";
CM_ SG_ 224 PassSeatDispMassgFctMassgProg "Distributes massage settings for the passenger
 Massage Programs Types";
CM_ SG_ 224 PassSeatDispMassgFctMassgSpdLvl "Distributes massage settings for the passenger
 Massage program Speed Level";
CM_ SG_ 224 PassSeatDispMassgFctOnOff "Distributes massage settings for the passenger
 Turn on or off seat massage";
CM_ SG_ 224 TrlrLampChkReq "Distribution of trailer lamp check activation from DIM
";
CM_ SG_ 224 TrlrLampChkReq_UB "Update bit for signal TrlrLampChkReq";
CM_ SG_ 224 TrPosnUpprProgmReq "TrPosnUpprProgmReq - Tailgate Upper Position Program Request

When user makes a long press on shutface switch, POT shall program the current tailgate/bootlid position. For every future POT opening of the tailgate/bootlid, the movement shall not proceed above this angle.

POT shall program upper position when this signal changes value from Off to On.";
CM_ SG_ 224 TrPosnUpprProgmReq_UB "Update bit for signal TrPosnUpprProgmReq";
CM_ SG_ 224 TrSts "TrSts - Tailgate/Bootlid Status

Ukwn - Unknown status
Opend - Opened
Clsd - Closed";
CM_ SG_ 224 TrSts_UB "Update bit for signal TrSts";
CM_ SG_ 240 ActvnOfPosnReCmd "Activation of rear position light including rear SML (Side Marker Light).";
CM_ SG_ 240 ActvnOfPosnReCmd_UB "Update bit for signal ActvnOfPosnReCmd";
CM_ SG_ 240 ActvnOfWshrFrntSafe_UB "Update bit for signal ActvnOfWshrFrntSafe";
CM_ SG_ 240 AsyFanSts "Indicates if the ASDM cooling fan is running.";
CM_ SG_ 240 AsyFanSts_UB "Update bit for signal AsyFanSts";
CM_ SG_ 240 CarModSts1 " VehModMngtGlbSafe1  is a system signal group sent globally in an end to end protected record that consists of  CarModSts1, CarModSubtypWdCarModSubtyp, UsgModSts,  EgyLvlElecMai,  EgyLvlElecSubtyp,  PwrLvlElecMai, PwrLvlElecSubtyp and FltEngyCnsWdSts

CarModSts1 : Factory, Transport, Dyno, Normal. Crash 

UsgModSts : Abandoned, Inactive, Convenience, Active, Driving

CarModSubtypWdCarModSubtyp: examples for CarModSubtyp: Factory Driving, Transport Driving Main CarMode Data";
CM_ SG_ 240 CarModSubtypWdCarModSubtyp " VehModMngtGlbSafe1  is a system signal group sent globally in an end to end protected record that consists of  CarModSts1, CarModSubtypWdCarModSubtyp, UsgModSts,  EgyLvlElecMai,  EgyLvlElecSubtyp,  PwrLvlElecMai, PwrLvlElecSubtyp and FltEngyCnsWdSts

CarModSts1 : Factory, Transport, Dyno, Normal. Crash 

UsgModSts : Abandoned, Inactive, Convenience, Active, Driving

CarModSubtypWdCarModSubtyp: examples for CarModSubtyp: Factory Driving, Transport Driving CarMode Sub Data";
CM_ SG_ 240 DrvrCtrlOfPassSeatFrntReqd "Distribution of activation request for gentleman function
";
CM_ SG_ 240 DrvrCtrlOfPassSeatFrntReqd_UB "Update bit for signal DrvrCtrlOfPassSeatFrntReqd";
CM_ SG_ 240 DrvrDesDir "Desired Driver Direction
 
Desired Driver Direction is an interpretation of driver input. 
It specifies in which longitudinal direction the driver requests that any accelerating propulsive torque shall be delivered. There are three possible directions:
 
1. Forward - The driver intends propulsion to move the vehicle forward
2. Reverse - The driver intends propulsion to move the vehicle backwards
3. Neutral - The driver intends no powered movement of the vehicle 
 
Note that the latter in the case of a conventional automatic gearbox thus applies to gear positions 'N' and 'P'.
 
Note that Desired Driver Direction describes the driver's request, which not necessarily coincides with the actual state of the powertrain at all times. In e.g. shift-by-wire solutions the driver's choice of 'driving direction' is based on gear selector input. Changes to Desired Driving Direction will thus be known a short while before the powertrain has reconfigured accordingly.
 
Note that Desired Driver Direction will n";
CM_ SG_ 240 DrvrDesDir_UB "Update bit for signal DrvrDesDir";
CM_ SG_ 240 EgyLvlElecMai " VehModMngtGlbSafe1  is a system signal group sent globally in an end to end protected record that consists of  CarModSts1, CarModSubtypWdCarModSubtyp, UsgModSts,  EgyLvlElecMai,  EgyLvlElecSubtyp,  PwrLvlElecMai, PwrLvlElecSubtyp and FltEngyCnsWdSts

CarModSts1 : Factory, Transport, Dyno, Normal. Crash 

UsgModSts : Abandoned, Inactive, Convenience, Active, Driving

CarModSubtypWdCarModSubtyp: examples for CarModSubtyp: Factory Driving, Transport Driving Main Data for ElEnergyLevel";
CM_ SG_ 240 EgyLvlElecSubtyp " VehModMngtGlbSafe1  is a system signal group sent globally in an end to end protected record that consists of  CarModSts1, CarModSubtypWdCarModSubtyp, UsgModSts,  EgyLvlElecMai,  EgyLvlElecSubtyp,  PwrLvlElecMai, PwrLvlElecSubtyp and FltEngyCnsWdSts

CarModSts1 : Factory, Transport, Dyno, Normal. Crash 

UsgModSts : Abandoned, Inactive, Convenience, Active, Driving

CarModSubtypWdCarModSubtyp: examples for CarModSubtyp: Factory Driving, Transport Driving Sub Data ElEnergyLevel";
CM_ SG_ 240 FltEgyCnsWdSts " VehModMngtGlbSafe1  is a system signal group sent globally in an end to end protected record that consists of  CarModSts1, CarModSubtypWdCarModSubtyp, UsgModSts,  EgyLvlElecMai,  EgyLvlElecSubtyp,  PwrLvlElecMai, PwrLvlElecSubtyp and FltEngyCnsWdSts

CarModSts1 : Factory, Transport, Dyno, Normal. Crash 

UsgModSts : Abandoned, Inactive, Convenience, Active, Driving

CarModSubtypWdCarModSubtyp: examples for CarModSubtyp: Factory Driving, Transport Driving Energy Consumption Fault";
CM_ SG_ 240 NetCtrlrActvt_UB "Update bit for signal group NetCtrlrActvt; NetCtrlrActvtPrio NetCtrlrActvtResourceGroup ";
CM_ SG_ 240 NetCtrlrActvtPrio "Network ControllerActivate:
Wakeup signal from the VCM, with the purpose of waking up other infotainment nodes when a function on that node is requested.
Bit 1: Prio high/normal
Bit 2-5: Requested function number (Function no 0-15) Prority of resource request";
CM_ SG_ 240 NetCtrlrActvtResourceGroup "Network ControllerActivate:
Wakeup signal from the VCM, with the purpose of waking up other infotainment nodes when a function on that node is requested.
Bit 1: Prio high/normal
Bit 2-5: Requested function number (Function no 0-15) Resource group member";
CM_ SG_ 240 PwrLvlElecMai " VehModMngtGlbSafe1  is a system signal group sent globally in an end to end protected record that consists of  CarModSts1, CarModSubtypWdCarModSubtyp, UsgModSts,  EgyLvlElecMai,  EgyLvlElecSubtyp,  PwrLvlElecMai, PwrLvlElecSubtyp and FltEngyCnsWdSts

CarModSts1 : Factory, Transport, Dyno, Normal. Crash 

UsgModSts : Abandoned, Inactive, Convenience, Active, Driving

CarModSubtypWdCarModSubtyp: examples for CarModSubtyp: Factory Driving, Transport Driving Main Data for ElPowerLevel";
CM_ SG_ 240 PwrLvlElecSubtyp " VehModMngtGlbSafe1  is a system signal group sent globally in an end to end protected record that consists of  CarModSts1, CarModSubtypWdCarModSubtyp, UsgModSts,  EgyLvlElecMai,  EgyLvlElecSubtyp,  PwrLvlElecMai, PwrLvlElecSubtyp and FltEngyCnsWdSts

CarModSts1 : Factory, Transport, Dyno, Normal. Crash 

UsgModSts : Abandoned, Inactive, Convenience, Active, Driving

CarModSubtypWdCarModSubtyp: examples for CarModSubtyp: Factory Driving, Transport Driving Sub Data for ElPowerLevel";
CM_ SG_ 240 UsgModSts " VehModMngtGlbSafe1  is a system signal group sent globally in an end to end protected record that consists of  CarModSts1, CarModSubtypWdCarModSubtyp, UsgModSts,  EgyLvlElecMai,  EgyLvlElecSubtyp,  PwrLvlElecMai, PwrLvlElecSubtyp and FltEngyCnsWdSts

CarModSts1 : Factory, Transport, Dyno, Normal. Crash 

UsgModSts : Abandoned, Inactive, Convenience, Active, Driving

CarModSubtypWdCarModSubtyp: examples for CarModSubtyp: Factory Driving, Transport Driving";
CM_ SG_ 240 VehModMngtGlbSafe1_UB "Update bit for signal group VehModMngtGlbSafe1; CarModSts1 CarModSubtypWdCarModSubtyp EgyLvlElecMai EgyLvlElecSubtyp FltEgyCnsWdSts PwrLvlElecMai PwrLvlElecSubtyp UsgModSts VehModMngtGlbSafe1Chks VehModMngtGlbSafe1Cntr ";
CM_ SG_ 240 VehModMngtGlbSafe1Chks " VehModMngtGlbSafe1  is a system signal group sent globally in an end to end protected record that consists of  CarModSts1, CarModSubtypWdCarModSubtyp, UsgModSts,  EgyLvlElecMai,  EgyLvlElecSubtyp,  PwrLvlElecMai, PwrLvlElecSubtyp and FltEngyCnsWdSts

CarModSts1 : Factory, Transport, Dyno, Normal. Crash 

UsgModSts : Abandoned, Inactive, Convenience, Active, Driving

CarModSubtypWdCarModSubtyp: examples for CarModSubtyp: Factory Driving, Transport Driving End to End Checksum";
CM_ SG_ 240 VehModMngtGlbSafe1Cntr " VehModMngtGlbSafe1  is a system signal group sent globally in an end to end protected record that consists of  CarModSts1, CarModSubtypWdCarModSubtyp, UsgModSts,  EgyLvlElecMai,  EgyLvlElecSubtyp,  PwrLvlElecMai, PwrLvlElecSubtyp and FltEngyCnsWdSts

CarModSts1 : Factory, Transport, Dyno, Normal. Crash 

UsgModSts : Abandoned, Inactive, Convenience, Active, Driving

CarModSubtypWdCarModSubtyp: examples for CarModSubtyp: Factory Driving, Transport Driving End to End Counter";
CM_ SG_ 256 CamHeatrActv "Indicates if the windscreen heater in front of the radar and camera is active.";
CM_ SG_ 256 CamHeatrActv_UB "Update bit for signal CamHeatrActv";
CM_ SG_ 256 DefrstSts_UB "Update bit for signal group DefrstSts; MirrDefrstSts WindDefrstFrntSts WinDefrstReSts ";
CM_ SG_ 256 EngPAmbAir1 "Ambient Air Pressure messured inside Engine control unit.";
CM_ SG_ 256 EngPAmbAir1_UB "Update bit for signal EngPAmbAir1";
CM_ SG_ 256 ExtrMirrFoldSetg_UB "Update bit for signal group ExtrMirrFoldSetg; ExtrMirrFoldSetgPen ExtrMirrFoldSetgSts ";
CM_ SG_ 256 ExtrMirrFoldSetgPen "Determine the setting for Mirror Folding
 The associated Profile ID(s) to which the main setting (element Sts) belongs";
CM_ SG_ 256 ExtrMirrFoldSetgSts "Determine the setting for Mirror Folding
 The setting main value.  ";
CM_ SG_ 256 ExtrMirrTiltSetg2_UB "Update bit for signal group ExtrMirrTiltSetg2; ExtrMirrTiltSetg2IdPen ExtrMirrTiltSetg2MirrDrvr ExtrMirrTiltSetg2MirrPass ";
CM_ SG_ 256 ExtrMirrTiltSetg2IdPen "Determine the setting for Mirror Tilting
 Personal Settings";
CM_ SG_ 256 ExtrMirrTiltSetg2MirrDrvr "Determine the setting for Mirror Tilting
 Driver side mirror tilting";
CM_ SG_ 256 ExtrMirrTiltSetg2MirrPass "Determine the setting for Mirror Tilting
 Passenger side mirror tilting";
CM_ SG_ 256 HoodSts "HoodSts - Hood Status

Ukwn - Unknown status
Opend - Opened
Clsd - Closed";
CM_ SG_ 256 HoodSts_UB "Update bit for signal HoodSts";
CM_ SG_ 256 LockgCenSts_UB "Update bit for signal group LockgCenSts; LockgCenStsLockSt LockgCenStsUpdEve LockgCenTrigSrc ";
CM_ SG_ 256 LockgCenStsForUsrFb "LockgCenStsForUsrFb - Central Locking Status for User Feedback

The signal is used to communicate central locking status to the user of the vehicle

Undefd - ?Undefined status (to be used when sufficient information about door and lock status is not available)
Opend - ?At least one door or taligate/bootlid or hood is open
Clsd (Closed) - ?All doors, tailgate/bootlid and hood are closed (at least one door or tailgate/bootlid is unlocked)
Lockd (Locked) - ?All doors, tailgate/bootlid and hood are closed and all doors and tailgate/bootlid are locked (at least one door is unsafed)
Safe - ?All doors, tailgate/bootlid and hood are closed, tailgate/bootlid is locked and all doors are safed (double locked)";
CM_ SG_ 256 LockgCenStsForUsrFb_UB "Update bit for signal LockgCenStsForUsrFb";
CM_ SG_ 256 LockgCenStsLockSt "Signal LockgCenSts provides central locking status to other subsystems.

Signal is a record with three items:

- LockSt (Lock State)
- TrigSrc (Trig Source)
- UpdEve (Will be set to TRUE during one second at each new central locking or unlocking event)

The signal shall be interpreted as the latest executed central locking request performed by user or system. Note that individual side doors and tailgate/bootlid may have a lock status which differs from the central locking status. Hence, this signal shall not be used for customer feedback regarding central locking state of the vehicle. Lock status";
CM_ SG_ 256 LockgCenStsUpdEve "Signal LockgCenSts provides central locking status to other subsystems.

Signal is a record with three items:

- LockSt (Lock State)
- TrigSrc (Trig Source)
- UpdEve (Will be set to TRUE during one second at each new central locking or unlocking event)

The signal shall be interpreted as the latest executed central locking request performed by user or system. Note that individual side doors and tailgate/bootlid may have a lock status which differs from the central locking status. Hence, this signal shall not be used for customer feedback regarding central locking state of the vehicle. New event";
CM_ SG_ 256 LockgCenTrigSrc "Signal LockgCenSts provides central locking status to other subsystems.

Signal is a record with three items:

- LockSt (Lock State)
- TrigSrc (Trig Source)
- UpdEve (Will be set to TRUE during one second at each new central locking or unlocking event)

The signal shall be interpreted as the latest executed central locking request performed by user or system. Note that individual side doors and tailgate/bootlid may have a lock status which differs from the central locking status. Hence, this signal shall not be used for customer feedback regarding central locking state of the vehicle. Trig source";
CM_ SG_ 256 MirrDefrstSts "Front windscreen, rear window and exterior rear view mirror electrical defroster status. Includes information regarding how they have been activated and their availability. Mirror defrost status";
CM_ SG_ 256 SteerWhlHeatgPwrAct "The calculated power draw of the heated steering wheel (averaged over the last 30 s)";
CM_ SG_ 256 SteerWhlHeatgPwrAct_UB "Update bit for signal SteerWhlHeatgPwrAct";
CM_ SG_ 256 WindDefrstFrntSts "Front windscreen, rear window and exterior rear view mirror electrical defroster status. Includes information regarding how they have been activated and their availability. Status of windscreen defroster";
CM_ SG_ 256 WinDefrstReSts "Front windscreen, rear window and exterior rear view mirror electrical defroster status. Includes information regarding how they have been activated and their availability. Rear window defroster status";
CM_ SG_ 320 DispBattEgyIn "Electric battery energy absorbed by the HV Battery. 

NB: Only power flowing into HV battery is integrated. 

Energy=integral( max( battery power flowing in , 0) )";
CM_ SG_ 320 DispBattEgyIn_UB "Update bit for signal DispBattEgyIn";
CM_ SG_ 320 DispBattEgyOut "Electric battery energy delivered by the HV Battery. 

NB: Only power flowing out of the HV battery is integrated. 

Energy=integral( max( battery power flowing out , 0) )";
CM_ SG_ 320 DispBattEgyOut_UB "Update bit for signal DispBattEgyOut";
CM_ SG_ 320 HmiCmptmtAirDistbnFrnt "By user requested air distribution for first and second row";
CM_ SG_ 320 HmiCmptmtAirDistbnFrnt_UB "Update bit for signal HmiCmptmtAirDistbnFrnt";
CM_ SG_ 320 HmiDefrstMaxReq "Max defroster request by user.";
CM_ SG_ 320 HmiDefrstMaxReq_UB "Update bit for signal HmiDefrstMaxReq";
CM_ SG_ 320 HmiHvacFanLvlFrnt "User requested fan level for first row.";
CM_ SG_ 320 HmiHvacFanLvlFrnt_UB "Update bit for signal HmiHvacFanLvlFrnt";
CM_ SG_ 320 HmiHvacFanLvlRe "User requested fan level for second row";
CM_ SG_ 320 HmiHvacFanLvlRe_UB "Update bit for signal HmiHvacFanLvlRe";
CM_ SG_ 320 HmiHvacRecircCmd "Manual recirculation requested by user. ";
CM_ SG_ 320 HmiHvacRecircCmd_UB "Update bit for signal HmiHvacRecircCmd";
CM_ SG_ 320 HmiHvacReCtrl "Third row climate activated. ";
CM_ SG_ 320 HmiHvacReCtrl_UB "Update bit for signal HmiHvacReCtrl";
CM_ SG_ 320 ModOnLiCmd "Signal sent by CEM that tell when the Mood Light is allowed to be ON.
Mainly controled by Usage Mode.";
CM_ SG_ 320 ModOnLiCmd_UB "Update bit for signal ModOnLiCmd";
CM_ SG_ 320 ModOnLiTCmd "Sets the color of the Mood Light when the user has temperature option On.";
CM_ SG_ 320 ModOnLiTCmd_UB "Update bit for signal ModOnLiTCmd";
CM_ SG_ 320 ModOnLiTintgCmd "Sets what color the user has choosen for Mood Light or if the user has choosen to shift color for the Mood Light according to set temperature.";
CM_ SG_ 320 ModOnLiTintgCmd_UB "Update bit for signal ModOnLiTintgCmd";
CM_ SG_ 384 ActvnOfTrlrLiRvsg "Activation of reverse light.";
CM_ SG_ 384 ActvnOfTrlrLiRvsg_UB "Update bit for signal ActvnOfTrlrLiRvsg";
CM_ SG_ 384 ClimaEcoModRqrd "Signal for requesting post conditioning.";
CM_ SG_ 384 ClimaEcoModRqrd_UB "Update bit for signal ClimaEcoModRqrd";
CM_ SG_ 384 HeatrDurgDrvgReqd "Signal from HMI saying if additional heater is allowed or not.";
CM_ SG_ 384 HeatrDurgDrvgReqd_UB "Update bit for signal HeatrDurgDrvgReqd";
CM_ SG_ 384 HmiCmptmtCoolgReq "User request to use AC auto or off";
CM_ SG_ 384 HmiCmptmtCoolgReq_UB "Update bit for signal HmiCmptmtCoolgReq";
CM_ SG_ 384 HmiCmptmtTSp_UB "Update bit for signal group HmiCmptmtTSp; HmiCmptmtTSpForRowFirstLe HmiCmptmtTSpForRowFirstRi HmiCmptmtTSpForRowSecLe HmiCmptmtTSpForRowSecRi HmiCmptmtTSpSpclForRowFirstLe HmiCmptmtTSpSpclForRowFirstRi HmiCmptmtTSpSpclForRowSecLe HmiCmptmtTSpSpclForRowSecRi ";
CM_ SG_ 384 HmiCmptmtTSpForRowFirstLe "User requested set temperatures for all available climate zones First row, left side,  climate set point settings from HMI";
CM_ SG_ 384 HmiCmptmtTSpForRowFirstRi "User requested set temperatures for all available climate zones First row, right side, climate setpoint temperature from HMI";
CM_ SG_ 384 HmiCmptmtTSpForRowSecLe "User requested set temperatures for all available climate zones Second row, left side, climate setpoint temperature from HMI";
CM_ SG_ 384 HmiCmptmtTSpForRowSecRi "User requested set temperatures for all available climate zones Second row, right side, climate setpoint temperature from HMI";
CM_ SG_ 384 HmiCmptmtTSpSpclForRowFirstLe "User requested set temperatures for all available climate zones HI/LO setting first row left";
CM_ SG_ 384 HmiCmptmtTSpSpclForRowFirstRi "User requested set temperatures for all available climate zones HI/LO first row right";
CM_ SG_ 384 HmiCmptmtTSpSpclForRowSecLe "User requested set temperatures for all available climate zones HI/LO second row left side";
CM_ SG_ 384 HmiCmptmtTSpSpclForRowSecRi "User requested set temperatures for all available climate zones HI/LO second row, right side ";
CM_ SG_ 384 HvacCooltFlowAct "Actual coolant flow through HVAC unit generated by the engine coolant system control. (l/min)";
CM_ SG_ 384 HvacCooltFlowAct_UB "Update bit for signal HvacCooltFlowAct";
CM_ SG_ 384 SeatSwtLeSigThrd "Seat Switch Left Signal Third
";
CM_ SG_ 384 SeatSwtLeSigThrd_UB "Update bit for signal SeatSwtLeSigThrd";
CM_ SG_ 384 SeatSwtRiSigThrd "Seat Switch Right Signal Third
";
CM_ SG_ 384 SeatSwtRiSigThrd_UB "Update bit for signal SeatSwtRiSigThrd";
CM_ SG_ 400 ChrgnTiEstimd "Estimated charging time left.";
CM_ SG_ 400 ChrgnTiEstimd_UB "Update bit for signal ChrgnTiEstimd";
CM_ SG_ 400 DshbT "Measured and calculated values from sun sensor. 
SunLoad -  Sun intensity 
SunAzi - Azimuth to the sun, defined as angle from center of car to the sun. Values is from 0 to 360 with 0 pointing straight forward in the vehicles reference system. 
SunElevn - Elevation angle to the sun. 
SunElevnCmp - A compensated sun elevation signal, calculates actual sun elevation unaffected by clouds/objects. 
DshbT - Temperature measured in the component, at the dashboard.  Dashboard temperature";
CM_ SG_ 400 DshbTQf "Measured and calculated values from sun sensor. 
SunLoad -  Sun intensity 
SunAzi - Azimuth to the sun, defined as angle from center of car to the sun. Values is from 0 to 360 with 0 pointing straight forward in the vehicles reference system. 
SunElevn - Elevation angle to the sun. 
SunElevnCmp - A compensated sun elevation signal, calculates actual sun elevation unaffected by clouds/objects. 
DshbT - Temperature measured in the component, at the dashboard.  Dashboard temperature quality factor";
CM_ SG_ 400 SunAzi "Measured and calculated values from sun sensor. 
SunLoad -  Sun intensity 
SunAzi - Azimuth to the sun, defined as angle from center of car to the sun. Values is from 0 to 360 with 0 pointing straight forward in the vehicles reference system. 
SunElevn - Elevation angle to the sun. 
SunElevnCmp - A compensated sun elevation signal, calculates actual sun elevation unaffected by clouds/objects. 
DshbT - Temperature measured in the component, at the dashboard.  Sun azimuth";
CM_ SG_ 400 SunAziQf "Measured and calculated values from sun sensor. 
SunLoad -  Sun intensity 
SunAzi - Azimuth to the sun, defined as angle from center of car to the sun. Values is from 0 to 360 with 0 pointing straight forward in the vehicles reference system. 
SunElevn - Elevation angle to the sun. 
SunElevnCmp - A compensated sun elevation signal, calculates actual sun elevation unaffected by clouds/objects. 
DshbT - Temperature measured in the component, at the dashboard.  Sun azimuth quality factor";
CM_ SG_ 400 SunData_UB "Update bit for signal group SunData; DshbT DshbTQf SunAzi SunAziQf SunDataSunElevnCmp SunDataSunElevnCmpQf SunElevn SunElevnQf SunLoad SunLoadQF ";
CM_ SG_ 400 SunDataSunElevnCmp "Measured and calculated values from sun sensor. 
SunLoad -  Sun intensity 
SunAzi - Azimuth to the sun, defined as angle from center of car to the sun. Values is from 0 to 360 with 0 pointing straight forward in the vehicles reference system. 
SunElevn - Elevation angle to the sun. 
SunElevnCmp - A compensated sun elevation signal, calculates actual sun elevation unaffected by clouds/objects. 
DshbT - Temperature measured in the component, at the dashboard.  Compensated sun elevation signal";
CM_ SG_ 400 SunDataSunElevnCmpQf "Measured and calculated values from sun sensor. 
SunLoad -  Sun intensity 
SunAzi - Azimuth to the sun, defined as angle from center of car to the sun. Values is from 0 to 360 with 0 pointing straight forward in the vehicles reference system. 
SunElevn - Elevation angle to the sun. 
SunElevnCmp - A compensated sun elevation signal, calculates actual sun elevation unaffected by clouds/objects. 
DshbT - Temperature measured in the component, at the dashboard.  Compensated sun elevation quality factor";
CM_ SG_ 400 SunElevn "Measured and calculated values from sun sensor. 
SunLoad -  Sun intensity 
SunAzi - Azimuth to the sun, defined as angle from center of car to the sun. Values is from 0 to 360 with 0 pointing straight forward in the vehicles reference system. 
SunElevn - Elevation angle to the sun. 
SunElevnCmp - A compensated sun elevation signal, calculates actual sun elevation unaffected by clouds/objects. 
DshbT - Temperature measured in the component, at the dashboard.  Sun elevation";
CM_ SG_ 400 SunElevnQf "Measured and calculated values from sun sensor. 
SunLoad -  Sun intensity 
SunAzi - Azimuth to the sun, defined as angle from center of car to the sun. Values is from 0 to 360 with 0 pointing straight forward in the vehicles reference system. 
SunElevn - Elevation angle to the sun. 
SunElevnCmp - A compensated sun elevation signal, calculates actual sun elevation unaffected by clouds/objects. 
DshbT - Temperature measured in the component, at the dashboard.  Sun elevation quality factor";
CM_ SG_ 400 SunLoad "Measured and calculated values from sun sensor. 
SunLoad -  Sun intensity 
SunAzi - Azimuth to the sun, defined as angle from center of car to the sun. Values is from 0 to 360 with 0 pointing straight forward in the vehicles reference system. 
SunElevn - Elevation angle to the sun. 
SunElevnCmp - A compensated sun elevation signal, calculates actual sun elevation unaffected by clouds/objects. 
DshbT - Temperature measured in the component, at the dashboard.  Sun load";
CM_ SG_ 400 SunLoadQF "Measured and calculated values from sun sensor. 
SunLoad -  Sun intensity 
SunAzi - Azimuth to the sun, defined as angle from center of car to the sun. Values is from 0 to 360 with 0 pointing straight forward in the vehicles reference system. 
SunElevn - Elevation angle to the sun. 
SunElevnCmp - A compensated sun elevation signal, calculates actual sun elevation unaffected by clouds/objects. 
DshbT - Temperature measured in the component, at the dashboard.  Sun load quality factor";
CM_ SG_ 432 CnclHldChrgReq "Cancellation of request to hold charging due to timers. ";
CM_ SG_ 432 CnclHldChrgReq_UB "Update bit for signal CnclHldChrgReq";
CM_ SG_ 432 CoolgLimd "Present load on compressor. Use to evaluate if more cooling power is available.  Reduced or limited capacity";
CM_ SG_ 432 CoolgLoad "Present load on compressor. Use to evaluate if more cooling power is available.  Present cooling load";
CM_ SG_ 432 CoolgLoadGroup_UB "Update bit for signal group CoolgLoadGroup; CoolgLimd CoolgLoad ";
CM_ SG_ 432 DiagcHvacCooltVlvErr "Sending OBDII diagnostic status";
CM_ SG_ 432 DiagcHvacCooltVlvErr_UB "Update bit for signal DiagcHvacCooltVlvErr";
CM_ SG_ 432 EngCooltLoFlowReq "Coolant flow request to the auxillary waterpump. (l/min)";
CM_ SG_ 432 EngCooltLoFlowReq_UB "Update bit for signal EngCooltLoFlowReq";
CM_ SG_ 432 ErsStrtRes "This signal represents the result of the latest ErsOn command attempt or, if last ERS run was aborted, the reason for that abort";
CM_ SG_ 432 ErsStrtRes_UB "Update bit for signal ErsStrtRes";
CM_ SG_ 432 EvaprVlvReqRe "Request to open shut off valve for AC refridgerant to rear HVAC. 
When signal is true circuit shall be open and cooling in rear HVAC active.";
CM_ SG_ 432 EvaprVlvReqRe_UB "Update bit for signal EvaprVlvReqRe";
CM_ SG_ 432 FuTankPOkForFuHeatr "Signaling fuel tank pressure is Ok. Ok to use FOH. ";
CM_ SG_ 432 FuTankPOkForFuHeatr_UB "Update bit for signal FuTankPOkForFuHeatr";
CM_ SG_ 432 MirrDefrstAtDrvrCmd "Activation signal exterior rear view mirror electrical defroster driver side.";
CM_ SG_ 432 MirrDefrstAtDrvrCmd_UB "Update bit for signal MirrDefrstAtDrvrCmd";
CM_ SG_ 432 MirrDefrstAtPassCmd "Activation signal exterior rear view mirror electrical defroster passenger side.";
CM_ SG_ 432 MirrDefrstAtPassCmd_UB "Update bit for signal MirrDefrstAtPassCmd";
CM_ SG_ 432 VehSpdLgtSafe "Vehicle speed longitudinal based on wheel speed sensors and longitudinal acceleration.
end2endprotection=profile1A dataid='12345' Vehicle speed longitudinal";
CM_ SG_ 432 VehSpdLgtSafeChks "Vehicle speed longitudinal based on wheel speed sensors and longitudinal acceleration.
end2endprotection=profile1A dataid='12345' Checksum for vehicle speed longitudinal";
CM_ SG_ 432 VehSpdLgtSafeCntr "Vehicle speed longitudinal based on wheel speed sensors and longitudinal acceleration.
end2endprotection=profile1A dataid='12345' Counter for vehicle speed longitudinal checksum calculation";
CM_ SG_ 432 VehSpdLgtSafeGroup_UB "Update bit for signal group VehSpdLgtSafeGroup; VehSpdLgtSafe VehSpdLgtSafeChks VehSpdLgtSafeCntr VehSpdLgtSafeQf ";
CM_ SG_ 432 VehSpdLgtSafeQf "Vehicle speed longitudinal based on wheel speed sensors and longitudinal acceleration.
end2endprotection=profile1A dataid='12345' Qf for vehicle speed longitudinal";
CM_ SG_ 496 CmptmtCoolgSts "Status of AC system. ";
CM_ SG_ 496 CmptmtCoolgSts_UB "Update bit for signal CmptmtCoolgSts";
CM_ SG_ 496 EngOilLvlSts "Engine oil level status information.
If no status currently can be derived 'Not available' will be shown.";
CM_ SG_ 496 EngOilLvlSts_UB "Update bit for signal EngOilLvlSts";
CM_ SG_ 496 HmiSeatClima_UB "Update bit for signal group HmiSeatClima; HmiSeatHeatgForRowFirstLe HmiSeatHeatgForRowFirstRi HmiSeatHeatgForRowSecLe HmiSeatHeatgForRowSecRi HmiSeatVentnForRowFirstLe HmiSeatVentnForRowFirstRi ";
CM_ SG_ 496 HmiSeatHeatgForRowFirstLe "HMI/user requests for heating and ventilation of seats for first and second row. Heating level for seat first row left";
CM_ SG_ 496 HmiSeatHeatgForRowFirstRi "HMI/user requests for heating and ventilation of seats for first and second row. Heating level for seat first row right";
CM_ SG_ 496 HmiSeatHeatgForRowSecLe "HMI/user requests for heating and ventilation of seats for first and second row. Heating level for seat second row left";
CM_ SG_ 496 HmiSeatHeatgForRowSecRi "HMI/user requests for heating and ventilation of seats for first and second row. Heating level for seat second row right";
CM_ SG_ 496 HmiSeatVentnForRowFirstLe "HMI/user requests for heating and ventilation of seats for first and second row. Ventilation level for seat first row left";
CM_ SG_ 496 HmiSeatVentnForRowFirstRi "HMI/user requests for heating and ventilation of seats for first and second row. Ventilation level for seat first row right";
CM_ SG_ 496 HvClimaCmd "Information for climate if climatisation is allowed.";
CM_ SG_ 496 HvClimaCmd_UB "Update bit for signal HvClimaCmd";
CM_ SG_ 496 HvHeatgPwrAllwd "Power available for heating in real time. From wall socket if plugged in, from propulsion or high voltage battery.";
CM_ SG_ 496 HvHeatgPwrAllwd_UB "Update bit for signal HvHeatgPwrAllwd";
CM_ SG_ 496 SunCurtPosnSts "Position of the sun curtain";
CM_ SG_ 496 SunCurtPosnSts_UB "Update bit for signal SunCurtPosnSts";
BA_DEF_ SG_  "GenSigDataID" STRING ;
BA_DEF_ SG_  "GenSigFuncType" ENUM  "NoFunction","not-used","not-used","not-used","not-used","not-used","not-used","not-used","not-used","not-used","not-used","not-used","not-used","not-used","not-used","CHK","CNTR";
BA_DEF_ BU_  "NmAsrNodeIdentifier" HEX 0 4095;
BA_DEF_  "NmAsrBaseAddress" HEX 0 4095;
BA_DEF_  "NmAsrMessageCount" INT 0 4095;
BA_DEF_  "DBName" STRING ;
BA_DEF_ SG_  "SigGroup" STRING ;
BA_DEF_ BU_  "NodeLayerModules" STRING ;
BA_DEF_ BO_  "GenMsgILSupport" ENUM  "No","Yes";
BA_DEF_ BO_  "GenMsgCycleTimeFast" INT 0 50000;
BA_DEF_  "BaudRate" FLOAT 1000 1000000;
BA_DEF_ BO_  "GenMsgSendType" ENUM  "cyclic","spontaneous","cyclicIfActive","spontaneousWithDelay","cyclicAndSpontaneous","cyclicAndSpontaneousWithDelay","not_used","not_used","not_used","cyclicWithRepeatOnDemand";
BA_DEF_ BO_  "GenMsgCycleTime" FLOAT 0 300000;
BA_DEF_ BO_  "GenMsgStartDelayTime" FLOAT 0 300000;
BA_DEF_ BO_  "GenMsgDelayTime" FLOAT 0 300000;
BA_DEF_ SG_  "GenSigSendType" ENUM  "Cyclic","OnWrite","OnWriteWithRepetition","OnChange","OnChangeWithRepetition","IfActive","IfActiveWithRepetition","NoSigSendType";
BA_DEF_ SG_  "GenSigStartValue" FLOAT -1E+019 1E+019;
BA_DEF_ SG_  "SystemSignalLongSymbol" STRING ;
BA_DEF_DEF_  "GenSigDataID" "";
BA_DEF_DEF_  "GenSigFuncType" "NoFunction";
BA_DEF_DEF_  "NmAsrNodeIdentifier" 60;
BA_DEF_DEF_  "NmAsrBaseAddress" 1280;
BA_DEF_DEF_  "NmAsrMessageCount" 50;
BA_DEF_DEF_  "DBName" "";
BA_DEF_DEF_  "SigGroup" "";
BA_DEF_DEF_  "NodeLayerModules" "CANoeILNLSPA.dll";
BA_DEF_DEF_  "GenMsgILSupport" "Yes";
BA_DEF_DEF_  "GenMsgCycleTimeFast" 2;
BA_DEF_DEF_  "BaudRate" 1000;
BA_DEF_DEF_  "GenMsgSendType" "spontaneous";
BA_DEF_DEF_  "GenMsgCycleTime" 0;
BA_DEF_DEF_  "GenMsgStartDelayTime" 0;
BA_DEF_DEF_  "GenMsgDelayTime" 0;
BA_DEF_DEF_  "GenSigSendType" "Cyclic";
BA_DEF_DEF_  "GenSigStartValue" 0;
BA_DEF_DEF_  "SystemSignalLongSymbol" "";
BA_ "NmAsrMessageCount" 64;
BA_ "BaudRate" 500000;
BA_ "DBName" "BodyCANhs";
BA_ "NmAsrNodeIdentifier" BU_ CCM 2;
BA_ "NodeLayerModules" BU_ CCM "CANoeILNLSPA.dll,AsrNM33.dll";
BA_ "NmAsrNodeIdentifier" BU_ CEM 1;
BA_ "NodeLayerModules" BU_ CEM "CANoeILNLSPA.dll,AsrNM33.dll";
BA_ "NmAsrNodeIdentifier" BU_ DDM 3;
BA_ "NodeLayerModules" BU_ DDM "CANoeILNLSPA.dll,AsrNM33.dll";
BA_ "NmAsrNodeIdentifier" BU_ PDM 4;
BA_ "NodeLayerModules" BU_ PDM "CANoeILNLSPA.dll,AsrNM33.dll";
BA_ "NmAsrNodeIdentifier" BU_ POT 7;
BA_ "NodeLayerModules" BU_ POT "CANoeILNLSPA.dll,AsrNM33.dll";
BA_ "NmAsrNodeIdentifier" BU_ PSMD 5;
BA_ "NodeLayerModules" BU_ PSMD "CANoeILNLSPA.dll,AsrNM33.dll";
BA_ "NmAsrNodeIdentifier" BU_ PSMP 6;
BA_ "NodeLayerModules" BU_ PSMP "CANoeILNLSPA.dll,AsrNM33.dll";
BA_ "NmAsrNodeIdentifier" BU_ TRM 10;
BA_ "NodeLayerModules" BU_ TRM "CANoeILNLSPA.dll,AsrNM33.dll";
BA_ "NmAsrNodeIdentifier" BU_ VCM 9;
BA_ "NodeLayerModules" BU_ VCM "CANoeILNLSPA.dll,AsrNM33.dll";
BA_ "GenMsgDelayTime" BO_ 1456 1000;
BA_ "GenMsgCycleTime" BO_ 80 25;
BA_ "GenMsgSendType" BO_ 80 0;
BA_ "GenMsgCycleTime" BO_ 96 30;
BA_ "GenMsgSendType" BO_ 96 0;
BA_ "GenMsgCycleTime" BO_ 336 200;
BA_ "GenMsgSendType" BO_ 336 0;
BA_ "GenMsgCycleTime" BO_ 368 200;
BA_ "GenMsgSendType" BO_ 368 0;
BA_ "GenMsgCycleTime" BO_ 448 400;
BA_ "GenMsgSendType" BO_ 448 0;
BA_ "GenMsgCycleTime" BO_ 272 100;
BA_ "GenMsgSendType" BO_ 272 0;
BA_ "GenMsgCycleTime" BO_ 576 1000;
BA_ "GenMsgSendType" BO_ 576 0;
BA_ "GenMsgCycleTime" BO_ 597 400;
BA_ "GenMsgSendType" BO_ 597 0;
BA_ "GenMsgILSupport" BO_ 1282 0;
BA_ "GenMsgDelayTime" BO_ 1282 20;
BA_ "GenMsgDelayTime" BO_ 1553 5;
BA_ "GenMsgDelayTime" BO_ 1409 5;
BA_ "GenMsgDelayTime" BO_ 1410 5;
BA_ "GenMsgDelayTime" BO_ 1411 5;
BA_ "GenMsgDelayTime" BO_ 1412 5;
BA_ "GenMsgCycleTime" BO_ 800 50;
BA_ "GenMsgSendType" BO_ 800 0;
BA_ "GenMsgCycleTime" BO_ 1122 1000;
BA_ "GenMsgSendType" BO_ 1122 0;
BA_ "GenMsgDelayTime" BO_ 1449 1000;
BA_ "GenMsgCycleTime" BO_ 32 10;
BA_ "GenMsgSendType" BO_ 32 0;
BA_ "GenMsgCycleTime" BO_ 64 15;
BA_ "GenMsgSendType" BO_ 64 0;
BA_ "GenMsgDelayTime" BO_ 243 10;
BA_ "GenMsgDelayTime" BO_ 245 10;
BA_ "GenMsgCycleTime" BO_ 176 50;
BA_ "GenMsgSendType" BO_ 176 0;
BA_ "GenMsgCycleTime" BO_ 288 100;
BA_ "GenMsgSendType" BO_ 288 0;
BA_ "GenMsgCycleTime" BO_ 224 60;
BA_ "GenMsgSendType" BO_ 224 0;
BA_ "GenMsgCycleTime" BO_ 240 80;
BA_ "GenMsgSendType" BO_ 240 0;
BA_ "GenMsgCycleTime" BO_ 256 100;
BA_ "GenMsgSendType" BO_ 256 0;
BA_ "GenMsgCycleTime" BO_ 320 200;
BA_ "GenMsgSendType" BO_ 320 0;
BA_ "GenMsgCycleTime" BO_ 384 200;
BA_ "GenMsgSendType" BO_ 384 0;
BA_ "GenMsgCycleTime" BO_ 400 200;
BA_ "GenMsgSendType" BO_ 400 0;
BA_ "GenMsgCycleTime" BO_ 432 400;
BA_ "GenMsgSendType" BO_ 432 0;
BA_ "GenMsgCycleTime" BO_ 496 400;
BA_ "GenMsgSendType" BO_ 496 0;
BA_ "GenSigSendType" SG_ 1456 EndOfLineSigEquipInp 3;
BA_ "GenSigSendType" SG_ 1456 EndOfLineSigEquipInp1 3;
BA_ "GenSigStartValue" SG_ 80 ClimaTiOfEnd_UB 1;
BA_ "GenSigStartValue" SG_ 80 ClimaWarn_UB 1;
BA_ "GenSigStartValue" SG_ 80 HvacCoolgEnaFrnt_UB 1;
BA_ "SigGroup" SG_ 80 HvacEvaprTFrnt "HvacEvaprTFrntGroup";
BA_ "GenSigStartValue" SG_ 80 HvacEvaprTFrntGroup_UB 1;
BA_ "SigGroup" SG_ 80 HvacEvaprTFrntQf "HvacEvaprTFrntGroup";
BA_ "GenSigStartValue" SG_ 80 HvacRecircAct_UB 1;
BA_ "GenSigStartValue" SG_ 96 ClimaActv_UB 1;
BA_ "GenSigStartValue" SG_ 96 CmptmtAirTEstimdAtRowFirstLoResl 600;
BA_ "GenSigStartValue" SG_ 96 CmptmtAirTEstimdAtRowFirstL_0000 1;
BA_ "SystemSignalLongSymbol" SG_ 96 CmptmtAirTEstimdAtRowFirstL_0000 "CmptmtAirTEstimdAtRowFirstLoResl_UB";
BA_ "GenSigStartValue" SG_ 96 EngSpdIncIdleForClima_UB 1;
BA_ "GenSigStartValue" SG_ 96 HeatrIntkCooltTEstimd 40;
BA_ "GenSigStartValue" SG_ 96 HeatrIntkCooltTEstimd_UB 1;
BA_ "GenSigStartValue" SG_ 96 HvacAirMFlowEstimd_UB 1;
BA_ "GenSigStartValue" SG_ 96 HvEgyDesForClima_UB 1;
BA_ "GenSigStartValue" SG_ 96 TInCooltAtStrtOfClima 40;
BA_ "GenSigStartValue" SG_ 96 TInCooltAtStrtOfClima_UB 1;
BA_ "GenSigStartValue" SG_ 336 AmbTEstimd_UB 1;
BA_ "SigGroup" SG_ 336 AmbTEstimdAmbTEstimd "AmbTEstimd";
BA_ "GenSigStartValue" SG_ 336 AmbTEstimdAmbTEstimd 700;
BA_ "SigGroup" SG_ 336 AmbTEstimdAmbTEstimdQf "AmbTEstimd";
BA_ "GenSigStartValue" SG_ 336 ClimaSts_UB 1;
BA_ "GenSigStartValue" SG_ 336 DefrstReq_UB 1;
BA_ "GenSigStartValue" SG_ 336 FuHeatrFuCns1_UB 1;
BA_ "GenSigStartValue" SG_ 336 HvHeatgPwrCritDes_UB 1;
BA_ "SigGroup" SG_ 336 MirrDefrstReq "DefrstReq";
BA_ "GenSigStartValue" SG_ 336 PwrEstimdAtStbForClima_UB 1;
BA_ "SigGroup" SG_ 336 WinDefrstFrntReq "DefrstReq";
BA_ "SigGroup" SG_ 336 WinDefrstReReq "DefrstReq";
BA_ "GenSigStartValue" SG_ 336 WindIceDetdFrnt_UB 1;
BA_ "GenSigStartValue" SG_ 336 WindIceDetdRe_UB 1;
BA_ "GenSigStartValue" SG_ 368 CooltFlowFromWtrPmpAux_UB 1;
BA_ "GenSigStartValue" SG_ 368 HeatrCooltT 40;
BA_ "GenSigStartValue" SG_ 368 HeatrCooltT_UB 1;
BA_ "GenSigStartValue" SG_ 368 HvacEvaprTSpFrnt 50;
BA_ "GenSigStartValue" SG_ 368 HvacEvaprTSpFrnt_UB 1;
BA_ "GenSigStartValue" SG_ 368 HvHeatgPwrCns_UB 1;
BA_ "GenSigStartValue" SG_ 368 HvHeatgPwrNormDes_UB 1;
BA_ "GenSigStartValue" SG_ 368 RlyCmftForClimaReq_UB 1;
BA_ "GenSigStartValue" SG_ 368 UBoostReqByClima_UB 1;
BA_ "GenSigStartValue" SG_ 368 WindDewTUppr_UB 1;
BA_ "SigGroup" SG_ 368 WindDewTUpprDewT "WindDewTUppr";
BA_ "GenSigStartValue" SG_ 368 WindDewTUpprDewT 700;
BA_ "SigGroup" SG_ 368 WindDewTUpprDewTQf "WindDewTUppr";
BA_ "GenSigStartValue" SG_ 448 EngHeatgReq_UB 1;
BA_ "GenSigStartValue" SG_ 448 EvaprVlvReSts_UB 1;
BA_ "GenSigStartValue" SG_ 448 EvaprVlvReStsExtd_UB 1;
BA_ "SigGroup" SG_ 448 EvaprVlvReStsExtdDiagcStsForCirc "EvaprVlvReStsExtd";
BA_ "SystemSignalLongSymbol" SG_ 448 EvaprVlvReStsExtdDiagcStsForCirc "EvaprVlvReStsExtdDiagcStsForCircOpen";
BA_ "SigGroup" SG_ 448 EvaprVlvReStsExtdDiagcStsForShoT "EvaprVlvReStsExtd";
BA_ "SystemSignalLongSymbol" SG_ 448 EvaprVlvReStsExtdDiagcStsForShoT "EvaprVlvReStsExtdDiagcStsForShoToBatt";
BA_ "SigGroup" SG_ 448 EvaprVlvReStsExtdDiagcStsFo_0000 "EvaprVlvReStsExtd";
BA_ "SystemSignalLongSymbol" SG_ 448 EvaprVlvReStsExtdDiagcStsFo_0000 "EvaprVlvReStsExtdDiagcStsForShoToGnd";
BA_ "GenSigStartValue" SG_ 448 FuTankPRelsForFuHeatrReq_UB 1;
BA_ "GenSigStartValue" SG_ 448 HvacAirMFlowReEstimd_UB 1;
BA_ "GenSigStartValue" SG_ 448 HvacCooltFlowReq_UB 1;
BA_ "GenSigStartValue" SG_ 448 HvacCooltVlvReqExt_UB 1;
BA_ "GenSigStartValue" SG_ 448 HvacCooltVlvSts_UB 1;
BA_ "GenSigStartValue" SG_ 448 HvacHeatrPwrCns_UB 1;
BA_ "GenSigStartValue" SG_ 448 WindTGroup_UB 1;
BA_ "SigGroup" SG_ 448 WindTWindT "WindTGroup";
BA_ "GenSigStartValue" SG_ 448 WindTWindT 700;
BA_ "SigGroup" SG_ 448 WindTWindTQf "WindTGroup";
BA_ "GenSigStartValue" SG_ 272 ClimaPwrCns_UB 1;
BA_ "GenSigStartValue" SG_ 272 ClimaPwrCritDes_UB 1;
BA_ "GenSigStartValue" SG_ 272 ClimaPwrNormDes_UB 1;
BA_ "GenSigStartValue" SG_ 272 EngRunngReqByClima_UB 1;
BA_ "GenSigStartValue" SG_ 272 HvacCoolgEnaRe_UB 1;
BA_ "GenSigStartValue" SG_ 272 LvlOfClimaCmft_UB 1;
BA_ "GenSigStartValue" SG_ 272 PwrChrgDetdForPrkgHeatrElec_UB 1;
BA_ "GenSigStartValue" SG_ 272 SeatHeatgAutCdn_UB 1;
BA_ "GenSigStartValue" SG_ 272 SteerWhlHeatgAllwd_UB 1;
BA_ "GenSigStartValue" SG_ 576 ClimaStrtTi_UB 1;
BA_ "GenSigStartValue" SG_ 576 ClimaTmrSts_UB 1;
BA_ "GenSigStartValue" SG_ 576 CoolgStsForDisp_UB 1;
BA_ "GenSigStartValue" SG_ 576 CustClimaOvrdNotifForHmiCpt_UB 1;
BA_ "GenSigStartValue" SG_ 576 EgyDesForClima_UB 1;
BA_ "GenSigStartValue" SG_ 576 FuHeatrActv_UB 1;
BA_ "GenSigStartValue" SG_ 576 FuHeatrFuCnsDurgCyc1_UB 1;
BA_ "GenSigStartValue" SG_ 576 PostDrvgClimaAvl_UB 1;
BA_ "GenSigStartValue" SG_ 576 RlyCrashForClimaReq_UB 1;
BA_ "GenSigStartValue" SG_ 576 SteerWhlHeatgDurgClima_UB 1;
BA_ "GenSigStartValue" SG_ 597 ClimaActvAlrmSts_UB 1;
BA_ "GenSigStartValue" SG_ 597 ClngActv_UB 1;
BA_ "GenSigStartValue" SG_ 597 CmptmtAirTEstimdExtd_UB 1;
BA_ "SigGroup" SG_ 597 CmptmtAirTEstimdExtdComptmtT "CmptmtAirTEstimdExtd";
BA_ "GenSigStartValue" SG_ 597 CmptmtAirTEstimdExtdComptmtT 600;
BA_ "SigGroup" SG_ 597 CmptmtAirTEstimdExtdQlyFlg "CmptmtAirTEstimdExtd";
BA_ "GenSigStartValue" SG_ 597 CooltVlvOutpTyp_UB 1;
BA_ "GenSigStartValue" SG_ 597 HeatgForHvBattSts_UB 1;
BA_ "GenSigStartValue" SG_ 597 PreClngNotif_UB 1;
BA_ "GenSigStartValue" SG_ 800 VFCVectorCCM_UB 1;
BA_ "SigGroup" SG_ 800 VFCVectorCCMGrp1 "VFCVectorCCM";
BA_ "SigGroup" SG_ 800 VFCVectorCCMGrp2 "VFCVectorCCM";
BA_ "SigGroup" SG_ 800 VFCVectorCCMGrp3 "VFCVectorCCM";
BA_ "GenSigStartValue" SG_ 1122 HmiCmptmtAirDistbnFrntM1 7;
BA_ "GenSigStartValue" SG_ 1122 HmiCmptmtCoolgReqM1 1;
BA_ "GenSigStartValue" SG_ 1122 HmiCmptmtTSpForRowFirstLeM1 14;
BA_ "GenSigStartValue" SG_ 1122 HmiCmptmtTSpForRowFirstRiM1 14;
BA_ "GenSigStartValue" SG_ 1122 HmiCmptmtTSpForRowSecLeM1 14;
BA_ "GenSigStartValue" SG_ 1122 HmiCmptmtTSpForRowSecRiM1 14;
BA_ "GenSigStartValue" SG_ 1122 HmiHvacFanLvlFrntM1 11;
BA_ "SigGroup" SG_ 1449 EndOfLineSigOverByte0 "EndOfLineSigOver";
BA_ "GenSigSendType" SG_ 1449 EndOfLineSigOverByte0 3;
BA_ "SigGroup" SG_ 1449 EndOfLineSigOverByte1 "EndOfLineSigOver";
BA_ "GenSigSendType" SG_ 1449 EndOfLineSigOverByte1 3;
BA_ "SigGroup" SG_ 1449 EndOfLineSigOverByte2 "EndOfLineSigOver";
BA_ "GenSigSendType" SG_ 1449 EndOfLineSigOverByte2 3;
BA_ "SigGroup" SG_ 1449 EndOfLineSigOverByte3 "EndOfLineSigOver";
BA_ "GenSigSendType" SG_ 1449 EndOfLineSigOverByte3 3;
BA_ "SigGroup" SG_ 1449 EndOfLineSigOverByte4 "EndOfLineSigOver";
BA_ "GenSigSendType" SG_ 1449 EndOfLineSigOverByte4 3;
BA_ "SigGroup" SG_ 1449 EndOfLineSigOverByte5 "EndOfLineSigOver";
BA_ "GenSigSendType" SG_ 1449 EndOfLineSigOverByte5 3;
BA_ "SigGroup" SG_ 1449 EndOfLineSigOverByte6 "EndOfLineSigOver";
BA_ "GenSigSendType" SG_ 1449 EndOfLineSigOverByte6 3;
BA_ "SigGroup" SG_ 1449 EndOfLineSigOverByte7 "EndOfLineSigOver";
BA_ "GenSigSendType" SG_ 1449 EndOfLineSigOverByte7 3;
BA_ "GenSigStartValue" SG_ 32 ActvnOfHndlDoorLi_UB 1;
BA_ "GenSigStartValue" SG_ 32 ActvnOfTrlrBrkLi_UB 1;
BA_ "GenSigStartValue" SG_ 32 DoorDrvrIntrSwtLedLockgReCmd_UB 1;
BA_ "GenSigStartValue" SG_ 32 DoorDrvrLockCmd_UB 1;
BA_ "GenSigStartValue" SG_ 32 DoorDrvrLockReCmd_UB 1;
BA_ "GenSigStartValue" SG_ 32 DoorPassIntrSwtLedLockgReCmd_UB 1;
BA_ "GenSigStartValue" SG_ 32 DoorPassLockCmd_UB 1;
BA_ "GenSigStartValue" SG_ 32 DoorPassLockReCmd_UB 1;
BA_ "SigGroup" SG_ 32 EveMemPosn "LoadAndStoreReq";
BA_ "SigGroup" SG_ 32 HndlDoorLiDrvr "ActvnOfHndlDoorLi";
BA_ "SigGroup" SG_ 32 HndlDoorLiDrvrRe "ActvnOfHndlDoorLi";
BA_ "SigGroup" SG_ 32 HndlDoorLiPass "ActvnOfHndlDoorLi";
BA_ "SigGroup" SG_ 32 HndlDoorLiPassRe "ActvnOfHndlDoorLi";
BA_ "GenSigStartValue" SG_ 32 HvCooltHeatrEnad_UB 1;
BA_ "GenSigStartValue" SG_ 32 IndcrTurnCmd1WdCmd_UB 1;
BA_ "SigGroup" SG_ 32 IndcrTurnCmd1WdHzrdTelltl "IndcrTurnCmd1WdCmd";
BA_ "GenSigSendType" SG_ 32 IndcrTurnCmd1WdHzrdTelltl 1;
BA_ "SigGroup" SG_ 32 IndcrTurnCmd1WdIndcrTrig "IndcrTurnCmd1WdCmd";
BA_ "GenSigSendType" SG_ 32 IndcrTurnCmd1WdIndcrTrig 1;
BA_ "GenSigStartValue" SG_ 32 IndcrTurnSts1WdSts_UB 1;
BA_ "SigGroup" SG_ 32 IntrLiActvn1 "IntrLiCmdGroup";
BA_ "GenSigStartValue" SG_ 32 IntrLiCmdGroup_UB 1;
BA_ "GenSigStartValue" SG_ 32 IntrLiDmdOff_UB 1;
BA_ "SigGroup" SG_ 32 IntrLiRoofDim "IntrLiCmdGroup";
BA_ "SigGroup" SG_ 32 IntrLiRoofDmdOff "IntrLiCmdGroup";
BA_ "GenSigStartValue" SG_ 32 LoadAndStoreReq_UB 1;
BA_ "SigGroup" SG_ 32 LoadAndStoreReqIdPen "LoadAndStoreReq";
BA_ "SigGroup" SG_ 32 LoadAndStoreReqInOutEasy "LoadAndStoreReq";
BA_ "SigGroup" SG_ 32 MemPosn "LoadAndStoreReq";
BA_ "GenSigStartValue" SG_ 64 ClimaRqrd_UB 1;
BA_ "GenSigStartValue" SG_ 64 CllsnWarnIndcnLe_UB 1;
BA_ "GenSigStartValue" SG_ 64 CllsnWarnIndcnRi_UB 1;
BA_ "GenSigStartValue" SG_ 64 DoorDrvrIntrSwtLedLockgCmd_UB 1;
BA_ "GenSigStartValue" SG_ 64 DoorDrvrReSts_UB 1;
BA_ "GenSigStartValue" SG_ 64 DoorDrvrSts_UB 1;
BA_ "GenSigStartValue" SG_ 64 DoorPassIntrSwtLedLockgCmd_UB 1;
BA_ "GenSigStartValue" SG_ 64 GlbWinCmd_UB 1;
BA_ "GenSigStartValue" SG_ 64 LcmaIndcnLe_UB 1;
BA_ "GenSigStartValue" SG_ 64 LcmaIndcnRi_UB 1;
BA_ "GenSigStartValue" SG_ 64 PassLoadAndStoreReq_UB 1;
BA_ "SigGroup" SG_ 64 PassLoadAndStoreReqErgoPosn "PassLoadAndStoreReq";
BA_ "SigGroup" SG_ 64 PassLoadAndStoreReqErgoSetgEve "PassLoadAndStoreReq";
BA_ "GenSigStartValue" SG_ 64 SaveSetgToMemPrmnt 2;
BA_ "GenSigStartValue" SG_ 64 SaveSetgToMemPrmnt_UB 1;
BA_ "GenSigStartValue" SG_ 64 TrNoKeyPrsntAcoustReq_UB 1;
BA_ "GenSigStartValue" SG_ 64 TrOpenerReq_UB 1;
BA_ "SigGroup" SG_ 64 TrOpenerReqTrOpenerReq "TrOpenerReq";
BA_ "SigGroup" SG_ 64 TrOpenerReqTrOpenerTrigSrc "TrOpenerReq";
BA_ "GenSigStartValue" SG_ 64 TwliBriSts_UB 1;
BA_ "GenSigDataID" SG_ 64 VehMtnStChks "0x36";
BA_ "GenSigFuncType" SG_ 64 VehMtnStChks 15;
BA_ "SigGroup" SG_ 64 VehMtnStChks "VehMtnStSafeGroup";
BA_ "GenSigFuncType" SG_ 64 VehMtnStCntr 16;
BA_ "SigGroup" SG_ 64 VehMtnStCntr "VehMtnStSafeGroup";
BA_ "SigGroup" SG_ 64 VehMtnStSafe "VehMtnStSafeGroup";
BA_ "GenSigStartValue" SG_ 64 VehMtnStSafeGroup_UB 1;
BA_ "GenSigSendType" SG_ 243 CrashSts2 3;
BA_ "GenSigStartValue" SG_ 243 CrashSts2 1;
BA_ "GenSigSendType" SG_ 243 CrashSts2_UB 3;
BA_ "GenSigStartValue" SG_ 243 CrashSts2_UB 1;
BA_ "GenSigDataID" SG_ 245 RecOfImpctSafeChks "0x18";
BA_ "GenSigFuncType" SG_ 245 RecOfImpctSafeChks 15;
BA_ "SigGroup" SG_ 245 RecOfImpctSafeChks "RecOfImpctSafe";
BA_ "GenSigSendType" SG_ 245 RecOfImpctSafeChks 3;
BA_ "GenSigStartValue" SG_ 245 RecOfImpctSafeChks 255;
BA_ "GenSigFuncType" SG_ 245 RecOfImpctSafeCntr 16;
BA_ "SigGroup" SG_ 245 RecOfImpctSafeCntr "RecOfImpctSafe";
BA_ "GenSigSendType" SG_ 245 RecOfImpctSafeCntr 3;
BA_ "SigGroup" SG_ 245 RecOfImpctSafeCrashFrnt "RecOfImpctSafe";
BA_ "GenSigSendType" SG_ 245 RecOfImpctSafeCrashFrnt 3;
BA_ "GenSigStartValue" SG_ 245 RecOfImpctSafeCrashFrnt 1;
BA_ "SigGroup" SG_ 245 RecOfImpctSafeCrashLargeAnimal "RecOfImpctSafe";
BA_ "GenSigSendType" SG_ 245 RecOfImpctSafeCrashLargeAnimal 3;
BA_ "GenSigStartValue" SG_ 245 RecOfImpctSafeCrashLargeAnimal 1;
BA_ "SigGroup" SG_ 245 RecOfImpctSafeCrashOffroadA "RecOfImpctSafe";
BA_ "GenSigSendType" SG_ 245 RecOfImpctSafeCrashOffroadA 3;
BA_ "GenSigStartValue" SG_ 245 RecOfImpctSafeCrashOffroadA 1;
BA_ "SigGroup" SG_ 245 RecOfImpctSafeCrashOffroadD "RecOfImpctSafe";
BA_ "GenSigSendType" SG_ 245 RecOfImpctSafeCrashOffroadD 3;
BA_ "GenSigStartValue" SG_ 245 RecOfImpctSafeCrashOffroadD 1;
BA_ "SigGroup" SG_ 245 RecOfImpctSafeCrashOffroadRT "RecOfImpctSafe";
BA_ "GenSigSendType" SG_ 245 RecOfImpctSafeCrashOffroadRT 3;
BA_ "GenSigStartValue" SG_ 245 RecOfImpctSafeCrashOffroadRT 1;
BA_ "SigGroup" SG_ 245 RecOfImpctSafeCrashOffroadRTseve "RecOfImpctSafe";
BA_ "GenSigSendType" SG_ 245 RecOfImpctSafeCrashOffroadRTseve 3;
BA_ "GenSigStartValue" SG_ 245 RecOfImpctSafeCrashOffroadRTseve 1;
BA_ "SystemSignalLongSymbol" SG_ 245 RecOfImpctSafeCrashOffroadRTseve "RecOfImpctSafeCrashOffroadRTsevere";
BA_ "SigGroup" SG_ 245 RecOfImpctSafeCrashOz "RecOfImpctSafe";
BA_ "GenSigSendType" SG_ 245 RecOfImpctSafeCrashOz 3;
BA_ "GenSigStartValue" SG_ 245 RecOfImpctSafeCrashOz 1;
BA_ "SigGroup" SG_ 245 RecOfImpctSafeCrashPed "RecOfImpctSafe";
BA_ "GenSigSendType" SG_ 245 RecOfImpctSafeCrashPed 3;
BA_ "GenSigStartValue" SG_ 245 RecOfImpctSafeCrashPed 1;
BA_ "SigGroup" SG_ 245 RecOfImpctSafeCrashRe "RecOfImpctSafe";
BA_ "GenSigSendType" SG_ 245 RecOfImpctSafeCrashRe 3;
BA_ "GenSigStartValue" SG_ 245 RecOfImpctSafeCrashRe 1;
BA_ "SigGroup" SG_ 245 RecOfImpctSafeCrashRollovr "RecOfImpctSafe";
BA_ "GenSigSendType" SG_ 245 RecOfImpctSafeCrashRollovr 3;
BA_ "GenSigStartValue" SG_ 245 RecOfImpctSafeCrashRollovr 1;
BA_ "SigGroup" SG_ 245 RecOfImpctSafeCrashSideLe "RecOfImpctSafe";
BA_ "GenSigSendType" SG_ 245 RecOfImpctSafeCrashSideLe 3;
BA_ "GenSigStartValue" SG_ 245 RecOfImpctSafeCrashSideLe 1;
BA_ "SigGroup" SG_ 245 RecOfImpctSafeCrashSideRi "RecOfImpctSafe";
BA_ "GenSigSendType" SG_ 245 RecOfImpctSafeCrashSideRi 3;
BA_ "GenSigStartValue" SG_ 245 RecOfImpctSafeCrashSideRi 1;
BA_ "SigGroup" SG_ 245 RecOfImpctSafeCrashState "RecOfImpctSafe";
BA_ "GenSigSendType" SG_ 245 RecOfImpctSafeCrashState 3;
BA_ "SigGroup" SG_ 245 RecOfImpctSafeImpctDvx "RecOfImpctSafe";
BA_ "GenSigSendType" SG_ 245 RecOfImpctSafeImpctDvx 3;
BA_ "SigGroup" SG_ 245 RecOfImpctSafeImpctDvy "RecOfImpctSafe";
BA_ "GenSigSendType" SG_ 245 RecOfImpctSafeImpctDvy 3;
BA_ "SigGroup" SG_ 245 RecOfImpctSafeImpctRollAg "RecOfImpctSafe";
BA_ "GenSigSendType" SG_ 245 RecOfImpctSafeImpctRollAg 3;
BA_ "SigGroup" SG_ 245 RecOfImpctSafeVehOri "RecOfImpctSafe";
BA_ "GenSigSendType" SG_ 245 RecOfImpctSafeVehOri 3;
BA_ "GenSigStartValue" SG_ 176 BltLockStAtDrvr_UB 1;
BA_ "SigGroup" SG_ 176 BltLockStAtDrvrForBltLockSt1 "BltLockStAtDrvr";
BA_ "GenSigStartValue" SG_ 176 BltLockStAtDrvrForBltLockSt1 1;
BA_ "SigGroup" SG_ 176 BltLockStAtDrvrForDevErrSts2 "BltLockStAtDrvr";
BA_ "GenSigStartValue" SG_ 176 BltLockStAtPass_UB 1;
BA_ "SigGroup" SG_ 176 BltLockStAtPassForBltLockSt1 "BltLockStAtPass";
BA_ "GenSigStartValue" SG_ 176 BltLockStAtPassForBltLockSt1 1;
BA_ "SigGroup" SG_ 176 BltLockStAtPassForBltLockSts "BltLockStAtPass";
BA_ "GenSigStartValue" SG_ 176 BltLockStAtRowSecLe_UB 1;
BA_ "SigGroup" SG_ 176 BltLockStAtRowSecLeForBltLockEqu "BltLockStAtRowSecLe";
BA_ "GenSigStartValue" SG_ 176 BltLockStAtRowSecLeForBltLockEqu 1;
BA_ "SystemSignalLongSymbol" SG_ 176 BltLockStAtRowSecLeForBltLockEqu "BltLockStAtRowSecLeForBltLockEquid";
BA_ "SigGroup" SG_ 176 BltLockStAtRowSecLeForBltLockSt1 "BltLockStAtRowSecLe";
BA_ "SigGroup" SG_ 176 BltLockStAtRowSecLeForBltLockSts "BltLockStAtRowSecLe";
BA_ "GenSigStartValue" SG_ 176 BltLockStAtRowSecLeForBltLockSts 1;
BA_ "GenSigStartValue" SG_ 176 BltLockStAtRowSecMid_UB 1;
BA_ "SigGroup" SG_ 176 BltLockStAtRowSecMidForBltLockEq "BltLockStAtRowSecMid";
BA_ "GenSigStartValue" SG_ 176 BltLockStAtRowSecMidForBltLockEq 1;
BA_ "SystemSignalLongSymbol" SG_ 176 BltLockStAtRowSecMidForBltLockEq "BltLockStAtRowSecMidForBltLockEquid";
BA_ "SigGroup" SG_ 176 BltLockStAtRowSecMidForBltLockSt "BltLockStAtRowSecMid";
BA_ "SystemSignalLongSymbol" SG_ 176 BltLockStAtRowSecMidForBltLockSt "BltLockStAtRowSecMidForBltLockSt1";
BA_ "SigGroup" SG_ 176 BltLockStAtRowSecMidForBltL_0000 "BltLockStAtRowSecMid";
BA_ "GenSigStartValue" SG_ 176 BltLockStAtRowSecMidForBltL_0000 1;
BA_ "SystemSignalLongSymbol" SG_ 176 BltLockStAtRowSecMidForBltL_0000 "BltLockStAtRowSecMidForBltLockSts";
BA_ "GenSigStartValue" SG_ 176 BltLockStAtRowSecRi_UB 1;
BA_ "SigGroup" SG_ 176 BltLockStAtRowSecRiForBltLockEqu "BltLockStAtRowSecRi";
BA_ "GenSigStartValue" SG_ 176 BltLockStAtRowSecRiForBltLockEqu 1;
BA_ "SystemSignalLongSymbol" SG_ 176 BltLockStAtRowSecRiForBltLockEqu "BltLockStAtRowSecRiForBltLockEquid";
BA_ "SigGroup" SG_ 176 BltLockStAtRowSecRiForBltLockSt1 "BltLockStAtRowSecRi";
BA_ "SigGroup" SG_ 176 BltLockStAtRowSecRiForBltLockSts "BltLockStAtRowSecRi";
BA_ "GenSigStartValue" SG_ 176 BltLockStAtRowSecRiForBltLockSts 1;
BA_ "GenSigStartValue" SG_ 176 BltLockStAtRowThrdLe_UB 1;
BA_ "SigGroup" SG_ 176 BltLockStAtRowThrdLeForBltLockEq "BltLockStAtRowThrdLe";
BA_ "GenSigStartValue" SG_ 176 BltLockStAtRowThrdLeForBltLockEq 1;
BA_ "SystemSignalLongSymbol" SG_ 176 BltLockStAtRowThrdLeForBltLockEq "BltLockStAtRowThrdLeForBltLockEquid";
BA_ "SigGroup" SG_ 176 BltLockStAtRowThrdLeForBltLockSt "BltLockStAtRowThrdLe";
BA_ "SystemSignalLongSymbol" SG_ 176 BltLockStAtRowThrdLeForBltLockSt "BltLockStAtRowThrdLeForBltLockSt1";
BA_ "SigGroup" SG_ 176 BltLockStAtRowThrdLeForBltL_0000 "BltLockStAtRowThrdLe";
BA_ "GenSigStartValue" SG_ 176 BltLockStAtRowThrdLeForBltL_0000 1;
BA_ "SystemSignalLongSymbol" SG_ 176 BltLockStAtRowThrdLeForBltL_0000 "BltLockStAtRowThrdLeForBltLockSts";
BA_ "GenSigStartValue" SG_ 176 BltLockStAtRowThrdRi_UB 1;
BA_ "SigGroup" SG_ 176 BltLockStAtRowThrdRiForBltLockEq "BltLockStAtRowThrdRi";
BA_ "GenSigStartValue" SG_ 176 BltLockStAtRowThrdRiForBltLockEq 1;
BA_ "SystemSignalLongSymbol" SG_ 176 BltLockStAtRowThrdRiForBltLockEq "BltLockStAtRowThrdRiForBltLockEquid";
BA_ "SigGroup" SG_ 176 BltLockStAtRowThrdRiForBltLockSt "BltLockStAtRowThrdRi";
BA_ "SystemSignalLongSymbol" SG_ 176 BltLockStAtRowThrdRiForBltLockSt "BltLockStAtRowThrdRiForBltLockSt1";
BA_ "SigGroup" SG_ 176 BltLockStAtRowThrdRiForBltL_0000 "BltLockStAtRowThrdRi";
BA_ "GenSigStartValue" SG_ 176 BltLockStAtRowThrdRiForBltL_0000 1;
BA_ "SystemSignalLongSymbol" SG_ 176 BltLockStAtRowThrdRiForBltL_0000 "BltLockStAtRowThrdRiForBltLockSts";
BA_ "GenSigStartValue" SG_ 176 BrkFldLvl_UB 1;
BA_ "GenSigStartValue" SG_ 176 ChrgnTyp_UB 1;
BA_ "GenSigStartValue" SG_ 176 EngCooltLvl_UB 1;
BA_ "GenSigStartValue" SG_ 176 ErsStrtApplSts_UB 1;
BA_ "GenSigStartValue" SG_ 176 HvEgyCnsAllwdForClima_UB 1;
BA_ "SigGroup" SG_ 288 ImobDataRemMgrChk0 "ImobRemMgrChk";
BA_ "SigGroup" SG_ 288 ImobDataRemMgrChk1 "ImobRemMgrChk";
BA_ "SigGroup" SG_ 288 ImobDataRemMgrChk2 "ImobRemMgrChk";
BA_ "SigGroup" SG_ 288 ImobDataRemMgrChk3 "ImobRemMgrChk";
BA_ "SigGroup" SG_ 288 ImobDataRemMgrChk4 "ImobRemMgrChk";
BA_ "GenSigStartValue" SG_ 288 ImobRemMgrChk_UB 1;
BA_ "SigGroup" SG_ 288 ImobRemMgrChkSts "ImobRemMgrChk";
BA_ "SigGroup" SG_ 288 ImobVehRemMgrSts "ImobVehRemMgrSts1";
BA_ "GenSigStartValue" SG_ 288 ImobVehRemMgrSts1_UB 1;
BA_ "GenSigStartValue" SG_ 288 ModOnLiInten 1;
BA_ "GenSigStartValue" SG_ 288 ModOnLiInten_UB 1;
BA_ "SigGroup" SG_ 288 SpdLimRemMgrSts "ImobVehRemMgrSts1";
BA_ "GenSigStartValue" SG_ 288 StrtInProgs_UB 1;
BA_ "GenSigStartValue" SG_ 224 ActvnOfTrlrFogLiCmd_UB 1;
BA_ "GenSigStartValue" SG_ 224 CmptmtClngPreStrtReq_UB 1;
BA_ "GenSigStartValue" SG_ 224 DoorPassReSts_UB 1;
BA_ "GenSigStartValue" SG_ 224 DoorPassSts_UB 1;
BA_ "GenSigStartValue" SG_ 224 DrvrSeatDispMassgFct_UB 1;
BA_ "SigGroup" SG_ 224 DrvrSeatDispMassgFctMassgInten "DrvrSeatDispMassgFct";
BA_ "GenSigStartValue" SG_ 224 DrvrSeatDispMassgFctMassgInten 1;
BA_ "SigGroup" SG_ 224 DrvrSeatDispMassgFctMassgProg "DrvrSeatDispMassgFct";
BA_ "SigGroup" SG_ 224 DrvrSeatDispMassgFctMassgSpdLvl "DrvrSeatDispMassgFct";
BA_ "GenSigStartValue" SG_ 224 DrvrSeatDispMassgFctMassgSpdLvl 1;
BA_ "SigGroup" SG_ 224 DrvrSeatDispMassgFctOnOff "DrvrSeatDispMassgFct";
BA_ "GenSigStartValue" SG_ 224 HvPwrAvlForClimaEstimd_UB 1;
BA_ "GenSigStartValue" SG_ 224 IntrBriSts_UB 1;
BA_ "GenSigStartValue" SG_ 224 MirrTintgCmd_UB 1;
BA_ "GenSigStartValue" SG_ 224 PassSeatDispMassgFct_UB 1;
BA_ "SigGroup" SG_ 224 PassSeatDispMassgFctMassgInten "PassSeatDispMassgFct";
BA_ "GenSigStartValue" SG_ 224 PassSeatDispMassgFctMassgInten 1;
BA_ "SigGroup" SG_ 224 PassSeatDispMassgFctMassgProg "PassSeatDispMassgFct";
BA_ "SigGroup" SG_ 224 PassSeatDispMassgFctMassgSpdLvl "PassSeatDispMassgFct";
BA_ "GenSigStartValue" SG_ 224 PassSeatDispMassgFctMassgSpdLvl 1;
BA_ "SigGroup" SG_ 224 PassSeatDispMassgFctOnOff "PassSeatDispMassgFct";
BA_ "GenSigStartValue" SG_ 224 TrlrLampChkReq_UB 1;
BA_ "GenSigStartValue" SG_ 224 TrPosnUpprProgmReq_UB 1;
BA_ "GenSigStartValue" SG_ 224 TrSts_UB 1;
BA_ "GenSigStartValue" SG_ 240 ActvnOfPosnReCmd 1;
BA_ "GenSigStartValue" SG_ 240 ActvnOfPosnReCmd_UB 1;
BA_ "GenSigStartValue" SG_ 240 ActvnOfWshrFrntSafe_UB 1;
BA_ "GenSigStartValue" SG_ 240 AsyFanSts_UB 1;
BA_ "SigGroup" SG_ 240 CarModSts1 "VehModMngtGlbSafe1";
BA_ "SigGroup" SG_ 240 CarModSubtypWdCarModSubtyp "VehModMngtGlbSafe1";
BA_ "GenSigStartValue" SG_ 240 DrvrCtrlOfPassSeatFrntReqd_UB 1;
BA_ "GenSigStartValue" SG_ 240 DrvrDesDir_UB 1;
BA_ "SigGroup" SG_ 240 EgyLvlElecMai "VehModMngtGlbSafe1";
BA_ "SigGroup" SG_ 240 EgyLvlElecSubtyp "VehModMngtGlbSafe1";
BA_ "SigGroup" SG_ 240 FltEgyCnsWdSts "VehModMngtGlbSafe1";
BA_ "GenSigStartValue" SG_ 240 NetCtrlrActvt_UB 1;
BA_ "SigGroup" SG_ 240 NetCtrlrActvtPrio "NetCtrlrActvt";
BA_ "SigGroup" SG_ 240 NetCtrlrActvtResourceGroup "NetCtrlrActvt";
BA_ "SigGroup" SG_ 240 PwrLvlElecMai "VehModMngtGlbSafe1";
BA_ "SigGroup" SG_ 240 PwrLvlElecSubtyp "VehModMngtGlbSafe1";
BA_ "SigGroup" SG_ 240 UsgModSts "VehModMngtGlbSafe1";
BA_ "GenSigStartValue" SG_ 240 UsgModSts 1;
BA_ "GenSigStartValue" SG_ 240 VehModMngtGlbSafe1_UB 1;
BA_ "GenSigDataID" SG_ 240 VehModMngtGlbSafe1Chks "0x74";
BA_ "GenSigFuncType" SG_ 240 VehModMngtGlbSafe1Chks 15;
BA_ "SigGroup" SG_ 240 VehModMngtGlbSafe1Chks "VehModMngtGlbSafe1";
BA_ "GenSigFuncType" SG_ 240 VehModMngtGlbSafe1Cntr 16;
BA_ "SigGroup" SG_ 240 VehModMngtGlbSafe1Cntr "VehModMngtGlbSafe1";
BA_ "GenSigStartValue" SG_ 256 CamHeatrActv_UB 1;
BA_ "GenSigStartValue" SG_ 256 DefrstSts_UB 1;
BA_ "GenSigStartValue" SG_ 256 EngPAmbAir1_UB 1;
BA_ "GenSigStartValue" SG_ 256 ExtrMirrFoldSetg_UB 1;
BA_ "SigGroup" SG_ 256 ExtrMirrFoldSetgPen "ExtrMirrFoldSetg";
BA_ "SigGroup" SG_ 256 ExtrMirrFoldSetgSts "ExtrMirrFoldSetg";
BA_ "GenSigStartValue" SG_ 256 ExtrMirrTiltSetg2_UB 1;
BA_ "SigGroup" SG_ 256 ExtrMirrTiltSetg2IdPen "ExtrMirrTiltSetg2";
BA_ "SigGroup" SG_ 256 ExtrMirrTiltSetg2MirrDrvr "ExtrMirrTiltSetg2";
BA_ "SigGroup" SG_ 256 ExtrMirrTiltSetg2MirrPass "ExtrMirrTiltSetg2";
BA_ "GenSigStartValue" SG_ 256 HoodSts_UB 1;
BA_ "GenSigStartValue" SG_ 256 LockgCenSts_UB 1;
BA_ "GenSigStartValue" SG_ 256 LockgCenStsForUsrFb_UB 1;
BA_ "SigGroup" SG_ 256 LockgCenStsLockSt "LockgCenSts";
BA_ "SigGroup" SG_ 256 LockgCenStsUpdEve "LockgCenSts";
BA_ "SigGroup" SG_ 256 LockgCenTrigSrc "LockgCenSts";
BA_ "SigGroup" SG_ 256 MirrDefrstSts "DefrstSts";
BA_ "GenSigStartValue" SG_ 256 SteerWhlHeatgPwrAct_UB 1;
BA_ "SigGroup" SG_ 256 WindDefrstFrntSts "DefrstSts";
BA_ "SigGroup" SG_ 256 WinDefrstReSts "DefrstSts";
BA_ "GenSigStartValue" SG_ 320 DispBattEgyIn_UB 1;
BA_ "GenSigStartValue" SG_ 320 DispBattEgyOut_UB 1;
BA_ "GenSigStartValue" SG_ 320 HmiCmptmtAirDistbnFrnt 7;
BA_ "GenSigStartValue" SG_ 320 HmiCmptmtAirDistbnFrnt_UB 1;
BA_ "GenSigStartValue" SG_ 320 HmiDefrstMaxReq_UB 1;
BA_ "GenSigStartValue" SG_ 320 HmiHvacFanLvlFrnt_UB 1;
BA_ "GenSigStartValue" SG_ 320 HmiHvacFanLvlRe_UB 1;
BA_ "GenSigStartValue" SG_ 320 HmiHvacRecircCmd_UB 1;
BA_ "GenSigStartValue" SG_ 320 HmiHvacReCtrl_UB 1;
BA_ "GenSigStartValue" SG_ 320 ModOnLiCmd_UB 1;
BA_ "GenSigStartValue" SG_ 320 ModOnLiTCmd_UB 1;
BA_ "GenSigStartValue" SG_ 320 ModOnLiTintgCmd_UB 1;
BA_ "GenSigStartValue" SG_ 384 ActvnOfTrlrLiRvsg_UB 1;
BA_ "GenSigStartValue" SG_ 384 ClimaEcoModRqrd_UB 1;
BA_ "GenSigStartValue" SG_ 384 HeatrDurgDrvgReqd_UB 1;
BA_ "GenSigStartValue" SG_ 384 HmiCmptmtCoolgReq_UB 1;
BA_ "GenSigStartValue" SG_ 384 HmiCmptmtTSp_UB 1;
BA_ "SigGroup" SG_ 384 HmiCmptmtTSpForRowFirstLe "HmiCmptmtTSp";
BA_ "GenSigStartValue" SG_ 384 HmiCmptmtTSpForRowFirstLe -2;
BA_ "SigGroup" SG_ 384 HmiCmptmtTSpForRowFirstRi "HmiCmptmtTSp";
BA_ "GenSigStartValue" SG_ 384 HmiCmptmtTSpForRowFirstRi -2;
BA_ "SigGroup" SG_ 384 HmiCmptmtTSpForRowSecLe "HmiCmptmtTSp";
BA_ "GenSigStartValue" SG_ 384 HmiCmptmtTSpForRowSecLe -2;
BA_ "SigGroup" SG_ 384 HmiCmptmtTSpForRowSecRi "HmiCmptmtTSp";
BA_ "GenSigStartValue" SG_ 384 HmiCmptmtTSpForRowSecRi -2;
BA_ "SigGroup" SG_ 384 HmiCmptmtTSpSpclForRowFirstLe "HmiCmptmtTSp";
BA_ "SigGroup" SG_ 384 HmiCmptmtTSpSpclForRowFirstRi "HmiCmptmtTSp";
BA_ "SigGroup" SG_ 384 HmiCmptmtTSpSpclForRowSecLe "HmiCmptmtTSp";
BA_ "SigGroup" SG_ 384 HmiCmptmtTSpSpclForRowSecRi "HmiCmptmtTSp";
BA_ "GenSigStartValue" SG_ 384 HvacCooltFlowAct_UB 1;
BA_ "GenSigStartValue" SG_ 384 SeatSwtLeSigThrd_UB 1;
BA_ "GenSigStartValue" SG_ 384 SeatSwtRiSigThrd_UB 1;
BA_ "GenSigStartValue" SG_ 400 ChrgnTiEstimd_UB 1;
BA_ "SigGroup" SG_ 400 DshbT "SunData";
BA_ "GenSigStartValue" SG_ 400 DshbT 40;
BA_ "SigGroup" SG_ 400 DshbTQf "SunData";
BA_ "SigGroup" SG_ 400 SunAzi "SunData";
BA_ "SigGroup" SG_ 400 SunAziQf "SunData";
BA_ "GenSigStartValue" SG_ 400 SunData_UB 1;
BA_ "SigGroup" SG_ 400 SunDataSunElevnCmp "SunData";
BA_ "SigGroup" SG_ 400 SunDataSunElevnCmpQf "SunData";
BA_ "SigGroup" SG_ 400 SunElevn "SunData";
BA_ "SigGroup" SG_ 400 SunElevnQf "SunData";
BA_ "SigGroup" SG_ 400 SunLoad "SunData";
BA_ "SigGroup" SG_ 400 SunLoadQF "SunData";
BA_ "GenSigStartValue" SG_ 432 CnclHldChrgReq_UB 1;
BA_ "SigGroup" SG_ 432 CoolgLimd "CoolgLoadGroup";
BA_ "SigGroup" SG_ 432 CoolgLoad "CoolgLoadGroup";
BA_ "GenSigStartValue" SG_ 432 CoolgLoadGroup_UB 1;
BA_ "GenSigStartValue" SG_ 432 DiagcHvacCooltVlvErr_UB 1;
BA_ "GenSigStartValue" SG_ 432 EngCooltLoFlowReq_UB 1;
BA_ "GenSigStartValue" SG_ 432 ErsStrtRes_UB 1;
BA_ "GenSigStartValue" SG_ 432 EvaprVlvReqRe_UB 1;
BA_ "GenSigStartValue" SG_ 432 FuTankPOkForFuHeatr_UB 1;
BA_ "GenSigStartValue" SG_ 432 MirrDefrstAtDrvrCmd_UB 1;
BA_ "GenSigStartValue" SG_ 432 MirrDefrstAtPassCmd_UB 1;
BA_ "SigGroup" SG_ 432 VehSpdLgtSafe "VehSpdLgtSafeGroup";
BA_ "GenSigDataID" SG_ 432 VehSpdLgtSafeChks "0x37";
BA_ "GenSigFuncType" SG_ 432 VehSpdLgtSafeChks 15;
BA_ "SigGroup" SG_ 432 VehSpdLgtSafeChks "VehSpdLgtSafeGroup";
BA_ "GenSigFuncType" SG_ 432 VehSpdLgtSafeCntr 16;
BA_ "SigGroup" SG_ 432 VehSpdLgtSafeCntr "VehSpdLgtSafeGroup";
BA_ "GenSigStartValue" SG_ 432 VehSpdLgtSafeGroup_UB 1;
BA_ "SigGroup" SG_ 432 VehSpdLgtSafeQf "VehSpdLgtSafeGroup";
BA_ "GenSigStartValue" SG_ 432 VehSpdLgtSafeQf 1;
BA_ "GenSigStartValue" SG_ 496 CmptmtCoolgSts_UB 1;
BA_ "GenSigStartValue" SG_ 496 EngOilLvlSts_UB 1;
BA_ "GenSigStartValue" SG_ 496 HmiSeatClima_UB 1;
BA_ "SigGroup" SG_ 496 HmiSeatHeatgForRowFirstLe "HmiSeatClima";
BA_ "SigGroup" SG_ 496 HmiSeatHeatgForRowFirstRi "HmiSeatClima";
BA_ "SigGroup" SG_ 496 HmiSeatHeatgForRowSecLe "HmiSeatClima";
BA_ "SigGroup" SG_ 496 HmiSeatHeatgForRowSecRi "HmiSeatClima";
BA_ "SigGroup" SG_ 496 HmiSeatVentnForRowFirstLe "HmiSeatClima";
BA_ "SigGroup" SG_ 496 HmiSeatVentnForRowFirstRi "HmiSeatClima";
BA_ "GenSigStartValue" SG_ 496 HvClimaCmd 1;
BA_ "GenSigStartValue" SG_ 496 HvClimaCmd_UB 1;
BA_ "GenSigStartValue" SG_ 496 HvHeatgPwrAllwd_UB 1;
BA_ "GenSigStartValue" SG_ 496 SunCurtPosnSts_UB 1;
VAL_ 80 ClimaWarn 0 "ClimaWarn_NoWarn" 1 "ClimaWarn_FuLo" 2 "ClimaWarn_BattLo" 3 "ClimaWarn_FuAndBattLo" 4 "ClimaWarn_TLo" 5 "ClimaWarn_THi" 6 "ClimaWarn_Error" 7 "ClimaWarn_HVError" 8 "ClimaWarn_ActvnLimd" ;
VAL_ 80 HvacCoolgEnaFrnt 0 "OnOff1_Off" 1 "OnOff1_On" ;
VAL_ 80 HvacEvaprTFrntQf 0 "HvacTIfQf_SnsrDataNotOk" 1 "HvacTIfQf_SnsrDataOk" ;
VAL_ 96 ClimaActv 0 "OnOff1_Off" 1 "OnOff1_On" ;
VAL_ 96 EngSpdIncIdleForClima 0 "Flg1_Rst" 1 "Flg1_Set" ;
VAL_ 336 AmbTEstimdAmbTEstimdQf 0 "HvacTIfQf_SnsrDataNotOk" 1 "HvacTIfQf_SnsrDataOk" ;
VAL_ 336 ClimaSts 0 "ClimaSts_Start" 1 "ClimaSts_Finish" ;
VAL_ 336 MirrDefrstReq 0 "OnOff1_Off" 1 "OnOff1_On" ;
VAL_ 336 WinDefrstFrntReq 0 "OnOff1_Off" 1 "OnOff1_On" ;
VAL_ 336 WinDefrstReReq 0 "OnOff1_Off" 1 "OnOff1_On" ;
VAL_ 336 WindIceDetdFrnt 0 "OnOff1_Off" 1 "OnOff1_On" ;
VAL_ 336 WindIceDetdRe 0 "OnOff1_Off" 1 "OnOff1_On" ;
VAL_ 368 RlyCmftForClimaReq 0 "OnOff1_Off" 1 "OnOff1_On" ;
VAL_ 368 UBoostReqByClima 0 "ReqSts1_NotReqd" 1 "ReqSts1_Reqd" ;
VAL_ 368 WindDewTUpprDewTQf 0 "DataQf_NotOk" 1 "DataQf_Ok" ;
VAL_ 448 EngHeatgReq 0 "OnOff1_Off" 1 "OnOff1_On" ;
VAL_ 448 EvaprVlvReSts 0 "EvaprVlvSts_VlvReqdToClsd" 1 "EvaprVlvSts_VlvReqdToOpen" 2 "EvaprVlvSts_ElecErrByCircOpen" 3 "EvaprVlvSts_ElecErrShoToGnd" 4 "EvaprVlvSts_ElecErrShoToPwrSply" 5 "EvaprVlvSts_Resd" ;
VAL_ 448 EvaprVlvReStsExtdDiagcStsForCirc 0 "DiagcSts2_DiagcStsNotRdy" 1 "DiagcSts2_DiagcStsPassd" 2 "DiagcSts2_DiagcStsFaild" 3 "DiagcSts2_Resd" ;
VAL_ 448 EvaprVlvReStsExtdDiagcStsForShoT 0 "DiagcSts2_DiagcStsNotRdy" 1 "DiagcSts2_DiagcStsPassd" 2 "DiagcSts2_DiagcStsFaild" 3 "DiagcSts2_Resd" ;
VAL_ 448 EvaprVlvReStsExtdDiagcStsFo_0000 0 "DiagcSts2_DiagcStsNotRdy" 1 "DiagcSts2_DiagcStsPassd" 2 "DiagcSts2_DiagcStsFaild" 3 "DiagcSts2_Resd" ;
VAL_ 448 FuTankPRelsForFuHeatrReq 0 "OnOff1_Off" 1 "OnOff1_On" ;
VAL_ 448 HvacCooltVlvReqExt 0 "OnOff1_Off" 1 "OnOff1_On" ;
VAL_ 448 HvacCooltVlvSts 0 "HvacCooltVlvSts_VlvReqdToClsd" 1 "HvacCooltVlvSts_VlvReqdToOpen" 2 "HvacCooltVlvSts_ElecErrByCircOpen" 3 "HvacCooltVlvSts_ElecErrShoToGnd" 4 "HvacCooltVlvSts_ElecErrShoToPwrSply" 5 "HvacCooltVlvSts_Resd" ;
VAL_ 448 WindTWindTQf 0 "DataQf_NotOk" 1 "DataQf_Ok" ;
VAL_ 272 EngRunngReqByClima 0 "EngRunngReq_Dft" 1 "EngRunngReq_StopInhb" 2 "EngRunngReq_RunReq" 3 "EngRunngReq_Resd" ;
VAL_ 272 HvacCoolgEnaRe 0 "OnOff1_Off" 1 "OnOff1_On" ;
VAL_ 272 LvlOfClimaCmft 0 "LvlOfClimaCmft_Off" 1 "LvlOfClimaCmft_Lvl1" 2 "LvlOfClimaCmft_Lvl2" 3 "LvlOfClimaCmft_Lvl3" 4 "LvlOfClimaCmft_Lvl4" 5 "LvlOfClimaCmft_Lvl5" 6 "LvlOfClimaCmft_Lvl6" 7 "LvlOfClimaCmft_Lvl7" ;
VAL_ 272 PwrChrgDetdForPrkgHeatrElec 0 "Boolean_FALSE" 1 "Boolean_TRUE" ;
VAL_ 272 SeatHeatgAutCdn 0 "Flg1_Rst" 1 "Flg1_Set" ;
VAL_ 576 ClimaTmrSts 0 "OnOff1_Off" 1 "OnOff1_On" ;
VAL_ 576 CoolgStsForDisp 0 "CoolgStsForDisp_NoCoolgActv" 1 "CoolgStsForDisp_CoolgLvlStrtd1" 2 "CoolgStsForDisp_CoolgLvlStrtd2" 3 "CoolgStsForDisp_Resd" ;
VAL_ 576 CustClimaOvrdNotifForHmiCpt 0 "Flg1_Rst" 1 "Flg1_Set" ;
VAL_ 576 FuHeatrActv 0 "OnOff1_Off" 1 "OnOff1_On" ;
VAL_ 576 PostDrvgClimaAvl 0 "OnOff1_Off" 1 "OnOff1_On" ;
VAL_ 576 RlyCrashForClimaReq 0 "OnOff1_Off" 1 "OnOff1_On" ;
VAL_ 576 SteerWhlHeatgDurgClima 0 "Boolean_FALSE" 1 "Boolean_TRUE" ;
VAL_ 597 ClimaActvAlrmSts 0 "OnOff1_Off" 1 "OnOff1_On" ;
VAL_ 597 ClngActv 0 "OnOffNoReq_NoReq" 1 "OnOffNoReq_On" 2 "OnOffNoReq_Off" ;
VAL_ 597 CmptmtAirTEstimdExtdQlyFlg 0 "GenQf1_UndefindDataAccur" 1 "GenQf1_TmpUndefdData" 2 "GenQf1_DataAccurNotWithinSpcn" 3 "GenQf1_AccurData" ;
VAL_ 597 CooltVlvOutpTyp 0 "CooltVlvOutpTyp_Undefd" 1 "CooltVlvOutpTyp_ILimd" 2 "CooltVlvOutpTyp_IFull" ;
VAL_ 597 HeatgForHvBattSts 0 "HeatgForHvBattSts_Init" 1 "HeatgForHvBattSts_Off" 2 "HeatgForHvBattSts_StrtUp" 3 "HeatgForHvBattSts_Inhibited" 4 "HeatgForHvBattSts_On" 5 "HeatgForHvBattSts_Reserved" ;
VAL_ 597 PreClngNotif 0 "PreClngNotif_NoReq" 1 "PreClngNotif_NoWarn" 2 "PreClngNotif_Done" 3 "PreClngNotif_Err" 4 "PreClngNotif_Intrpt" 5 "PreClngNotif_Spare1" 6 "PreClngNotif_Spare2" 7 "PreClngNotif_Spare3" ;
VAL_ 1122 HmiCmptmtAirDistbnFrntM1 0 "HmiCmptmtAirDistbnFrnt_Flr" 1 "HmiCmptmtAirDistbnFrnt_Vent" 2 "HmiCmptmtAirDistbnFrnt_Defrst" 3 "HmiCmptmtAirDistbnFrnt_FlrDefrst" 4 "HmiCmptmtAirDistbnFrnt_FlrVent" 5 "HmiCmptmtAirDistbnFrnt_VentDefrst" 6 "HmiCmptmtAirDistbnFrnt_FlrVentDefrst" 7 "HmiCmptmtAirDistbnFrnt_Aut" ;
VAL_ 1122 HmiCmptmtCoolgReqM1 0 "HmiCmptmtCoolgReq_Off" 1 "HmiCmptmtCoolgReq_Auto" ;
VAL_ 1122 HmiCmptmtTSpSpclForRowFirstLeM1 0 "HmiCmptmtTSpSpcl_Norm" 1 "HmiCmptmtTSpSpcl_Lo" 2 "HmiCmptmtTSpSpcl_Hi" ;
VAL_ 1122 HmiCmptmtTSpSpclForRowFirstRiM1 0 "HmiCmptmtTSpSpcl_Norm" 1 "HmiCmptmtTSpSpcl_Lo" 2 "HmiCmptmtTSpSpcl_Hi" ;
VAL_ 1122 HmiCmptmtTSpSpclForRowSecLeM1 0 "HmiCmptmtTSpSpcl_Norm" 1 "HmiCmptmtTSpSpcl_Lo" 2 "HmiCmptmtTSpSpcl_Hi" ;
VAL_ 1122 HmiCmptmtTSpSpclForRowSecRiM1 0 "HmiCmptmtTSpSpcl_Norm" 1 "HmiCmptmtTSpSpcl_Lo" 2 "HmiCmptmtTSpSpcl_Hi" ;
VAL_ 1122 HmiDefrstMaxReqM1 0 "ActrReq_Off" 1 "ActrReq_On" 2 "ActrReq_AutOn" ;
VAL_ 1122 HmiHvacFanLvlFrntM1 0 "HmiHvacFanLvl_Off" 1 "HmiHvacFanLvl_Min" 2 "HmiHvacFanLvl_LvlMan1" 3 "HmiHvacFanLvl_LvlMan2" 4 "HmiHvacFanLvl_LvlMan3" 5 "HmiHvacFanLvl_LvlMan4" 6 "HmiHvacFanLvl_LvlMan5" 7 "HmiHvacFanLvl_LvlMan6" 8 "HmiHvacFanLvl_LvlMan7" 9 "HmiHvacFanLvl_LvlAutMinusMinus" 10 "HmiHvacFanLvl_LvlAutMinus" 11 "HmiHvacFanLvl_LvlAutoNorm" 12 "HmiHvacFanLvl_LvlAutPlus" 13 "HmiHvacFanLvl_LvlAutPlusPlus" 14 "HmiHvacFanLvl_Max" ;
VAL_ 1122 HmiHvacRecircCmdM1 0 "HmiHvacRecircCmd_Aut" 1 "HmiHvacRecircCmd_AutWithAirQly" 2 "HmiHvacRecircCmd_RecircFull" ;
VAL_ 32 ActvnOfTrlrBrkLi 0 "OnOff1_Off" 1 "OnOff1_On" ;
VAL_ 32 DoorDrvrIntrSwtLedLockgReCmd 0 "OnOff1_Off" 1 "OnOff1_On" ;
VAL_ 32 DoorDrvrLockCmd 0 "LockActvnSafe1_LockActvnOff" 1 "LockActvnSafe1_LockActvnUnlck" 2 "LockActvnSafe1_LockActvnLock" 3 "LockActvnSafe1_LockActvnSafe" 4 "LockActvnSafe1_LockActvnUnlckByCrash1" 8 "LockActvnSafe1_LockActvnUnlckByCrash2" 12 "LockActvnSafe1_LockActvnUnlckByCrash0" 13 "LockActvnSafe1_LockActvnUnlckByCrash4" 14 "LockActvnSafe1_LockActvnUnlckByCrash3" ;
VAL_ 32 DoorDrvrLockReCmd 0 "LockActvnSafe1_LockActvnOff" 1 "LockActvnSafe1_LockActvnUnlck" 2 "LockActvnSafe1_LockActvnLock" 3 "LockActvnSafe1_LockActvnSafe" 4 "LockActvnSafe1_LockActvnUnlckByCrash1" 8 "LockActvnSafe1_LockActvnUnlckByCrash2" 12 "LockActvnSafe1_LockActvnUnlckByCrash0" 13 "LockActvnSafe1_LockActvnUnlckByCrash4" 14 "LockActvnSafe1_LockActvnUnlckByCrash3" ;
VAL_ 32 DoorPassIntrSwtLedLockgReCmd 0 "OnOff1_Off" 1 "OnOff1_On" ;
VAL_ 32 DoorPassLockCmd 0 "LockActvnSafe1_LockActvnOff" 1 "LockActvnSafe1_LockActvnUnlck" 2 "LockActvnSafe1_LockActvnLock" 3 "LockActvnSafe1_LockActvnSafe" 4 "LockActvnSafe1_LockActvnUnlckByCrash1" 8 "LockActvnSafe1_LockActvnUnlckByCrash2" 12 "LockActvnSafe1_LockActvnUnlckByCrash0" 13 "LockActvnSafe1_LockActvnUnlckByCrash4" 14 "LockActvnSafe1_LockActvnUnlckByCrash3" ;
VAL_ 32 DoorPassLockReCmd 0 "LockActvnSafe1_LockActvnOff" 1 "LockActvnSafe1_LockActvnUnlck" 2 "LockActvnSafe1_LockActvnLock" 3 "LockActvnSafe1_LockActvnSafe" 4 "LockActvnSafe1_LockActvnUnlckByCrash1" 8 "LockActvnSafe1_LockActvnUnlckByCrash2" 12 "LockActvnSafe1_LockActvnUnlckByCrash0" 13 "LockActvnSafe1_LockActvnUnlckByCrash4" 14 "LockActvnSafe1_LockActvnUnlckByCrash3" ;
VAL_ 32 EveMemPosn 0 "EveMemPosn_Idle" 1 "EveMemPosn_Store" 2 "EveMemPosn_Load" 3 "EveMemPosn_Stop" 4 "EveMemPosn_AutMovmt" ;
VAL_ 32 HndlDoorLiDrvr 0 "OnOff1_Off" 1 "OnOff1_On" ;
VAL_ 32 HndlDoorLiDrvrRe 0 "OnOff1_Off" 1 "OnOff1_On" ;
VAL_ 32 HndlDoorLiPass 0 "OnOff1_Off" 1 "OnOff1_On" ;
VAL_ 32 HndlDoorLiPassRe 0 "OnOff1_Off" 1 "OnOff1_On" ;
VAL_ 32 HvCooltHeatrEnad 0 "Boolean_FALSE" 1 "Boolean_TRUE" ;
VAL_ 32 IndcrTurnCmd1WdHzrdTelltl 0 "OnOff1_Off" 1 "OnOff1_On" ;
VAL_ 32 IndcrTurnCmd1WdIndcrTrig 0 "IndcrSts1_Off" 1 "IndcrSts1_LeOn" 2 "IndcrSts1_RiOn" 3 "IndcrSts1_LeAndRiOn" ;
VAL_ 32 IndcrTurnSts1WdSts 0 "IndcrSts1_Off" 1 "IndcrSts1_LeOn" 2 "IndcrSts1_RiOn" 3 "IndcrSts1_LeAndRiOn" ;
VAL_ 32 IntrLiActvn1 0 "Boolean_FALSE" 1 "Boolean_TRUE" ;
VAL_ 32 IntrLiDmdOff 0 "Boolean_FALSE" 1 "Boolean_TRUE" ;
VAL_ 32 IntrLiRoofDim 0 "Boolean_FALSE" 1 "Boolean_TRUE" ;
VAL_ 32 IntrLiRoofDmdOff 0 "Boolean_FALSE" 1 "Boolean_TRUE" ;
VAL_ 32 LoadAndStoreReqIdPen 0 "IdPen_ProfUkwn" 1 "IdPen_Prof1" 2 "IdPen_Prof2" 3 "IdPen_Prof3" 4 "IdPen_Prof4" 5 "IdPen_Prof5" 6 "IdPen_Prof6" 7 "IdPen_Prof7" 8 "IdPen_Prof8" 9 "IdPen_Prof9" 10 "IdPen_Prof10" 11 "IdPen_Prof11" 12 "IdPen_Prof12" 13 "IdPen_Prof13" 14 "IdPen_Resd14" 15 "IdPen_ProfAll" ;
VAL_ 32 LoadAndStoreReqInOutEasy 0 "OnOff1_Off" 1 "OnOff1_On" ;
VAL_ 32 MemPosn 0 "MemPosn_ProfPosn" 1 "MemPosn_MemBnk1" 2 "MemPosn_MemBnk2" 3 "MemPosn_MemBnk3" ;
VAL_ 64 ClimaRqrd 0 "OnOffNoReq_NoReq" 1 "OnOffNoReq_On" 2 "OnOffNoReq_Off" ;
VAL_ 64 CllsnWarnIndcnLe 0 "LcmaIndcn_NoLcmaWarn" 1 "LcmaIndcn_LcmaWarnLvl1" 2 "LcmaIndcn_NotUsed" 3 "LcmaIndcn_LcmaWarnLvl2" ;
VAL_ 64 CllsnWarnIndcnRi 0 "LcmaIndcn_NoLcmaWarn" 1 "LcmaIndcn_LcmaWarnLvl1" 2 "LcmaIndcn_NotUsed" 3 "LcmaIndcn_LcmaWarnLvl2" ;
VAL_ 64 DoorDrvrIntrSwtLedLockgCmd 0 "OnOff1_Off" 1 "OnOff1_On" ;
VAL_ 64 DoorDrvrReSts 0 "DoorSts2_Ukwn" 1 "DoorSts2_Opend" 2 "DoorSts2_Clsd" ;
VAL_ 64 DoorDrvrSts 0 "DoorSts2_Ukwn" 1 "DoorSts2_Opend" 2 "DoorSts2_Clsd" ;
VAL_ 64 DoorPassIntrSwtLedLockgCmd 0 "OnOff1_Off" 1 "OnOff1_On" ;
VAL_ 64 GlbWinCmd 0 "OpenClsGlbCmd_Idle" 1 "OpenClsGlbCmd_GlobalOpenWindow" 2 "OpenClsGlbCmd_GlobalCloseWindowAndSunroof" 3 "OpenClsGlbCmd_GlobalCloseWindow" 4 "OpenClsGlbCmd_GlobalStop" 5 "OpenClsGlbCmd_Resd1" 6 "OpenClsGlbCmd_Resd2" 7 "OpenClsGlbCmd_Resd3" ;
VAL_ 64 LcmaIndcnLe 0 "LcmaIndcn_NoLcmaWarn" 1 "LcmaIndcn_LcmaWarnLvl1" 2 "LcmaIndcn_NotUsed" 3 "LcmaIndcn_LcmaWarnLvl2" ;
VAL_ 64 LcmaIndcnRi 0 "LcmaIndcn_NoLcmaWarn" 1 "LcmaIndcn_LcmaWarnLvl1" 2 "LcmaIndcn_NotUsed" 3 "LcmaIndcn_LcmaWarnLvl2" ;
VAL_ 64 PassLoadAndStoreReqErgoPosn 0 "PassMemPosn_Idle" 1 "PassMemPosn_MemBnk1" 2 "PassMemPosn_MemBnk2" 3 "PassMemPosn_MemBnk3" ;
VAL_ 64 PassLoadAndStoreReqErgoSetgEve 0 "EveMemPosn_Idle" 1 "EveMemPosn_Store" 2 "EveMemPosn_Load" 3 "EveMemPosn_Stop" 4 "EveMemPosn_AutMovmt" ;
VAL_ 64 SaveSetgToMemPrmnt 0 "OffOnAut1_Off" 1 "OffOnAut1_On" 2 "OffOnAut1_Aut" ;
VAL_ 64 TrNoKeyPrsntAcoustReq 0 "OnOff1_Off" 1 "OnOff1_On" ;
VAL_ 64 TrOpenerReqTrOpenerReq 0 "TrOpenerReq1_TrOpenerIdle" 1 "TrOpenerReq1_TrOpenerOpen" 2 "TrOpenerReq1_TrOpenerCls" 3 "TrOpenerReq1_TrOpenerStop" ;
VAL_ 64 TrOpenerReqTrOpenerTrigSrc 0 "TrOpenerTrigSrc1_TrNoTrigSrc" 1 "TrOpenerTrigSrc1_TrKeyRem" 2 "TrOpenerTrigSrc1_TrSwtIntr" 3 "TrOpenerTrigSrc1_TrByFootOper" 4 "TrOpenerTrigSrc1_TrHndlOutd" 5 "TrOpenerTrigSrc1_TrShutFace" ;
VAL_ 64 TwliBriSts 0 "TwliBriSts1_Night" 1 "TwliBriSts1_Day" ;
VAL_ 64 VehMtnStSafe 0 "VehMtnSt2_Ukwn" 1 "VehMtnSt2_StandStillVal1" 2 "VehMtnSt2_StandStillVal2" 3 "VehMtnSt2_StandStillVal3" 4 "VehMtnSt2_RollgFwdVal1" 5 "VehMtnSt2_RollgFwdVal2" 6 "VehMtnSt2_RollgBackwVal1" 7 "VehMtnSt2_RollgBackwVal2" ;
VAL_ 243 CrashSts2 0 "CrashSts3_Resd1" 1 "CrashSts3_NoCrash" 2 "CrashSts3_Crash" 3 "CrashSts3_Resd2" ;
VAL_ 245 RecOfImpctSafeCrashState 0 "CrashSt_NoCrash" 1 "CrashSt_CrashImminent" 2 "CrashSt_CrashInProgress" 3 "CrashSt_CrashEnding" ;
VAL_ 245 RecOfImpctSafeVehOri 0 "Orntn_OnWheels" 1 "Orntn_LeftSide" 2 "Orntn_RightSide" 3 "Orntn_OnRoof" 4 "Orntn_Indeterminate" 5 "Orntn_Resd1" 6 "Orntn_Resd2" 7 "Orntn_Resd3" ;
VAL_ 176 BltLockStAtDrvrForBltLockSt1 0 "BltLockSt1_Unlock" 1 "BltLockSt1_Lock" ;
VAL_ 176 BltLockStAtDrvrForDevErrSts2 0 "DevErrSts2_NoFlt" 1 "DevErrSts2_Flt" ;
VAL_ 176 BltLockStAtPassForBltLockSt1 0 "BltLockSt1_Unlock" 1 "BltLockSt1_Lock" ;
VAL_ 176 BltLockStAtPassForBltLockSts 0 "DevErrSts2_NoFlt" 1 "DevErrSts2_Flt" ;
VAL_ 176 BltLockStAtRowSecLeForBltLockEqu 0 "CptEquid_Equid" 1 "CptEquid_NotEquid" ;
VAL_ 176 BltLockStAtRowSecLeForBltLockSt1 0 "BltLockSt1_Unlock" 1 "BltLockSt1_Lock" ;
VAL_ 176 BltLockStAtRowSecLeForBltLockSts 0 "DevErrSts2_NoFlt" 1 "DevErrSts2_Flt" ;
VAL_ 176 BltLockStAtRowSecMidForBltLockEq 0 "CptEquid_Equid" 1 "CptEquid_NotEquid" ;
VAL_ 176 BltLockStAtRowSecMidForBltLockSt 0 "BltLockSt1_Unlock" 1 "BltLockSt1_Lock" ;
VAL_ 176 BltLockStAtRowSecMidForBltL_0000 0 "DevErrSts2_NoFlt" 1 "DevErrSts2_Flt" ;
VAL_ 176 BltLockStAtRowSecRiForBltLockEqu 0 "CptEquid_Equid" 1 "CptEquid_NotEquid" ;
VAL_ 176 BltLockStAtRowSecRiForBltLockSt1 0 "BltLockSt1_Unlock" 1 "BltLockSt1_Lock" ;
VAL_ 176 BltLockStAtRowSecRiForBltLockSts 0 "DevErrSts2_NoFlt" 1 "DevErrSts2_Flt" ;
VAL_ 176 BltLockStAtRowThrdLeForBltLockEq 0 "CptEquid_Equid" 1 "CptEquid_NotEquid" ;
VAL_ 176 BltLockStAtRowThrdLeForBltLockSt 0 "BltLockSt1_Unlock" 1 "BltLockSt1_Lock" ;
VAL_ 176 BltLockStAtRowThrdLeForBltL_0000 0 "DevErrSts2_NoFlt" 1 "DevErrSts2_Flt" ;
VAL_ 176 BltLockStAtRowThrdRiForBltLockEq 0 "CptEquid_Equid" 1 "CptEquid_NotEquid" ;
VAL_ 176 BltLockStAtRowThrdRiForBltLockSt 0 "BltLockSt1_Unlock" 1 "BltLockSt1_Lock" ;
VAL_ 176 BltLockStAtRowThrdRiForBltL_0000 0 "DevErrSts2_NoFlt" 1 "DevErrSts2_Flt" ;
VAL_ 176 BrkFldLvl 0 "FldLvl_FldLvlHi" 1 "FldLvl_FldLvlLo" ;
VAL_ 176 ChrgnTyp 0 "ChrgnTyp_Disconnected" 1 "ChrgnTyp_AcChrgn" 2 "ChrgnTyp_ChaChrgn" 3 "ChrgnTyp_CcsChrgn" 4 "ChrgnTyp_GbtChrgn" 5 "ChrgnTyp_ThreePhaChrgn" 6 "ChrgnTyp_Indu" 255 "ChrgnTyp_Invld" ;
VAL_ 176 EngCooltLvl 0 "FldLvl_FldLvlHi" 1 "FldLvl_FldLvlLo" ;
VAL_ 176 ErsStrtApplSts 0 "ErsStrtApplSts_ErsStsOff" 1 "ErsStrtApplSts_ErsStsStrtg" 2 "ErsStrtApplSts_ErsStsRunng" ;
VAL_ 288 ImobRemMgrChkSts 0 "AvlSts1_TmpNotAvl" 1 "AvlSts1_PrmntNotAvl" 2 "AvlSts1_Avl" ;
VAL_ 288 ImobVehRemMgrSts 0 "ImobVehRemMgrSts_IdleRemMgrSts" 1 "ImobVehRemMgrSts_ImobnRemMgrSts" 2 "ImobVehRemMgrSts_NoImobnRemMgrSts" 3 "ImobVehRemMgrSts_ImobnStrtDiRemMgrSts" ;
VAL_ 288 ModOnLiInten 0 "IntrLiInten_Off" 1 "IntrLiInten_IntenLo" 2 "IntrLiInten_IntenHi" ;
VAL_ 288 StrtInProgs 0 "StrtInProgs1_StrtStsOff" 1 "StrtInProgs1_StrtStsImminent" 2 "StrtInProgs1_StrtStsStrtng" 3 "StrtInProgs1_StrtStsRunng" ;
VAL_ 224 ActvnOfTrlrFogLiCmd 0 "OnOff1_Off" 1 "OnOff1_On" ;
VAL_ 224 CmptmtClngPreStrtReq 0 "OnOffNoReq_NoReq" 1 "OnOffNoReq_On" 2 "OnOffNoReq_Off" ;
VAL_ 224 DoorPassReSts 0 "DoorSts2_Ukwn" 1 "DoorSts2_Opend" 2 "DoorSts2_Clsd" ;
VAL_ 224 DoorPassSts 0 "DoorSts2_Ukwn" 1 "DoorSts2_Opend" 2 "DoorSts2_Clsd" ;
VAL_ 224 DrvrSeatDispMassgFctMassgInten 0 "MassgIntenLvl_IntenLo" 1 "MassgIntenLvl_IntenNorm" 2 "MassgIntenLvl_IntenHi" ;
VAL_ 224 DrvrSeatDispMassgFctMassgProg 0 "MassgProgTyp_Prog1" 1 "MassgProgTyp_Prog2" 2 "MassgProgTyp_Prog3" 3 "MassgProgTyp_Prog4" 4 "MassgProgTyp_Prog5" ;
VAL_ 224 DrvrSeatDispMassgFctMassgSpdLvl 0 "MassgIntenLvl_IntenLo" 1 "MassgIntenLvl_IntenNorm" 2 "MassgIntenLvl_IntenHi" ;
VAL_ 224 DrvrSeatDispMassgFctOnOff 0 "OnOff1_Off" 1 "OnOff1_On" ;
VAL_ 224 PassSeatDispMassgFctMassgInten 0 "MassgIntenLvl_IntenLo" 1 "MassgIntenLvl_IntenNorm" 2 "MassgIntenLvl_IntenHi" ;
VAL_ 224 PassSeatDispMassgFctMassgProg 0 "MassgProgTyp_Prog1" 1 "MassgProgTyp_Prog2" 2 "MassgProgTyp_Prog3" 3 "MassgProgTyp_Prog4" 4 "MassgProgTyp_Prog5" ;
VAL_ 224 PassSeatDispMassgFctMassgSpdLvl 0 "MassgIntenLvl_IntenLo" 1 "MassgIntenLvl_IntenNorm" 2 "MassgIntenLvl_IntenHi" ;
VAL_ 224 PassSeatDispMassgFctOnOff 0 "OnOff1_Off" 1 "OnOff1_On" ;
VAL_ 224 TrlrLampChkReq 0 "StrtStopReq1_Idle" 1 "StrtStopReq1_StrtReq" 2 "StrtStopReq1_StopReq" 3 "StrtStopReq1_Resd" ;
VAL_ 224 TrPosnUpprProgmReq 0 "OnOff1_Off" 1 "OnOff1_On" ;
VAL_ 224 TrSts 0 "DoorSts2_Ukwn" 1 "DoorSts2_Opend" 2 "DoorSts2_Clsd" ;
VAL_ 240 ActvnOfPosnReCmd 0 "OnOffCrit1_NotVld1" 1 "OnOffCrit1_Off" 2 "OnOffCrit1_On" 3 "OnOffCrit1_NotVld2" ;
VAL_ 240 ActvnOfWshrFrntSafe 0 "OnOffCrit1_NotVld1" 1 "OnOffCrit1_Off" 2 "OnOffCrit1_On" 3 "OnOffCrit1_NotVld2" ;
VAL_ 240 AsyFanSts 0 "OnOff1_Off" 1 "OnOff1_On" ;
VAL_ 240 CarModSts1 0 "CarModSts1_CarModNorm" 1 "CarModSts1_CarModTrnsp" 2 "CarModSts1_CarModFcy" 3 "CarModSts1_CarModCrash" 5 "CarModSts1_CarModDyno" ;
VAL_ 240 DrvrCtrlOfPassSeatFrntReqd 0 "OnOff1_Off" 1 "OnOff1_On" ;
VAL_ 240 DrvrDesDir 0 "DrvrDesDir1_Undefd" 1 "DrvrDesDir1_Fwd" 2 "DrvrDesDir1_Rvs" 3 "DrvrDesDir1_Neut" 4 "DrvrDesDir1_Resd0" 5 "DrvrDesDir1_Resd1" 6 "DrvrDesDir1_Resd2" 7 "DrvrDesDir1_Resd3" ;
VAL_ 240 FltEgyCnsWdSts 0 "FltEgyCns1_NoFlt" 1 "FltEgyCns1_Flt" ;
VAL_ 240 NetCtrlrActvtPrio 0 "PrioHighNormal_PrioNormal" 1 "PrioHighNormal_PrioHigh" ;
VAL_ 240 UsgModSts 0 "UsgModSts1_UsgModAbdnd" 1 "UsgModSts1_UsgModInActv" 2 "UsgModSts1_UsgModCnvinc" 11 "UsgModSts1_UsgModActv" 13 "UsgModSts1_UsgModDrvg" ;
VAL_ 256 CamHeatrActv 0 "OnOff1_Off" 1 "OnOff1_On" ;
VAL_ 256 ExtrMirrFoldSetgPen 0 "IdPen_ProfUkwn" 1 "IdPen_Prof1" 2 "IdPen_Prof2" 3 "IdPen_Prof3" 4 "IdPen_Prof4" 5 "IdPen_Prof5" 6 "IdPen_Prof6" 7 "IdPen_Prof7" 8 "IdPen_Prof8" 9 "IdPen_Prof9" 10 "IdPen_Prof10" 11 "IdPen_Prof11" 12 "IdPen_Prof12" 13 "IdPen_Prof13" 14 "IdPen_Resd14" 15 "IdPen_ProfAll" ;
VAL_ 256 ExtrMirrFoldSetgSts 0 "OnOff1_Off" 1 "OnOff1_On" ;
VAL_ 256 ExtrMirrTiltSetg2IdPen 0 "IdPen_ProfUkwn" 1 "IdPen_Prof1" 2 "IdPen_Prof2" 3 "IdPen_Prof3" 4 "IdPen_Prof4" 5 "IdPen_Prof5" 6 "IdPen_Prof6" 7 "IdPen_Prof7" 8 "IdPen_Prof8" 9 "IdPen_Prof9" 10 "IdPen_Prof10" 11 "IdPen_Prof11" 12 "IdPen_Prof12" 13 "IdPen_Prof13" 14 "IdPen_Resd14" 15 "IdPen_ProfAll" ;
VAL_ 256 ExtrMirrTiltSetg2MirrDrvr 0 "OnOff2_On" 1 "OnOff2_Off" ;
VAL_ 256 ExtrMirrTiltSetg2MirrPass 0 "OnOff2_On" 1 "OnOff2_Off" ;
VAL_ 256 HoodSts 0 "DoorSts2_Ukwn" 1 "DoorSts2_Opend" 2 "DoorSts2_Clsd" ;
VAL_ 256 LockgCenStsForUsrFb 0 "LockSt2_Undefd" 1 "LockSt2_Opend" 2 "LockSt2_Clsd" 3 "LockSt2_Lockd" 4 "LockSt2_Safe" ;
VAL_ 256 LockgCenStsLockSt 0 "LockSt3_LockUndefd" 1 "LockSt3_LockUnlckd" 2 "LockSt3_LockTrUnlckd" 3 "LockSt3_LockLockd" ;
VAL_ 256 LockgCenStsUpdEve 0 "Boolean_FALSE" 1 "Boolean_TRUE" ;
VAL_ 256 LockgCenTrigSrc 0 "LockTrigSrc2_NoTrigSrc" 1 "LockTrigSrc2_KeyRem" 2 "LockTrigSrc2_Keyls" 3 "LockTrigSrc2_IntrSwt" 4 "LockTrigSrc2_SpdAut" 5 "LockTrigSrc2_TmrAut" 6 "LockTrigSrc2_Slam" 7 "LockTrigSrc2_Telm" 8 "LockTrigSrc2_Crash" ;
VAL_ 256 MirrDefrstSts 0 "ActrDefrstSts_Off" 1 "ActrDefrstSts_On" 2 "ActrDefrstSts_Limited" 3 "ActrDefrstSts_NotAvailable" 4 "ActrDefrstSts_TmrOff" 5 "ActrDefrstSts_AutoCdn" ;
VAL_ 256 WindDefrstFrntSts 0 "ActrDefrstSts_Off" 1 "ActrDefrstSts_On" 2 "ActrDefrstSts_Limited" 3 "ActrDefrstSts_NotAvailable" 4 "ActrDefrstSts_TmrOff" 5 "ActrDefrstSts_AutoCdn" ;
VAL_ 256 WinDefrstReSts 0 "ActrDefrstSts_Off" 1 "ActrDefrstSts_On" 2 "ActrDefrstSts_Limited" 3 "ActrDefrstSts_NotAvailable" 4 "ActrDefrstSts_TmrOff" 5 "ActrDefrstSts_AutoCdn" ;
VAL_ 320 HmiCmptmtAirDistbnFrnt 0 "HmiCmptmtAirDistbnFrnt_Flr" 1 "HmiCmptmtAirDistbnFrnt_Vent" 2 "HmiCmptmtAirDistbnFrnt_Defrst" 3 "HmiCmptmtAirDistbnFrnt_FlrDefrst" 4 "HmiCmptmtAirDistbnFrnt_FlrVent" 5 "HmiCmptmtAirDistbnFrnt_VentDefrst" 6 "HmiCmptmtAirDistbnFrnt_FlrVentDefrst" 7 "HmiCmptmtAirDistbnFrnt_Aut" ;
VAL_ 320 HmiDefrstMaxReq 0 "ActrReq_Off" 1 "ActrReq_On" 2 "ActrReq_AutOn" ;
VAL_ 320 HmiHvacFanLvlFrnt 0 "HmiHvacFanLvl_Off" 1 "HmiHvacFanLvl_Min" 2 "HmiHvacFanLvl_LvlMan1" 3 "HmiHvacFanLvl_LvlMan2" 4 "HmiHvacFanLvl_LvlMan3" 5 "HmiHvacFanLvl_LvlMan4" 6 "HmiHvacFanLvl_LvlMan5" 7 "HmiHvacFanLvl_LvlMan6" 8 "HmiHvacFanLvl_LvlMan7" 9 "HmiHvacFanLvl_LvlAutMinusMinus" 10 "HmiHvacFanLvl_LvlAutMinus" 11 "HmiHvacFanLvl_LvlAutoNorm" 12 "HmiHvacFanLvl_LvlAutPlus" 13 "HmiHvacFanLvl_LvlAutPlusPlus" 14 "HmiHvacFanLvl_Max" ;
VAL_ 320 HmiHvacFanLvlRe 0 "HmiHvacFanLvl_Off" 1 "HmiHvacFanLvl_Min" 2 "HmiHvacFanLvl_LvlMan1" 3 "HmiHvacFanLvl_LvlMan2" 4 "HmiHvacFanLvl_LvlMan3" 5 "HmiHvacFanLvl_LvlMan4" 6 "HmiHvacFanLvl_LvlMan5" 7 "HmiHvacFanLvl_LvlMan6" 8 "HmiHvacFanLvl_LvlMan7" 9 "HmiHvacFanLvl_LvlAutMinusMinus" 10 "HmiHvacFanLvl_LvlAutMinus" 11 "HmiHvacFanLvl_LvlAutoNorm" 12 "HmiHvacFanLvl_LvlAutPlus" 13 "HmiHvacFanLvl_LvlAutPlusPlus" 14 "HmiHvacFanLvl_Max" ;
VAL_ 320 HmiHvacRecircCmd 0 "HmiHvacRecircCmd_Aut" 1 "HmiHvacRecircCmd_AutWithAirQly" 2 "HmiHvacRecircCmd_RecircFull" ;
VAL_ 320 HmiHvacReCtrl 0 "HmiHvacReCtrl_Off" 1 "HmiHvacReCtrl_OffWithNoOccpt" 2 "HmiHvacReCtrl_On" ;
VAL_ 320 ModOnLiCmd 0 "Boolean_FALSE" 1 "Boolean_TRUE" ;
VAL_ 320 ModOnLiTintgCmd 0 "AmbLiTintg_T" 1 "AmbLiTintg_Off" 2 "AmbLiTintg_Tintg1" 3 "AmbLiTintg_Tintg2" 4 "AmbLiTintg_Tintg3" 5 "AmbLiTintg_Tintg4" 6 "AmbLiTintg_Tintg5" 7 "AmbLiTintg_Tintg6" 8 "AmbLiTintg_Tintg7" ;
VAL_ 384 ActvnOfTrlrLiRvsg 0 "OnOff1_Off" 1 "OnOff1_On" ;
VAL_ 384 ClimaEcoModRqrd 0 "OnOff1_Off" 1 "OnOff1_On" ;
VAL_ 384 HeatrDurgDrvgReqd 0 "OffOnAut1_Off" 1 "OffOnAut1_On" 2 "OffOnAut1_Aut" ;
VAL_ 384 HmiCmptmtCoolgReq 0 "HmiCmptmtCoolgReq_Off" 1 "HmiCmptmtCoolgReq_Auto" ;
VAL_ 384 HmiCmptmtTSpSpclForRowFirstLe 0 "HmiCmptmtTSpSpcl_Norm" 1 "HmiCmptmtTSpSpcl_Lo" 2 "HmiCmptmtTSpSpcl_Hi" ;
VAL_ 384 HmiCmptmtTSpSpclForRowFirstRi 0 "HmiCmptmtTSpSpcl_Norm" 1 "HmiCmptmtTSpSpcl_Lo" 2 "HmiCmptmtTSpSpcl_Hi" ;
VAL_ 384 HmiCmptmtTSpSpclForRowSecLe 0 "HmiCmptmtTSpSpcl_Norm" 1 "HmiCmptmtTSpSpcl_Lo" 2 "HmiCmptmtTSpSpcl_Hi" ;
VAL_ 384 HmiCmptmtTSpSpclForRowSecRi 0 "HmiCmptmtTSpSpcl_Norm" 1 "HmiCmptmtTSpSpcl_Lo" 2 "HmiCmptmtTSpSpcl_Hi" ;
VAL_ 384 SeatSwtLeSigThrd 0 "SwtVertSts1_Idle" 1 "SwtVertSts1_Up" 2 "SwtVertSts1_Dwn" ;
VAL_ 384 SeatSwtRiSigThrd 0 "SwtVertSts1_Idle" 1 "SwtVertSts1_Up" 2 "SwtVertSts1_Dwn" ;
VAL_ 400 DshbTQf 0 "SunSnsrQf_SnsrDataUndefd" 1 "SunSnsrQf_Resd" 2 "SunSnsrQf_SnsrDataNotOk" 3 "SunSnsrQf_SnsrDataOk" ;
VAL_ 400 SunAziQf 0 "SunSnsrQf_SnsrDataUndefd" 1 "SunSnsrQf_Resd" 2 "SunSnsrQf_SnsrDataNotOk" 3 "SunSnsrQf_SnsrDataOk" ;
VAL_ 400 SunDataSunElevnCmpQf 0 "SunSnsrQf_SnsrDataUndefd" 1 "SunSnsrQf_Resd" 2 "SunSnsrQf_SnsrDataNotOk" 3 "SunSnsrQf_SnsrDataOk" ;
VAL_ 400 SunElevnQf 0 "SunSnsrQf_SnsrDataUndefd" 1 "SunSnsrQf_Resd" 2 "SunSnsrQf_SnsrDataNotOk" 3 "SunSnsrQf_SnsrDataOk" ;
VAL_ 400 SunLoadQF 0 "SunSnsrQf_SnsrDataUndefd" 1 "SunSnsrQf_Resd" 2 "SunSnsrQf_SnsrDataNotOk" 3 "SunSnsrQf_SnsrDataOk" ;
VAL_ 432 CnclHldChrgReq 0 "CnclHldChrgReq_AllowDelay" 1 "CnclHldChrgReq_CancelDelay" ;
VAL_ 432 CoolgLimd 0 "Flg1_Rst" 1 "Flg1_Set" ;
VAL_ 432 DiagcHvacCooltVlvErr 0 "Err1_NoErr" 1 "Err1_Err" ;
VAL_ 432 ErsStrtRes 0 "ErsStrtRes_ErsStrtNotSet" 1 "ErsStrtRes_ErsStrtSuccess" 2 "ErsStrtRes_ErsStrtInhMaxNoStart" 3 "ErsStrtRes_ErsStrtInhCarUnlocked" 4 "ErsStrtRes_ErsStrtInhKeyInCar" 5 "ErsStrtRes_ErsStrtInhDoorOpen" 6 "ErsStrtRes_ErsStrtInhHoodOpen" 7 "ErsStrtRes_ErsStrtInhGearNotP" 8 "ErsStrtRes_ErsStrtInhUserInCar" 9 "ErsStrtRes_ErsStrtInhPedalPressed" 10 "ErsStrtRes_ErsStrtInhLoFuel" 11 "ErsStrtRes_ErsStrtInhLoBatt" 12 "ErsStrtRes_ErsStrtInhEngCoolant" 13 "ErsStrtRes_ErsStrtInhEngFault" 14 "ErsStrtRes_ErsStrtInhOther" 15 "ErsStrtRes_ErsStrtAbrtEngFault" 16 "ErsStrtRes_ErsStrtAbrtEngCoolant" 17 "ErsStrtRes_ErsStrtAbrtLoFuel" 18 "ErsStrtRes_ErsStrtAbrtLoBatt" 19 "ErsStrtRes_ErsStrtAbrtOther" ;
VAL_ 432 EvaprVlvReqRe 0 "OnOff1_Off" 1 "OnOff1_On" ;
VAL_ 432 FuTankPOkForFuHeatr 0 "OnOff1_Off" 1 "OnOff1_On" ;
VAL_ 432 MirrDefrstAtDrvrCmd 0 "OnOff1_Off" 1 "OnOff1_On" ;
VAL_ 432 MirrDefrstAtPassCmd 0 "OnOff1_Off" 1 "OnOff1_On" ;
VAL_ 432 VehSpdLgtSafeQf 0 "GenQf1_UndefindDataAccur" 1 "GenQf1_TmpUndefdData" 2 "GenQf1_DataAccurNotWithinSpcn" 3 "GenQf1_AccurData" ;
VAL_ 496 CmptmtCoolgSts 0 "CmptmtCoolgSts_OffNoReq" 1 "CmptmtCoolgSts_OffByEvaprTLo" 2 "CmptmtCoolgSts_OffByPLo" 3 "CmptmtCoolgSts_OffByAmbTOutOfRng" 4 "CmptmtCoolgSts_OffBySysFailr" 5 "CmptmtCoolgSts_OffByLoadCut" 6 "CmptmtCoolgSts_OnWithBattCoolg" 7 "CmptmtCoolgSts_On" ;
VAL_ 496 EngOilLvlSts 0 "EngOilLvlSts1_OilLvlOk" 1 "EngOilLvlSts1_OilLvlLo1" 2 "EngOilLvlSts1_OilLvlLo2" 3 "EngOilLvlSts1_OilLvlHi" 4 "EngOilLvlSts1_OilLvlSrvRqrd" 5 "EngOilLvlSts1_Resd" ;
VAL_ 496 HmiSeatHeatgForRowFirstLe 0 "SeatClimaLvl_Off" 1 "SeatClimaLvl_Lvl1" 2 "SeatClimaLvl_Lvl2" 3 "SeatClimaLvl_Lvl3" ;
VAL_ 496 HmiSeatHeatgForRowFirstRi 0 "SeatClimaLvl_Off" 1 "SeatClimaLvl_Lvl1" 2 "SeatClimaLvl_Lvl2" 3 "SeatClimaLvl_Lvl3" ;
VAL_ 496 HmiSeatHeatgForRowSecLe 0 "SeatClimaLvl_Off" 1 "SeatClimaLvl_Lvl1" 2 "SeatClimaLvl_Lvl2" 3 "SeatClimaLvl_Lvl3" ;
VAL_ 496 HmiSeatHeatgForRowSecRi 0 "SeatClimaLvl_Off" 1 "SeatClimaLvl_Lvl1" 2 "SeatClimaLvl_Lvl2" 3 "SeatClimaLvl_Lvl3" ;
VAL_ 496 HmiSeatVentnForRowFirstLe 0 "SeatClimaLvl_Off" 1 "SeatClimaLvl_Lvl1" 2 "SeatClimaLvl_Lvl2" 3 "SeatClimaLvl_Lvl3" ;
VAL_ 496 HmiSeatVentnForRowFirstRi 0 "SeatClimaLvl_Off" 1 "SeatClimaLvl_Lvl1" 2 "SeatClimaLvl_Lvl2" 3 "SeatClimaLvl_Lvl3" ;
VAL_ 496 HvClimaCmd 0 "HVBattChargnCmd_OK" 1 "HVBattChargnCmd_NOK" 2 "HVBattChargnCmd_INIT" 3 "HVBattChargnCmd_HOLD" ;
VAL_ 496 SunCurtPosnSts 0 "WinAndRoofAndCurtPosnTyp_PosnUkwn" 1 "WinAndRoofAndCurtPosnTyp_ClsFull" 2 "WinAndRoofAndCurtPosnTyp_PercOpen4" 3 "WinAndRoofAndCurtPosnTyp_PercOpen8" 4 "WinAndRoofAndCurtPosnTyp_PercOpen12" 5 "WinAndRoofAndCurtPosnTyp_PercOpen16" 6 "WinAndRoofAndCurtPosnTyp_PercOpen20" 7 "WinAndRoofAndCurtPosnTyp_PercOpen24" 8 "WinAndRoofAndCurtPosnTyp_PercOpen28" 9 "WinAndRoofAndCurtPosnTyp_PercOpen32" 10 "WinAndRoofAndCurtPosnTyp_PercOpen36" 11 "WinAndRoofAndCurtPosnTyp_PercOpen40" 12 "WinAndRoofAndCurtPosnTyp_PercOpen44" 13 "WinAndRoofAndCurtPosnTyp_PercOpen48" 14 "WinAndRoofAndCurtPosnTyp_PercOpen52" 15 "WinAndRoofAndCurtPosnTyp_PercOpen56" 16 "WinAndRoofAndCurtPosnTyp_PercOpen60" 17 "WinAndRoofAndCurtPosnTyp_PercOpen64" 18 "WinAndRoofAndCurtPosnTyp_PercOpen68" 19 "WinAndRoofAndCurtPosnTyp_PercOpen72" 20 "WinAndRoofAndCurtPosnTyp_PercOpen76" 21 "WinAndRoofAndCurtPosnTyp_PercOpen80" 22 "WinAndRoofAndCurtPosnTyp_PercOpen84" 23 "WinAndRoofAndCurtPosnTyp_PercOpen88" 24 "WinAndRoofAndCurtPosnTyp_PercOpen92" 25 "WinAndRoofAndCurtPosnTyp_PercOpen96" 26 "WinAndRoofAndCurtPosnTyp_OpenFull" 27 "WinAndRoofAndCurtPosnTyp_Resd1" 28 "WinAndRoofAndCurtPosnTyp_Resd2" 29 "WinAndRoofAndCurtPosnTyp_Resd3" 30 "WinAndRoofAndCurtPosnTyp_Resd4" 31 "WinAndRoofAndCurtPosnTyp_Movg" ;
SIG_GROUP_ 80 HvacEvaprTFrntGroup 1 : HvacEvaprTFrnt HvacEvaprTFrntQf;
SIG_GROUP_ 336 AmbTEstimd 1 : AmbTEstimdAmbTEstimd AmbTEstimdAmbTEstimdQf;
SIG_GROUP_ 336 DefrstReq 1 : MirrDefrstReq WinDefrstFrntReq WinDefrstReReq;
SIG_GROUP_ 368 WindDewTUppr 1 : WindDewTUpprDewT WindDewTUpprDewTQf;
SIG_GROUP_ 448 EvaprVlvReStsExtd 1 : EvaprVlvReStsExtdDiagcStsForCirc EvaprVlvReStsExtdDiagcStsForShoT EvaprVlvReStsExtdDiagcStsFo_0000;
SIG_GROUP_ 448 WindTGroup 1 : WindTWindT WindTWindTQf;
SIG_GROUP_ 597 CmptmtAirTEstimdExtd 1 : CmptmtAirTEstimdExtdComptmtT CmptmtAirTEstimdExtdQlyFlg;
SIG_GROUP_ 800 VFCVectorCCM 1 : VFCVectorCCMGrp1 VFCVectorCCMGrp2 VFCVectorCCMGrp3;
SIG_GROUP_ 1122 HmiCmptmtTSpM1 1 : HmiCmptmtTSpForRowFirstLeM1 HmiCmptmtTSpForRowFirstRiM1 HmiCmptmtTSpForRowSecLeM1 HmiCmptmtTSpForRowSecRiM1 HmiCmptmtTSpSpclForRowFirstLeM1 HmiCmptmtTSpSpclForRowFirstRiM1 HmiCmptmtTSpSpclForRowSecLeM1 HmiCmptmtTSpSpclForRowSecRiM1;
SIG_GROUP_ 1449 EndOfLineSigOver 1 : EndOfLineSigOverByte0 EndOfLineSigOverByte1 EndOfLineSigOverByte2 EndOfLineSigOverByte3 EndOfLineSigOverByte4 EndOfLineSigOverByte5 EndOfLineSigOverByte6 EndOfLineSigOverByte7;
SIG_GROUP_ 32 ActvnOfHndlDoorLi 1 : HndlDoorLiDrvr HndlDoorLiDrvrRe HndlDoorLiPass HndlDoorLiPassRe;
SIG_GROUP_ 32 IndcrTurnCmd1WdCmd 1 : IndcrTurnCmd1WdHzrdTelltl IndcrTurnCmd1WdIndcrTrig;
SIG_GROUP_ 32 IntrLiCmdGroup 1 : IntrLiActvn1 IntrLiRoofDim IntrLiRoofDmdOff;
SIG_GROUP_ 32 LoadAndStoreReq 1 : EveMemPosn LoadAndStoreReqIdPen LoadAndStoreReqInOutEasy MemPosn;
SIG_GROUP_ 64 PassLoadAndStoreReq 1 : PassLoadAndStoreReqErgoPosn PassLoadAndStoreReqErgoSetgEve;
SIG_GROUP_ 64 TrOpenerReq 1 : TrOpenerReqTrOpenerReq TrOpenerReqTrOpenerTrigSrc;
SIG_GROUP_ 64 VehMtnStSafeGroup 1 : VehMtnStChks VehMtnStCntr VehMtnStSafe;
SIG_GROUP_ 245 RecOfImpctSafe 1 : RecOfImpctSafeChks RecOfImpctSafeCntr RecOfImpctSafeCrashFrnt RecOfImpctSafeCrashLargeAnimal RecOfImpctSafeCrashOffroadA RecOfImpctSafeCrashOffroadD RecOfImpctSafeCrashOffroadRT RecOfImpctSafeCrashOffroadRTseve RecOfImpctSafeCrashOz RecOfImpctSafeCrashPed RecOfImpctSafeCrashRe RecOfImpctSafeCrashRollovr RecOfImpctSafeCrashSideLe RecOfImpctSafeCrashSideRi RecOfImpctSafeCrashState RecOfImpctSafeImpctDvx RecOfImpctSafeImpctDvy RecOfImpctSafeImpctRollAg RecOfImpctSafeVehOri;
SIG_GROUP_ 176 BltLockStAtDrvr 1 : BltLockStAtDrvrForBltLockSt1 BltLockStAtDrvrForDevErrSts2;
SIG_GROUP_ 176 BltLockStAtPass 1 : BltLockStAtPassForBltLockSt1 BltLockStAtPassForBltLockSts;
SIG_GROUP_ 176 BltLockStAtRowSecLe 1 : BltLockStAtRowSecLeForBltLockEqu BltLockStAtRowSecLeForBltLockSt1 BltLockStAtRowSecLeForBltLockSts;
SIG_GROUP_ 176 BltLockStAtRowSecMid 1 : BltLockStAtRowSecMidForBltLockEq BltLockStAtRowSecMidForBltLockSt BltLockStAtRowSecMidForBltL_0000;
SIG_GROUP_ 176 BltLockStAtRowSecRi 1 : BltLockStAtRowSecRiForBltLockEqu BltLockStAtRowSecRiForBltLockSt1 BltLockStAtRowSecRiForBltLockSts;
SIG_GROUP_ 176 BltLockStAtRowThrdLe 1 : BltLockStAtRowThrdLeForBltLockEq BltLockStAtRowThrdLeForBltLockSt BltLockStAtRowThrdLeForBltL_0000;
SIG_GROUP_ 176 BltLockStAtRowThrdRi 1 : BltLockStAtRowThrdRiForBltLockEq BltLockStAtRowThrdRiForBltLockSt BltLockStAtRowThrdRiForBltL_0000;
SIG_GROUP_ 288 ImobRemMgrChk 1 : ImobDataRemMgrChk0 ImobDataRemMgrChk1 ImobDataRemMgrChk2 ImobDataRemMgrChk3 ImobDataRemMgrChk4 ImobRemMgrChkSts;
SIG_GROUP_ 288 ImobVehRemMgrSts1 1 : ImobVehRemMgrSts SpdLimRemMgrSts;
SIG_GROUP_ 224 DrvrSeatDispMassgFct 1 : DrvrSeatDispMassgFctMassgInten DrvrSeatDispMassgFctMassgProg DrvrSeatDispMassgFctMassgSpdLvl DrvrSeatDispMassgFctOnOff;
SIG_GROUP_ 224 PassSeatDispMassgFct 1 : PassSeatDispMassgFctMassgInten PassSeatDispMassgFctMassgProg PassSeatDispMassgFctMassgSpdLvl PassSeatDispMassgFctOnOff;
SIG_GROUP_ 240 NetCtrlrActvt 1 : NetCtrlrActvtPrio NetCtrlrActvtResourceGroup;
SIG_GROUP_ 240 VehModMngtGlbSafe1 1 : CarModSts1 CarModSubtypWdCarModSubtyp EgyLvlElecMai EgyLvlElecSubtyp FltEgyCnsWdSts PwrLvlElecMai PwrLvlElecSubtyp UsgModSts VehModMngtGlbSafe1Chks VehModMngtGlbSafe1Cntr;
SIG_GROUP_ 256 DefrstSts 1 : MirrDefrstSts WindDefrstFrntSts WinDefrstReSts;
SIG_GROUP_ 256 ExtrMirrFoldSetg 1 : ExtrMirrFoldSetgPen ExtrMirrFoldSetgSts;
SIG_GROUP_ 256 ExtrMirrTiltSetg2 1 : ExtrMirrTiltSetg2IdPen ExtrMirrTiltSetg2MirrDrvr ExtrMirrTiltSetg2MirrPass;
SIG_GROUP_ 256 LockgCenSts 1 : LockgCenStsLockSt LockgCenStsUpdEve LockgCenTrigSrc;
SIG_GROUP_ 384 HmiCmptmtTSp 1 : HmiCmptmtTSpForRowFirstLe HmiCmptmtTSpForRowFirstRi HmiCmptmtTSpForRowSecLe HmiCmptmtTSpForRowSecRi HmiCmptmtTSpSpclForRowFirstLe HmiCmptmtTSpSpclForRowFirstRi HmiCmptmtTSpSpclForRowSecLe HmiCmptmtTSpSpclForRowSecRi;
SIG_GROUP_ 400 SunData 1 : DshbT DshbTQf SunAzi SunAziQf SunDataSunElevnCmp SunDataSunElevnCmpQf SunElevn SunElevnQf SunLoad SunLoadQF;
SIG_GROUP_ 432 CoolgLoadGroup 1 : CoolgLimd CoolgLoad;
SIG_GROUP_ 432 VehSpdLgtSafeGroup 1 : VehSpdLgtSafe VehSpdLgtSafeChks VehSpdLgtSafeCntr VehSpdLgtSafeQf;
SIG_GROUP_ 496 HmiSeatClima 1 : HmiSeatHeatgForRowFirstLe HmiSeatHeatgForRowFirstRi HmiSeatHeatgForRowSecLe HmiSeatHeatgForRowSecRi HmiSeatVentnForRowFirstLe HmiSeatVentnForRowFirstRi;
